AUTOSAR XML (schema 4-2-2)
standard types defined: sint16, float32, uint8, boolean, uint16
package /STCW_pkg/STCW_swc
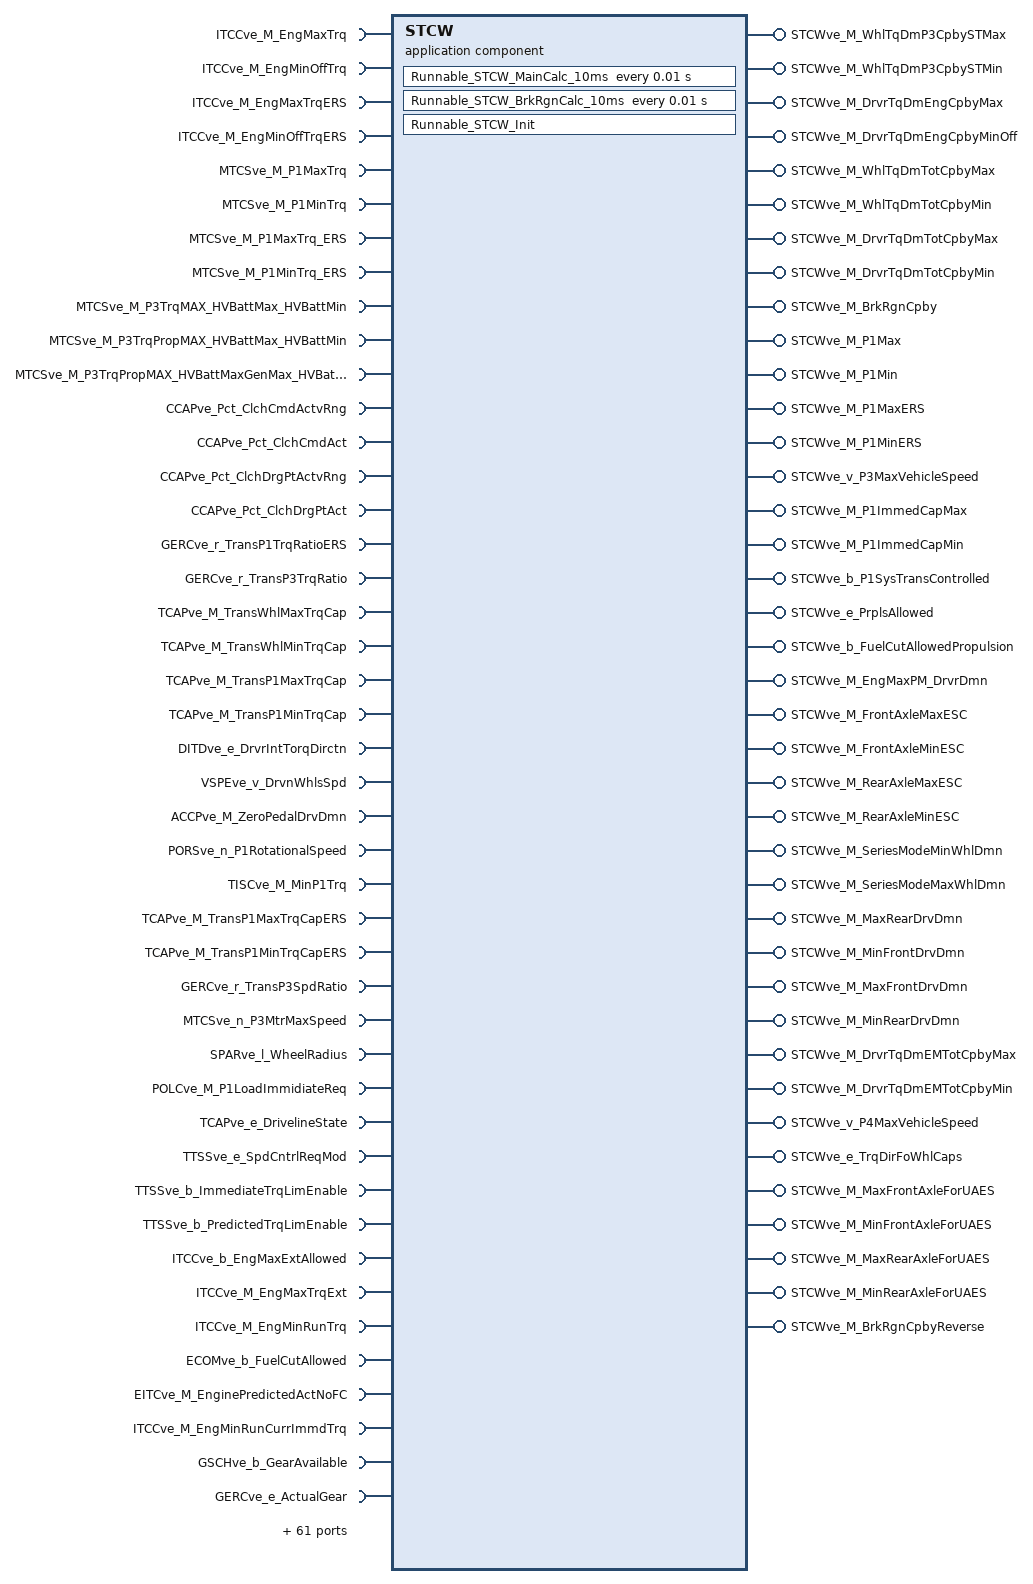
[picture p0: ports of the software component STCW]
  application sw component type STCW
    105 x require port:
      ITCCve_M_EngMaxTrq: nonqueued-receiver-com-spec{data-element=ITCCve_M_EngMaxTrq, init-value=0}, required-interface=ITCCve_M_EngMaxTrq
      ITCCve_M_EngMinOffTrq: nonqueued-receiver-com-spec{data-element=ITCCve_M_EngMinOffTrq, init-value=0}, required-interface=ITCCve_M_EngMinOffTrq
      ITCCve_M_EngMaxTrqERS: nonqueued-receiver-com-spec{data-element=ITCCve_M_EngMaxTrqERS, init-value=0}, required-interface=ITCCve_M_EngMaxTrqERS
      ITCCve_M_EngMinOffTrqERS: nonqueued-receiver-com-spec{data-element=ITCCve_M_EngMinOffTrqERS, init-value=0}, required-interface=ITCCve_M_EngMinOffTrqERS
      MTCSve_M_P1MaxTrq: nonqueued-receiver-com-spec{data-element=MTCSve_M_P1MaxTrq, init-value=0}, required-interface=MTCSve_M_P1MaxTrq
      MTCSve_M_P1MinTrq: nonqueued-receiver-com-spec{data-element=MTCSve_M_P1MinTrq, init-value=0}, required-interface=MTCSve_M_P1MinTrq
      MTCSve_M_P1MaxTrq_ERS: nonqueued-receiver-com-spec{data-element=MTCSve_M_P1MaxTrq_ERS, init-value=0}, required-interface=MTCSve_M_P1MaxTrq_ERS
      MTCSve_M_P1MinTrq_ERS: nonqueued-receiver-com-spec{data-element=MTCSve_M_P1MinTrq_ERS, init-value=0}, required-interface=MTCSve_M_P1MinTrq_ERS
      MTCSve_M_P3TrqMAX_HVBattMax_HVBattMin: nonqueued-receiver-com-spec{data-element=MTCSve_M_P3TrqMAX_HVBattMax_HVBattMin, init-value=0}, required-interface=MTCSve_M_P3TrqMAX_HVBattMax_HVBattMin
      MTCSve_M_P3TrqPropMAX_HVBattMax_HVBattMin: nonqueued-receiver-com-spec{data-element=MTCSve_M_P3TrqPropMAX_HVBattMax_HVBattMin, init-value=0}, required-interface=MTCSve_M_P3TrqPropMAX_HVBattMax_HVBattMin
      MTCSve_M_P3TrqPropMAX_HVBattMaxGenMax_HVBattMin: nonqueued-receiver-com-spec{data-element=MTCSve_M_P3TrqPropMAX_HVBattMaxGenMax_HVBattMin, init-value=0}, required-interface=MTCSve_M_P3TrqPropMAX_HVBattMaxGenMax_HVBattMin
      CCAPve_Pct_ClchCmdActvRng: nonqueued-receiver-com-spec{data-element=CCAPve_Pct_ClchCmdActvRng, init-value=0}, required-interface=CCAPve_Pct_ClchCmdActvRng
      CCAPve_Pct_ClchCmdAct: nonqueued-receiver-com-spec{data-element=CCAPve_Pct_ClchCmdAct, init-value=0}, required-interface=CCAPve_Pct_ClchCmdAct
      CCAPve_Pct_ClchDrgPtActvRng: nonqueued-receiver-com-spec{data-element=CCAPve_Pct_ClchDrgPtActvRng, init-value=0}, required-interface=CCAPve_Pct_ClchDrgPtActvRng
      CCAPve_Pct_ClchDrgPtAct: nonqueued-receiver-com-spec{data-element=CCAPve_Pct_ClchDrgPtAct, init-value=0}, required-interface=CCAPve_Pct_ClchDrgPtAct
      GERCve_r_TransP1TrqRatioERS: nonqueued-receiver-com-spec{data-element=GERCve_r_TransP1TrqRatioERS, init-value=0}, required-interface=GERCve_r_TransP1TrqRatioERS
      GERCve_r_TransP3TrqRatio: nonqueued-receiver-com-spec{data-element=GERCve_r_TransP3TrqRatio, init-value=0}, required-interface=GERCve_r_TransP3TrqRatio
      TCAPve_M_TransWhlMaxTrqCap: nonqueued-receiver-com-spec{data-element=TCAPve_M_TransWhlMaxTrqCap, init-value=0}, required-interface=TCAPve_M_TransWhlMaxTrqCap
      TCAPve_M_TransWhlMinTrqCap: nonqueued-receiver-com-spec{data-element=TCAPve_M_TransWhlMinTrqCap, init-value=0}, required-interface=TCAPve_M_TransWhlMinTrqCap
      TCAPve_M_TransP1MaxTrqCap: nonqueued-receiver-com-spec{data-element=TCAPve_M_TransP1MaxTrqCap, init-value=0}, required-interface=TCAPve_M_TransP1MaxTrqCap
      TCAPve_M_TransP1MinTrqCap: nonqueued-receiver-com-spec{data-element=TCAPve_M_TransP1MinTrqCap, init-value=0}, required-interface=TCAPve_M_TransP1MinTrqCap
      DITDve_e_DrvrIntTorqDirctn: nonqueued-receiver-com-spec{data-element=DITDve_e_DrvrIntTorqDirctn, init-value=DITDce_e_Undefined}, required-interface=DITDve_e_DrvrIntTorqDirctn
      VSPEve_v_DrvnWhlsSpd: nonqueued-receiver-com-spec{data-element=VSPEve_v_DrvnWhlsSpd, init-value=0}, required-interface=VSPEve_v_DrvnWhlsSpd
      ACCPve_M_ZeroPedalDrvDmn: nonqueued-receiver-com-spec{data-element=ACCPve_M_ZeroPedalDrvDmn, init-value=0}, required-interface=ACCPve_M_ZeroPedalDrvDmn
      PORSve_n_P1RotationalSpeed: nonqueued-receiver-com-spec{data-element=PORSve_n_P1RotationalSpeed, init-value=0}, required-interface=PORSve_n_P1RotationalSpeed
      TISCve_M_MinP1Trq: nonqueued-receiver-com-spec{data-element=TISCve_M_MinP1Trq, init-value=0}, required-interface=TISCve_M_MinP1Trq
      TCAPve_M_TransP1MaxTrqCapERS: nonqueued-receiver-com-spec{data-element=TCAPve_M_TransP1MaxTrqCapERS, init-value=0}, required-interface=TCAPve_M_TransP1MaxTrqCapERS
      TCAPve_M_TransP1MinTrqCapERS: nonqueued-receiver-com-spec{data-element=TCAPve_M_TransP1MinTrqCapERS, init-value=0}, required-interface=TCAPve_M_TransP1MinTrqCapERS
      GERCve_r_TransP3SpdRatio: nonqueued-receiver-com-spec{data-element=GERCve_r_TransP3SpdRatio, init-value=0}, required-interface=GERCve_r_TransP3SpdRatio
      MTCSve_n_P3MtrMaxSpeed: nonqueued-receiver-com-spec{data-element=MTCSve_n_P3MtrMaxSpeed, init-value=0}, required-interface=MTCSve_n_P3MtrMaxSpeed
      SPARve_l_WheelRadius: nonqueued-receiver-com-spec{data-element=SPARve_l_WheelRadius, init-value=0}, required-interface=SPARve_l_WheelRadius
      POLCve_M_P1LoadImmidiateReq: nonqueued-receiver-com-spec{data-element=POLCve_M_P1LoadImmidiateReq, init-value=0}, required-interface=POLCve_M_P1LoadImmidiateReq
      TCAPve_e_DrivelineState: nonqueued-receiver-com-spec{data-element=TCAPve_e_DrivelineState, init-value=TCAPce_e_Open}, required-interface=TCAPve_e_DrivelineState
      TTSSve_e_SpdCntrlReqMod: nonqueued-receiver-com-spec{data-element=TTSSve_e_SpdCntrlReqMod, init-value=TTSSce_e_SpdCntrlInactive}, required-interface=TTSSve_e_SpdCntrlReqMod
      TTSSve_b_ImmediateTrqLimEnable: nonqueued-receiver-com-spec{data-element=TTSSve_b_ImmediateTrqLimEnable, init-value=0}, required-interface=TTSSve_b_ImmediateTrqLimEnable
      TTSSve_b_PredictedTrqLimEnable: nonqueued-receiver-com-spec{data-element=TTSSve_b_PredictedTrqLimEnable, init-value=0}, required-interface=TTSSve_b_PredictedTrqLimEnable
      ITCCve_b_EngMaxExtAllowed: nonqueued-receiver-com-spec{data-element=ITCCve_b_EngMaxExtAllowed, init-value=0}, required-interface=ITCCve_b_EngMaxExtAllowed
      ITCCve_M_EngMaxTrqExt: nonqueued-receiver-com-spec{data-element=ITCCve_M_EngMaxTrqExt, init-value=0}, required-interface=ITCCve_M_EngMaxTrqExt
      ITCCve_M_EngMinRunTrq: nonqueued-receiver-com-spec{data-element=ITCCve_M_EngMinRunTrq, init-value=0}, required-interface=ITCCve_M_EngMinRunTrq
      ECOMve_b_FuelCutAllowed: nonqueued-receiver-com-spec{data-element=ECOMve_b_FuelCutAllowed, init-value=0}, required-interface=ECOMve_b_FuelCutAllowed
      EITCve_M_EnginePredictedActNoFC: nonqueued-receiver-com-spec{data-element=EITCve_M_EnginePredictedActNoFC, init-value=0}, required-interface=EITCve_M_EnginePredictedActNoFC
      ITCCve_M_EngMinRunCurrImmdTrq: nonqueued-receiver-com-spec{data-element=ITCCve_M_EngMinRunCurrImmdTrq, init-value=0}, required-interface=ITCCve_M_EngMinRunCurrImmdTrq
      GSCHve_b_GearAvailable: nonqueued-receiver-com-spec{data-element=GSCHve_b_GearAvailable, init-value=0}, required-interface=GSCHve_b_GearAvailable
      GERCve_e_ActualGear: nonqueued-receiver-com-spec{data-element=GERCve_e_ActualGear, init-value=DGPSce_e_UndefinedGear}, required-interface=GERCve_e_ActualGear
      ITCCve_M_EngMinRunTrq_LT: nonqueued-receiver-com-spec{data-element=ITCCve_M_EngMinRunTrq_LT, init-value=0}, required-interface=ITCCve_M_EngMinRunTrq_LT
      DTOSve_M_CmdPrplsFiltWhlDmnImmediate: nonqueued-receiver-com-spec{data-element=DTOSve_M_CmdPrplsFiltWhlDmnImmediate, init-value=0}, required-interface=DTOSve_M_CmdPrplsFiltWhlDmnImmediate
      DOSRve_M_ForceChargeTorque: nonqueued-receiver-com-spec{data-element=DOSRve_M_ForceChargeTorque, init-value=0}, required-interface=DOSRve_M_ForceChargeTorque
      FDMAve_b_ForceBrakeRegenerationTorqueOff: nonqueued-receiver-com-spec{data-element=FDMAve_b_ForceBrakeRegenerationTorqueOff, init-value=0}, required-interface=FDMAve_b_ForceBrakeRegenerationTorqueOff
      SWINve_b_GearShiftActive: nonqueued-receiver-com-spec{data-element=SWINve_b_GearShiftActive, init-value=0}, required-interface=SWINve_b_GearShiftActive
      DPSCve_e_VehicleReqState: nonqueued-receiver-com-spec{data-element=DPSCve_e_VehicleReqState, init-value=DPSCce_e_VehMd_Off}, required-interface=DPSCve_e_VehicleReqState
      PWRMve_e_SysPwrMd: nonqueued-receiver-com-spec{data-element=PWRMve_e_SysPwrMd, init-value=PWRMce_e_Lock}, required-interface=PWRMve_e_SysPwrMd
      PAFCve_e_ParkLockStatus: nonqueued-receiver-com-spec{data-element=PAFCve_e_ParkLockStatus, init-value=SWINce_e_ParkLockUndefined}, required-interface=PAFCve_e_ParkLockStatus
      FDMAve_b_ForcePropulsionAllowedToNotAllowed: nonqueued-receiver-com-spec{data-element=FDMAve_b_ForcePropulsionAllowedToNotAllowed, init-value=0}, required-interface=FDMAve_b_ForcePropulsionAllowedToNotAllowed
      DPSCve_e_VehicleActState: nonqueued-receiver-com-spec{data-element=DPSCve_e_VehicleActState, init-value=DPSCce_e_VehMd_Off}, required-interface=DPSCve_e_VehicleActState
      ECOMve_b_FuelCutGearShiftAllowed: nonqueued-receiver-com-spec{data-element=ECOMve_b_FuelCutGearShiftAllowed, init-value=0}, required-interface=ECOMve_b_FuelCutGearShiftAllowed
      DTOSve_b_FastResponseRequest: nonqueued-receiver-com-spec{data-element=DTOSve_b_FastResponseRequest, init-value=0}, required-interface=DTOSve_b_FastResponseRequest
      MTCSve_M_P3TrqPropMAX_GenMax_HVBattMin: nonqueued-receiver-com-spec{data-element=MTCSve_M_P3TrqPropMAX_GenMax_HVBattMin, init-value=0}, required-interface=MTCSve_M_P3TrqPropMAX_GenMax_HVBattMin
      MTCSve_M_P3TrqMAX_HVBattMaxGenMax_HVBattMin: nonqueued-receiver-com-spec{data-element=MTCSve_M_P3TrqMAX_HVBattMaxGenMax_HVBattMin, init-value=0}, required-interface=MTCSve_M_P3TrqMAX_HVBattMaxGenMax_HVBattMin
      MTCSve_M_P4TrqMAX_HVBattMaxGenMax_HVBattMin: nonqueued-receiver-com-spec{data-element=MTCSve_M_P4TrqMAX_HVBattMaxGenMax_HVBattMin, init-value=0}, required-interface=MTCSve_M_P4TrqMAX_HVBattMaxGenMax_HVBattMin
      BOREve_M_MaxBoostRequest: nonqueued-receiver-com-spec{data-element=BOREve_M_MaxBoostRequest, init-value=0}, required-interface=BOREve_M_MaxBoostRequest
      MTCSve_M_P4TrqPropMAX_GenMax_HVBattMin: nonqueued-receiver-com-spec{data-element=MTCSve_M_P4TrqPropMAX_GenMax_HVBattMin, init-value=0}, required-interface=MTCSve_M_P4TrqPropMAX_GenMax_HVBattMin
      MTCSve_M_P4TrqPropMAX_HVBattMax_HVBattMin: nonqueued-receiver-com-spec{data-element=MTCSve_M_P4TrqPropMAX_HVBattMax_HVBattMin, init-value=0}, required-interface=MTCSve_M_P4TrqPropMAX_HVBattMax_HVBattMin
      MTCSve_M_P4TrqPropMAX_HVBattMaxGenMax_HVBattMin: nonqueued-receiver-com-spec{data-element=MTCSve_M_P4TrqPropMAX_HVBattMaxGenMax_HVBattMin, init-value=0}, required-interface=MTCSve_M_P4TrqPropMAX_HVBattMaxGenMax_HVBattMin
      VSPEve_v_RearAxleWheelSpeed: nonqueued-receiver-com-spec{data-element=VSPEve_v_RearAxleWheelSpeed, init-value=0}, required-interface=VSPEve_v_RearAxleWheelSpeed
      GERCve_r_TransP4TrqRatio: nonqueued-receiver-com-spec{data-element=GERCve_r_TransP4TrqRatio, init-value=0}, required-interface=GERCve_r_TransP4TrqRatio
      MTCSve_M_P4TrqMAX_HVBattMax_HVBattMin: nonqueued-receiver-com-spec{data-element=MTCSve_M_P4TrqMAX_HVBattMax_HVBattMin, init-value=0}, required-interface=MTCSve_M_P4TrqMAX_HVBattMax_HVBattMin
      MTCSve_M_P3TrqMIN_HVBattMax_HVBattMin: nonqueued-receiver-com-spec{data-element=MTCSve_M_P3TrqMIN_HVBattMax_HVBattMin, init-value=0}, required-interface=MTCSve_M_P3TrqMIN_HVBattMax_HVBattMin
      MTCSve_M_P3TrqMIN_HVBattMaxGenMax_HVBattMin: nonqueued-receiver-com-spec{data-element=MTCSve_M_P3TrqMIN_HVBattMaxGenMax_HVBattMin, init-value=0}, required-interface=MTCSve_M_P3TrqMIN_HVBattMaxGenMax_HVBattMin
      MTCSve_M_P3TrqPropMIN_GenMax_HVBattMin: nonqueued-receiver-com-spec{data-element=MTCSve_M_P3TrqPropMIN_GenMax_HVBattMin, init-value=0}, required-interface=MTCSve_M_P3TrqPropMIN_GenMax_HVBattMin
      MTCSve_M_P3TrqPropMIN_HVBattMax_HVBattMin: nonqueued-receiver-com-spec{data-element=MTCSve_M_P3TrqPropMIN_HVBattMax_HVBattMin, init-value=0}, required-interface=MTCSve_M_P3TrqPropMIN_HVBattMax_HVBattMin
      MTCSve_M_P3TrqPropMIN_HVBattMaxGenMax_HVBattMin: nonqueued-receiver-com-spec{data-element=MTCSve_M_P3TrqPropMIN_HVBattMaxGenMax_HVBattMin, init-value=0}, required-interface=MTCSve_M_P3TrqPropMIN_HVBattMaxGenMax_HVBattMin
      MTCSve_M_P4TrqMIN_HVBattMax_HVBattMin: nonqueued-receiver-com-spec{data-element=MTCSve_M_P4TrqMIN_HVBattMax_HVBattMin, init-value=0}, required-interface=MTCSve_M_P4TrqMIN_HVBattMax_HVBattMin
      MTCSve_M_P4TrqMIN_HVBattMaxGenMax_HVBattMin: nonqueued-receiver-com-spec{data-element=MTCSve_M_P4TrqMIN_HVBattMaxGenMax_HVBattMin, init-value=0}, required-interface=MTCSve_M_P4TrqMIN_HVBattMaxGenMax_HVBattMin
      MTCSve_M_P4TrqPropMIN_GenMax_HVBattMin: nonqueued-receiver-com-spec{data-element=MTCSve_M_P4TrqPropMIN_GenMax_HVBattMin, init-value=0}, required-interface=MTCSve_M_P4TrqPropMIN_GenMax_HVBattMin
      MTCSve_M_P4TrqPropMIN_HVBattMax_HVBattMin: nonqueued-receiver-com-spec{data-element=MTCSve_M_P4TrqPropMIN_HVBattMax_HVBattMin, init-value=0}, required-interface=MTCSve_M_P4TrqPropMIN_HVBattMax_HVBattMin
      MTCSve_M_P4TrqPropMIN_HVBattMaxGenMax_HVBattMin: nonqueued-receiver-com-spec{data-element=MTCSve_M_P4TrqPropMIN_HVBattMaxGenMax_HVBattMin, init-value=0}, required-interface=MTCSve_M_P4TrqPropMIN_HVBattMaxGenMax_HVBattMin
      MTCSve_M_P3BrakeRegenMAXCap: nonqueued-receiver-com-spec{data-element=MTCSve_M_P3BrakeRegenMAXCap, init-value=0}, required-interface=MTCSve_M_P3BrakeRegenMAXCap
      MTCSve_M_P3BrakeRegenMINCap: nonqueued-receiver-com-spec{data-element=MTCSve_M_P3BrakeRegenMINCap, init-value=0}, required-interface=MTCSve_M_P3BrakeRegenMINCap
      MTCSve_M_P4BrakeRegenMAXCap: nonqueued-receiver-com-spec{data-element=MTCSve_M_P4BrakeRegenMAXCap, init-value=0}, required-interface=MTCSve_M_P4BrakeRegenMAXCap
      MTCSve_M_P4BrakeRegenMINCap: nonqueued-receiver-com-spec{data-element=MTCSve_M_P4BrakeRegenMINCap, init-value=0}, required-interface=MTCSve_M_P4BrakeRegenMINCap
      GERCve_r_TransP4SpdRatio: nonqueued-receiver-com-spec{data-element=GERCve_r_TransP4SpdRatio, init-value=0}, required-interface=GERCve_r_TransP4SpdRatio
      MTCSve_n_P4MtrMaxSpeed: nonqueued-receiver-com-spec{data-element=MTCSve_n_P4MtrMaxSpeed, init-value=0}, required-interface=MTCSve_n_P4MtrMaxSpeed
      MTCSve_M_P3LTrqPropMAX_HVBattMaxGenMax_HVBattMin: nonqueued-receiver-com-spec{data-element=MTCSve_M_P3LTrqPropMAX_HVBattMaxGenMax_HVBattMin, init-value=0}, required-interface=MTCSve_M_P3LTrqPropMAX_HVBattMaxGenMax_HVBattMin
      MTCSve_M_P3LTrqPropMIN_HVBattMaxGenMax_HVBattMin: nonqueued-receiver-com-spec{data-element=MTCSve_M_P3LTrqPropMIN_HVBattMaxGenMax_HVBattMin, init-value=0}, required-interface=MTCSve_M_P3LTrqPropMIN_HVBattMaxGenMax_HVBattMin
      MTCSve_M_P3RTrqPropMAX_HVBattMaxGenMax_HVBattMin: nonqueued-receiver-com-spec{data-element=MTCSve_M_P3RTrqPropMAX_HVBattMaxGenMax_HVBattMin, init-value=0}, required-interface=MTCSve_M_P3RTrqPropMAX_HVBattMaxGenMax_HVBattMin
      MTCSve_M_P3RTrqPropMIN_HVBattMaxGenMax_HVBattMin: nonqueued-receiver-com-spec{data-element=MTCSve_M_P3RTrqPropMIN_HVBattMaxGenMax_HVBattMin, init-value=0}, required-interface=MTCSve_M_P3RTrqPropMIN_HVBattMaxGenMax_HVBattMin
      MTCSve_M_P4LTrqPropMAX_HVBattMaxGenMax_HVBattMin: nonqueued-receiver-com-spec{data-element=MTCSve_M_P4LTrqPropMAX_HVBattMaxGenMax_HVBattMin, init-value=0}, required-interface=MTCSve_M_P4LTrqPropMAX_HVBattMaxGenMax_HVBattMin
      MTCSve_M_P4LTrqPropMIN_HVBattMaxGenMax_HVBattMin: nonqueued-receiver-com-spec{data-element=MTCSve_M_P4LTrqPropMIN_HVBattMaxGenMax_HVBattMin, init-value=0}, required-interface=MTCSve_M_P4LTrqPropMIN_HVBattMaxGenMax_HVBattMin
      MTCSve_M_P4RTrqPropMAX_HVBattMaxGenMax_HVBattMin: nonqueued-receiver-com-spec{data-element=MTCSve_M_P4RTrqPropMAX_HVBattMaxGenMax_HVBattMin, init-value=0}, required-interface=MTCSve_M_P4RTrqPropMAX_HVBattMaxGenMax_HVBattMin
      MTCSve_M_P4RTrqPropMIN_HVBattMaxGenMax_HVBattMin: nonqueued-receiver-com-spec{data-element=MTCSve_M_P4RTrqPropMIN_HVBattMaxGenMax_HVBattMin, init-value=0}, required-interface=MTCSve_M_P4RTrqPropMIN_HVBattMaxGenMax_HVBattMin
      TCAPve_M_TransP3MtrMaxTrqCap: nonqueued-receiver-com-spec{data-element=TCAPve_M_TransP3MtrMaxTrqCap, init-value=0}, required-interface=TCAPve_M_TransP3MtrMaxTrqCap
      TCAPve_M_TransP3MtrMinTrqCap: nonqueued-receiver-com-spec{data-element=TCAPve_M_TransP3MtrMinTrqCap, init-value=0}, required-interface=TCAPve_M_TransP3MtrMinTrqCap
      TCAPve_M_TransP4MtrMaxTrqCap: nonqueued-receiver-com-spec{data-element=TCAPve_M_TransP4MtrMaxTrqCap, init-value=0}, required-interface=TCAPve_M_TransP4MtrMaxTrqCap
      TCAPve_M_TransP4MtrMinTrqCap: nonqueued-receiver-com-spec{data-element=TCAPve_M_TransP4MtrMinTrqCap, init-value=0}, required-interface=TCAPve_M_TransP4MtrMinTrqCap
      SWINve_M_P3LMtrSTCpbyMax: nonqueued-receiver-com-spec{data-element=SWINve_M_P3LMtrSTCpbyMax, init-value=0}, required-interface=SWINve_M_P3LMtrSTCpbyMax
      SWINve_M_P3LMtrSTCpbyMin: nonqueued-receiver-com-spec{data-element=SWINve_M_P3LMtrSTCpbyMin, init-value=0}, required-interface=SWINve_M_P3LMtrSTCpbyMin
      SWINve_M_P3RMtrSTCpbyMax: nonqueued-receiver-com-spec{data-element=SWINve_M_P3RMtrSTCpbyMax, init-value=0}, required-interface=SWINve_M_P3RMtrSTCpbyMax
      SWINve_M_P3RMtrSTCpbyMin: nonqueued-receiver-com-spec{data-element=SWINve_M_P3RMtrSTCpbyMin, init-value=0}, required-interface=SWINve_M_P3RMtrSTCpbyMin
      SWINve_M_P4LMtrSTCpbyMax: nonqueued-receiver-com-spec{data-element=SWINve_M_P4LMtrSTCpbyMax, init-value=0}, required-interface=SWINve_M_P4LMtrSTCpbyMax
      SWINve_M_P4LMtrSTCpbyMin: nonqueued-receiver-com-spec{data-element=SWINve_M_P4LMtrSTCpbyMin, init-value=0}, required-interface=SWINve_M_P4LMtrSTCpbyMin
      SWINve_M_P4RMtrSTCpbyMax: nonqueued-receiver-com-spec{data-element=SWINve_M_P4RMtrSTCpbyMax, init-value=0}, required-interface=SWINve_M_P4RMtrSTCpbyMax
      SWINve_M_P4RMtrSTCpbyMin: nonqueued-receiver-com-spec{data-element=SWINve_M_P4RMtrSTCpbyMin, init-value=0}, required-interface=SWINve_M_P4RMtrSTCpbyMin
      TGSPve_b_GearShiftUpFlag: nonqueued-receiver-com-spec{data-element=TGSPve_b_GearShiftUpFlag, init-value=0}, required-interface=TGSPve_b_GearShiftUpFlag
      ADCIve_M_AdptvCruiseTorqueReq: nonqueued-receiver-com-spec{data-element=ADCIve_M_AdptvCruiseTorqueReq, init-value=0}, required-interface=ADCIve_M_AdptvCruiseTorqueReq
      WDMMve_b_RearMotorAvailable: nonqueued-receiver-com-spec{data-element=WDMMve_b_RearMotorAvailable, init-value=0}, required-interface=WDMMve_b_RearMotorAvailable
    39 x provide port:
      STCWve_M_WhlTqDmP3CpbySTMax: nonqueued-sender-com-spec{data-element=STCWve_M_WhlTqDmP3CpbySTMax, init-value=0}, provided-interface=STCWve_M_WhlTqDmP3CpbySTMax
      STCWve_M_WhlTqDmP3CpbySTMin: nonqueued-sender-com-spec{data-element=STCWve_M_WhlTqDmP3CpbySTMin, init-value=0}, provided-interface=STCWve_M_WhlTqDmP3CpbySTMin
      STCWve_M_DrvrTqDmEngCpbyMax: nonqueued-sender-com-spec{data-element=STCWve_M_DrvrTqDmEngCpbyMax, init-value=0}, provided-interface=STCWve_M_DrvrTqDmEngCpbyMax
      STCWve_M_DrvrTqDmEngCpbyMinOff: nonqueued-sender-com-spec{data-element=STCWve_M_DrvrTqDmEngCpbyMinOff, init-value=0}, provided-interface=STCWve_M_DrvrTqDmEngCpbyMinOff
      STCWve_M_WhlTqDmTotCpbyMax: nonqueued-sender-com-spec{data-element=STCWve_M_WhlTqDmTotCpbyMax, init-value=0}, provided-interface=STCWve_M_WhlTqDmTotCpbyMax
      STCWve_M_WhlTqDmTotCpbyMin: nonqueued-sender-com-spec{data-element=STCWve_M_WhlTqDmTotCpbyMin, init-value=0}, provided-interface=STCWve_M_WhlTqDmTotCpbyMin
      STCWve_M_DrvrTqDmTotCpbyMax: nonqueued-sender-com-spec{data-element=STCWve_M_DrvrTqDmTotCpbyMax, init-value=0}, provided-interface=STCWve_M_DrvrTqDmTotCpbyMax
      STCWve_M_DrvrTqDmTotCpbyMin: nonqueued-sender-com-spec{data-element=STCWve_M_DrvrTqDmTotCpbyMin, init-value=0}, provided-interface=STCWve_M_DrvrTqDmTotCpbyMin
      STCWve_M_BrkRgnCpby: nonqueued-sender-com-spec{data-element=STCWve_M_BrkRgnCpby, init-value=0}, provided-interface=STCWve_M_BrkRgnCpby
      STCWve_M_P1Max: nonqueued-sender-com-spec{data-element=STCWve_M_P1Max, init-value=0}, provided-interface=STCWve_M_P1Max
      STCWve_M_P1Min: nonqueued-sender-com-spec{data-element=STCWve_M_P1Min, init-value=0}, provided-interface=STCWve_M_P1Min
      STCWve_M_P1MaxERS: nonqueued-sender-com-spec{data-element=STCWve_M_P1MaxERS, init-value=0}, provided-interface=STCWve_M_P1MaxERS
      STCWve_M_P1MinERS: nonqueued-sender-com-spec{data-element=STCWve_M_P1MinERS, init-value=0}, provided-interface=STCWve_M_P1MinERS
      STCWve_v_P3MaxVehicleSpeed: nonqueued-sender-com-spec{data-element=STCWve_v_P3MaxVehicleSpeed, init-value=0}, provided-interface=STCWve_v_P3MaxVehicleSpeed
      STCWve_M_P1ImmedCapMax: nonqueued-sender-com-spec{data-element=STCWve_M_P1ImmedCapMax, init-value=0}, provided-interface=STCWve_M_P1ImmedCapMax
      STCWve_M_P1ImmedCapMin: nonqueued-sender-com-spec{data-element=STCWve_M_P1ImmedCapMin, init-value=0}, provided-interface=STCWve_M_P1ImmedCapMin
      STCWve_b_P1SysTransControlled: nonqueued-sender-com-spec{data-element=STCWve_b_P1SysTransControlled, init-value=0}, provided-interface=STCWve_b_P1SysTransControlled
      STCWve_e_PrplsAllowed: nonqueued-sender-com-spec{data-element=STCWve_e_PrplsAllowed, init-value=DPSCce_e_PrplsNotAllowed}, provided-interface=STCWve_e_PrplsAllowed
      STCWve_b_FuelCutAllowedPropulsion: nonqueued-sender-com-spec{data-element=STCWve_b_FuelCutAllowedPropulsion, init-value=0}, provided-interface=STCWve_b_FuelCutAllowedPropulsion
      STCWve_M_EngMaxPM_DrvrDmn: nonqueued-sender-com-spec{data-element=STCWve_M_EngMaxPM_DrvrDmn, init-value=0}, provided-interface=STCWve_M_EngMaxPM_DrvrDmn
      STCWve_M_FrontAxleMaxESC: nonqueued-sender-com-spec{data-element=STCWve_M_FrontAxleMaxESC, init-value=0}, provided-interface=STCWve_M_FrontAxleMaxESC
      STCWve_M_FrontAxleMinESC: nonqueued-sender-com-spec{data-element=STCWve_M_FrontAxleMinESC, init-value=0}, provided-interface=STCWve_M_FrontAxleMinESC
      STCWve_M_RearAxleMaxESC: nonqueued-sender-com-spec{data-element=STCWve_M_RearAxleMaxESC, init-value=0}, provided-interface=STCWve_M_RearAxleMaxESC
      STCWve_M_RearAxleMinESC: nonqueued-sender-com-spec{data-element=STCWve_M_RearAxleMinESC, init-value=0}, provided-interface=STCWve_M_RearAxleMinESC
      STCWve_M_SeriesModeMinWhlDmn: nonqueued-sender-com-spec{data-element=STCWve_M_SeriesModeMinWhlDmn, init-value=0}, provided-interface=STCWve_M_SeriesModeMinWhlDmn
      STCWve_M_SeriesModeMaxWhlDmn: nonqueued-sender-com-spec{data-element=STCWve_M_SeriesModeMaxWhlDmn, init-value=0}, provided-interface=STCWve_M_SeriesModeMaxWhlDmn
      STCWve_M_MaxRearDrvDmn: nonqueued-sender-com-spec{data-element=STCWve_M_MaxRearDrvDmn, init-value=0}, provided-interface=STCWve_M_MaxRearDrvDmn
      STCWve_M_MinFrontDrvDmn: nonqueued-sender-com-spec{data-element=STCWve_M_MinFrontDrvDmn, init-value=0}, provided-interface=STCWve_M_MinFrontDrvDmn
      STCWve_M_MaxFrontDrvDmn: nonqueued-sender-com-spec{data-element=STCWve_M_MaxFrontDrvDmn, init-value=0}, provided-interface=STCWve_M_MaxFrontDrvDmn
      STCWve_M_MinRearDrvDmn: nonqueued-sender-com-spec{data-element=STCWve_M_MinRearDrvDmn, init-value=0}, provided-interface=STCWve_M_MinRearDrvDmn
      STCWve_M_DrvrTqDmEMTotCpbyMax: nonqueued-sender-com-spec{data-element=STCWve_M_DrvrTqDmEMTotCpbyMax, init-value=0}, provided-interface=STCWve_M_DrvrTqDmEMTotCpbyMax
      STCWve_M_DrvrTqDmEMTotCpbyMin: nonqueued-sender-com-spec{data-element=STCWve_M_DrvrTqDmEMTotCpbyMin, init-value=0}, provided-interface=STCWve_M_DrvrTqDmEMTotCpbyMin
      STCWve_v_P4MaxVehicleSpeed: nonqueued-sender-com-spec{data-element=STCWve_v_P4MaxVehicleSpeed, init-value=0}, provided-interface=STCWve_v_P4MaxVehicleSpeed
      STCWve_e_TrqDirFoWhlCaps: nonqueued-sender-com-spec{data-element=STCWve_e_TrqDirFoWhlCaps, init-value=DITDce_e_Undefined}, provided-interface=STCWve_e_TrqDirFoWhlCaps
      STCWve_M_MaxFrontAxleForUAES: nonqueued-sender-com-spec{data-element=STCWve_M_MaxFrontAxleForUAES, init-value=0}, provided-interface=STCWve_M_MaxFrontAxleForUAES
      STCWve_M_MinFrontAxleForUAES: nonqueued-sender-com-spec{data-element=STCWve_M_MinFrontAxleForUAES, init-value=0}, provided-interface=STCWve_M_MinFrontAxleForUAES
      STCWve_M_MaxRearAxleForUAES: nonqueued-sender-com-spec{data-element=STCWve_M_MaxRearAxleForUAES, init-value=0}, provided-interface=STCWve_M_MaxRearAxleForUAES
      STCWve_M_MinRearAxleForUAES: nonqueued-sender-com-spec{data-element=STCWve_M_MinRearAxleForUAES, init-value=0}, provided-interface=STCWve_M_MinRearAxleForUAES
      STCWve_M_BrkRgnCpbyReverse: nonqueued-sender-com-spec{data-element=STCWve_M_BrkRgnCpbyReverse, init-value=0}, provided-interface=STCWve_M_BrkRgnCpbyReverse
    behavior STCW: data-type-mapping=STCWDataTypeMappingsSet, handle-termination-and-restart=NO-SUPPORT
      ar-typed-per-instance-memorys:
        47 x data, all with sw-calibration-access=READ-ONLY:
          STCWve_M_DrvrTqDmEngCpbyMaxRaw: category=VALUE, type=T_M_Nm_Float32
          STCWve_M_WhlTqDmTotCpbyMaxRaw: category=VALUE, type=T_M_Nm_Float32
          STCWve_M_DrvrTqDmTotCpbyMaxRaw: category=VALUE, type=T_M_Nm_Float32
          STCWve_M_FrontAxleMaxESCRaw: category=VALUE, type=T_M_Nm_Float32
          STCWve_M_SeriesModeMinWhlDmnRaw: category=VALUE, type=T_M_Nm_Float32
          STCWve_M_MaxRearDrvDmnRaw: category=VALUE, type=T_M_Nm_Float32
          STCWve_M_DrvrTqDmEMTotCpbyMaxRaw: category=VALUE, type=T_M_Nm_Float32
          STCWve_M_DrvrTqDmEngCpbyMinOffRaw: category=VALUE, type=T_M_Nm_Float32
          STCWve_M_MinRearDrvDmnRaw: category=VALUE, type=T_M_Nm_Float32
          STCWve_M_MaxFrontDrvDmnRaw: category=VALUE, type=T_M_Nm_Float32
          STCWve_M_MinFrontDrvDmnRaw: category=VALUE, type=T_M_Nm_Float32
          STCWve_M_SeriesModeMaxWhlDmnRaw: category=VALUE, type=T_M_Nm_Float32
          STCWve_M_DrvrTqDmEMTotCpbyMinRaw: category=VALUE, type=T_M_Nm_Float32
          STCWve_M_WhlTqDmTotCpbyMinRaw: category=VALUE, type=T_M_Nm_Float32
          STCWve_M_DrvrTqDmTotCpbyMinRaw: category=VALUE, type=T_M_Nm_Float32
          STCWve_M_FrontAxleMinESCRaw: category=VALUE, type=T_M_Nm_Float32
          STCWve_M_EngMaxPM_DrvrDmnRaw: category=VALUE, type=T_M_Nm_Float32
          STCWve_M_RearAxleMaxESCRaw: category=VALUE, type=T_M_Nm_Float32
          STCWve_M_RearAxleMinESCRaw: category=VALUE, type=T_M_Nm_Float32
          STCWve_M_EngMin_ERS_PM: category=VALUE, type=T_M_Nm_Float32_n8000to8000  # Miniumum engine torque on wheels in driver torque domain
          STCWve_M_EngMax_ERS_PM: category=VALUE, type=T_M_Nm_Float32_n8000to8000  # Maximum Engine Torque on Wheels in driver torque domain
          STCWve_M_FilteredMaxCap: category=VALUE, type=T_M_Nm_Float32
          STCWve_M_FilteredMinCap: category=VALUE, type=T_M_Nm_Float32
          STCWva_M_WhlDmTiERSCaps: category=ARRAY, type=rt_Array_T_M_Nm_Float32_6
          STCWva_M_TiDrvrDmCaps: category=ARRAY, type=rt_Array_T_M_Nm_Float32_6
          STCWva_M_EngDrvDmnCaps: category=ARRAY, type=rt_Array_T_M_Nm_Float32_7
          STCWva_M_P4ElMtrCpbysLimd: category=ARRAY, type=rt_Array_T_M_Nm_Float32_32  # **
          STCWve_M_BrkRgnRaw: category=VALUE, type=T_M_Nm_Float32
          STCWve_Pct_ClchCmd: category=VALUE, type=T_Pct_pct_10_1_s16
          STCWve_M_MinP1TrqAtWheel: category=VALUE, type=T_M_Nm_32_1_s16
          STCWve_M_P1MaxERSRaw: category=VALUE, type=T_M_Nm_32_1_s16
          STCWve_M_P1MaxRaw: category=VALUE, type=T_M_Nm_32_1_s16
          STCWve_M_P1MinERSRaw: category=VALUE, type=T_M_Nm_32_1_s16
          STCWve_M_P1MinRaw: category=VALUE, type=T_M_Nm_32_1_s16
          STCWve_M_P1Min_noTISC: category=VALUE, type=T_M_Nm_32_1_s16
          STCWve_M_P1MinERS_NoTISC: category=VALUE, type=T_M_Nm_32_1_s16
          STCWve_M_P1Max_NoTISC: category=VALUE, type=T_M_Nm_32_1_s16
          STCWve_M_P1MaxERS_NoTISC: category=VALUE, type=T_M_Nm_32_1_s16
          STCWve_r_PMAvailable: category=VALUE, type=T_r_NA_16384_1_s16
          STCWve_f_CluScalingFactor: category=VALUE, type=T_r_NA_16384_1_s16_0to1  # Raw value of actual clutch scaling factor
          STCWve_f_CluRelCDPDist: category=VALUE, type=T_r_NA_16384_1_s16_n1to1  # Relative clutch command distance from drag point in active range
          STCWve_b_EnableFuelCut: category=BOOLEAN, type=T_BOOLEAN  # Fuelcut Enabled by Gear and Engine speed dependent functionaluty in STCW
          STCWve_b_PrplsAllowedPowerModeOk: category=BOOLEAN, type=T_BOOLEAN  # Description: True if the Power mode is ok to set propulsion allowed. (Allways true if STCWke_b_PrplsAllowedDisablePowerModeDep is true.)
          STCWve_b_PrplsAllowedDirectionOk: category=BOOLEAN, type=T_BOOLEAN  # Description: True if the driver indended direction is ok to set propulsion allowed. (Allways true if STCWke_b_PrplsAllowedDisableDirectionDep is true.)
          STCWve_b_PrplsAllowedParkLockStsOk: category=BOOLEAN, type=T_BOOLEAN  # Is true when requirements for park lock is fulfilled to allow propulsion.
          STCWve_b_PrplsAllowedFunctionAction: category=BOOLEAN, type=T_BOOLEAN  # Description: True if no function action (degrading) is active (Allways true if STCWke_b_PrplsAllowedDisableFuncActDep is true.)
          STCWve_b_WheelCapsAllowed: category=BOOLEAN, type=T_BOOLEAN
      timing event Event_Runnable_STCW_MainCalc_10ms: start-on-event=Runnable_STCW_MainCalc_10ms, period=0.01
      timing event Event_Runnable_STCW_BrkRgnCalc_10ms: start-on-event=Runnable_STCW_BrkRgnCalc_10ms, period=0.01
      init event Init_Event: start-on-event=Runnable_STCW_Init
      explicit-inter-runnable-variables:
        data STCWve_M_BrkRgnBaseCpbyIRV: category=VALUE, sw-calibration-access=READ-ONLY, type=T_M_Nm_Float32, init-value=0
        data STCWve_b_VehDirOppositeDrvrReq: category=BOOLEAN, sw-calibration-access=READ-ONLY, type=T_BOOLEAN, init-value=0
      runnable Runnable_STCW_MainCalc_10ms
        data-receive-point-by-arguments:
          101 x access:
            IN_BOREve_M_MaxBoostRequest_BOREve_M_MaxBoostRequest: accessed-variable=BOREve_M_MaxBoostRequest.BOREve_M_MaxBoostRequest
            IN_CCAPve_Pct_ClchCmdAct_CCAPve_Pct_ClchCmdAct: accessed-variable=CCAPve_Pct_ClchCmdAct.CCAPve_Pct_ClchCmdAct
            IN_CCAPve_Pct_ClchCmdActvRng_CCAPve_Pct_ClchCmdActvRng: accessed-variable=CCAPve_Pct_ClchCmdActvRng.CCAPve_Pct_ClchCmdActvRng
            IN_CCAPve_Pct_ClchDrgPtAct_CCAPve_Pct_ClchDrgPtAct: accessed-variable=CCAPve_Pct_ClchDrgPtAct.CCAPve_Pct_ClchDrgPtAct
            IN_CCAPve_Pct_ClchDrgPtActvRng_CCAPve_Pct_ClchDrgPtActvRng: accessed-variable=CCAPve_Pct_ClchDrgPtActvRng.CCAPve_Pct_ClchDrgPtActvRng
            IN_DITDve_e_DrvrIntTorqDirctn_DITDve_e_DrvrIntTorqDirctn: accessed-variable=DITDve_e_DrvrIntTorqDirctn.DITDve_e_DrvrIntTorqDirctn
            IN_DOSRve_M_ForceChargeTorque_DOSRve_M_ForceChargeTorque: accessed-variable=DOSRve_M_ForceChargeTorque.DOSRve_M_ForceChargeTorque
            IN_DPSCve_e_VehicleActState_DPSCve_e_VehicleActState: accessed-variable=DPSCve_e_VehicleActState.DPSCve_e_VehicleActState
            IN_DPSCve_e_VehicleReqState_DPSCve_e_VehicleReqState: accessed-variable=DPSCve_e_VehicleReqState.DPSCve_e_VehicleReqState
            IN_DTOSve_M_CmdPrplsFiltWhlDmnImmediate_DTOSve_aea4d2e9ff300e98: accessed-variable=DTOSve_M_CmdPrplsFiltWhlDmnImmediate.DTOSve_M_CmdPrplsFiltWhlDmnImmediate
            IN_DTOSve_b_FastResponseRequest_DTOSve_b_FastResponseRequest: accessed-variable=DTOSve_b_FastResponseRequest.DTOSve_b_FastResponseRequest
            IN_ECOMve_b_FuelCutAllowed_ECOMve_b_FuelCutAllowed: accessed-variable=ECOMve_b_FuelCutAllowed.ECOMve_b_FuelCutAllowed
            IN_ECOMve_b_FuelCutGearShiftAllowed_ECOMve_b_F_034ff328fd17b210: accessed-variable=ECOMve_b_FuelCutGearShiftAllowed.ECOMve_b_FuelCutGearShiftAllowed
            IN_EITCve_M_EnginePredictedActNoFC_EITCve_M_En_38b9027d03a611aa: accessed-variable=EITCve_M_EnginePredictedActNoFC.EITCve_M_EnginePredictedActNoFC
            IN_FDMAve_b_ForcePropulsionAllowedToNotAllowed_4229e83c533d5ef2: accessed-variable=FDMAve_b_ForcePropulsionAllowedToNotAllowed.FDMAve_b_ForcePropulsionAllowedToNotAllowed
            IN_GERCve_e_ActualGear_GERCve_e_ActualGear: accessed-variable=GERCve_e_ActualGear.GERCve_e_ActualGear
            IN_GERCve_r_TransP1TrqRatioERS_GERCve_r_TransP1TrqRatioERS: accessed-variable=GERCve_r_TransP1TrqRatioERS.GERCve_r_TransP1TrqRatioERS
            IN_GERCve_r_TransP3SpdRatio_GERCve_r_TransP3SpdRatio: accessed-variable=GERCve_r_TransP3SpdRatio.GERCve_r_TransP3SpdRatio
            IN_GERCve_r_TransP3TrqRatio_GERCve_r_TransP3TrqRatio: accessed-variable=GERCve_r_TransP3TrqRatio.GERCve_r_TransP3TrqRatio
            IN_GERCve_r_TransP4SpdRatio_GERCve_r_TransP4SpdRatio: accessed-variable=GERCve_r_TransP4SpdRatio.GERCve_r_TransP4SpdRatio
            IN_GERCve_r_TransP4TrqRatio_GERCve_r_TransP4TrqRatio: accessed-variable=GERCve_r_TransP4TrqRatio.GERCve_r_TransP4TrqRatio
            IN_GSCHve_b_GearAvailable_GSCHve_b_GearAvailable: accessed-variable=GSCHve_b_GearAvailable.GSCHve_b_GearAvailable
            IN_ITCCve_M_EngMaxTrq_ITCCve_M_EngMaxTrq: accessed-variable=ITCCve_M_EngMaxTrq.ITCCve_M_EngMaxTrq
            IN_ITCCve_M_EngMaxTrqERS_ITCCve_M_EngMaxTrqERS: accessed-variable=ITCCve_M_EngMaxTrqERS.ITCCve_M_EngMaxTrqERS
            IN_ITCCve_M_EngMaxTrqExt_ITCCve_M_EngMaxTrqExt: accessed-variable=ITCCve_M_EngMaxTrqExt.ITCCve_M_EngMaxTrqExt
            IN_ITCCve_M_EngMinOffTrq_ITCCve_M_EngMinOffTrq: accessed-variable=ITCCve_M_EngMinOffTrq.ITCCve_M_EngMinOffTrq
            IN_ITCCve_M_EngMinOffTrqERS_ITCCve_M_EngMinOffTrqERS: accessed-variable=ITCCve_M_EngMinOffTrqERS.ITCCve_M_EngMinOffTrqERS
            IN_ITCCve_M_EngMinRunCurrImmdTrq_ITCCve_M_EngMinRunCurrImmdTrq: accessed-variable=ITCCve_M_EngMinRunCurrImmdTrq.ITCCve_M_EngMinRunCurrImmdTrq
            IN_ITCCve_M_EngMinRunTrq_ITCCve_M_EngMinRunTrq: accessed-variable=ITCCve_M_EngMinRunTrq.ITCCve_M_EngMinRunTrq
            IN_ITCCve_M_EngMinRunTrq_LT_ITCCve_M_EngMinRunTrq_LT: accessed-variable=ITCCve_M_EngMinRunTrq_LT.ITCCve_M_EngMinRunTrq_LT
            IN_ITCCve_b_EngMaxExtAllowed_ITCCve_b_EngMaxExtAllowed: accessed-variable=ITCCve_b_EngMaxExtAllowed.ITCCve_b_EngMaxExtAllowed
            IN_MTCSve_M_P1MaxTrq_MTCSve_M_P1MaxTrq: accessed-variable=MTCSve_M_P1MaxTrq.MTCSve_M_P1MaxTrq
            IN_MTCSve_M_P1MaxTrq_ERS_MTCSve_M_P1MaxTrq_ERS: accessed-variable=MTCSve_M_P1MaxTrq_ERS.MTCSve_M_P1MaxTrq_ERS
            IN_MTCSve_M_P1MinTrq_MTCSve_M_P1MinTrq: accessed-variable=MTCSve_M_P1MinTrq.MTCSve_M_P1MinTrq
            IN_MTCSve_M_P1MinTrq_ERS_MTCSve_M_P1MinTrq_ERS: accessed-variable=MTCSve_M_P1MinTrq_ERS.MTCSve_M_P1MinTrq_ERS
            IN_MTCSve_M_P3BrakeRegenMAXCap_MTCSve_M_P3BrakeRegenMAXCap: accessed-variable=MTCSve_M_P3BrakeRegenMAXCap.MTCSve_M_P3BrakeRegenMAXCap
            IN_MTCSve_M_P3BrakeRegenMINCap_MTCSve_M_P3BrakeRegenMINCap: accessed-variable=MTCSve_M_P3BrakeRegenMINCap.MTCSve_M_P3BrakeRegenMINCap
            IN_MTCSve_M_P3LTrqPropMAX_HVBattMaxGenMax_HVBa_5bfeeee9d5b1b485: accessed-variable=MTCSve_M_P3LTrqPropMAX_HVBattMaxGenMax_HVBattMin.MTCSve_M_P3LTrqPropMAX_HVBattMaxGenMax_HVBattMin
            IN_MTCSve_M_P3LTrqPropMIN_HVBattMaxGenMax_HVBa_18be3ecf443499bd: accessed-variable=MTCSve_M_P3LTrqPropMIN_HVBattMaxGenMax_HVBattMin.MTCSve_M_P3LTrqPropMIN_HVBattMaxGenMax_HVBattMin
            IN_MTCSve_M_P3RTrqPropMAX_HVBattMaxGenMax_HVBa_3d337635a952d36d: accessed-variable=MTCSve_M_P3RTrqPropMAX_HVBattMaxGenMax_HVBattMin.MTCSve_M_P3RTrqPropMAX_HVBattMaxGenMax_HVBattMin
            IN_MTCSve_M_P3RTrqPropMIN_HVBattMaxGenMax_HVBa_1f226608df3cc14c: accessed-variable=MTCSve_M_P3RTrqPropMIN_HVBattMaxGenMax_HVBattMin.MTCSve_M_P3RTrqPropMIN_HVBattMaxGenMax_HVBattMin
            IN_MTCSve_M_P3TrqMAX_HVBattMaxGenMax_HVBattMin_fb74f11e3e8142a9: accessed-variable=MTCSve_M_P3TrqMAX_HVBattMaxGenMax_HVBattMin.MTCSve_M_P3TrqMAX_HVBattMaxGenMax_HVBattMin
            IN_MTCSve_M_P3TrqMAX_HVBattMax_HVBattMin_MTCSv_3efda1285bcd6db6: accessed-variable=MTCSve_M_P3TrqMAX_HVBattMax_HVBattMin.MTCSve_M_P3TrqMAX_HVBattMax_HVBattMin
            IN_MTCSve_M_P3TrqMIN_HVBattMaxGenMax_HVBattMin_78bca856bc62e7b7: accessed-variable=MTCSve_M_P3TrqMIN_HVBattMaxGenMax_HVBattMin.MTCSve_M_P3TrqMIN_HVBattMaxGenMax_HVBattMin
            IN_MTCSve_M_P3TrqMIN_HVBattMax_HVBattMin_MTCSv_fdcb68e6f1097c6f: accessed-variable=MTCSve_M_P3TrqMIN_HVBattMax_HVBattMin.MTCSve_M_P3TrqMIN_HVBattMax_HVBattMin
            IN_MTCSve_M_P3TrqPropMAX_GenMax_HVBattMin_MTCS_584095f9a3085b28: accessed-variable=MTCSve_M_P3TrqPropMAX_GenMax_HVBattMin.MTCSve_M_P3TrqPropMAX_GenMax_HVBattMin
            IN_MTCSve_M_P3TrqPropMAX_HVBattMaxGenMax_HVBat_b48fe5309d351b4c: accessed-variable=MTCSve_M_P3TrqPropMAX_HVBattMaxGenMax_HVBattMin.MTCSve_M_P3TrqPropMAX_HVBattMaxGenMax_HVBattMin
            IN_MTCSve_M_P3TrqPropMAX_HVBattMax_HVBattMin_M_96baffff9bbc98a4: accessed-variable=MTCSve_M_P3TrqPropMAX_HVBattMax_HVBattMin.MTCSve_M_P3TrqPropMAX_HVBattMax_HVBattMin
            IN_MTCSve_M_P3TrqPropMIN_GenMax_HVBattMin_MTCS_94ee76f5014137fa: accessed-variable=MTCSve_M_P3TrqPropMIN_GenMax_HVBattMin.MTCSve_M_P3TrqPropMIN_GenMax_HVBattMin
            IN_MTCSve_M_P3TrqPropMIN_HVBattMaxGenMax_HVBat_045f534ba1ff622e: accessed-variable=MTCSve_M_P3TrqPropMIN_HVBattMaxGenMax_HVBattMin.MTCSve_M_P3TrqPropMIN_HVBattMaxGenMax_HVBattMin
            IN_MTCSve_M_P3TrqPropMIN_HVBattMax_HVBattMin_M_f23620ba436569b5: accessed-variable=MTCSve_M_P3TrqPropMIN_HVBattMax_HVBattMin.MTCSve_M_P3TrqPropMIN_HVBattMax_HVBattMin
            IN_MTCSve_M_P4BrakeRegenMAXCap_MTCSve_M_P4BrakeRegenMAXCap: accessed-variable=MTCSve_M_P4BrakeRegenMAXCap.MTCSve_M_P4BrakeRegenMAXCap
            IN_MTCSve_M_P4BrakeRegenMINCap_MTCSve_M_P4BrakeRegenMINCap: accessed-variable=MTCSve_M_P4BrakeRegenMINCap.MTCSve_M_P4BrakeRegenMINCap
            IN_MTCSve_M_P4LTrqPropMAX_HVBattMaxGenMax_HVBa_8ae8afe1e1ee5cf3: accessed-variable=MTCSve_M_P4LTrqPropMAX_HVBattMaxGenMax_HVBattMin.MTCSve_M_P4LTrqPropMAX_HVBattMaxGenMax_HVBattMin
            IN_MTCSve_M_P4LTrqPropMIN_HVBattMaxGenMax_HVBa_dc0bd8b4e5af27ad: accessed-variable=MTCSve_M_P4LTrqPropMIN_HVBattMaxGenMax_HVBattMin.MTCSve_M_P4LTrqPropMIN_HVBattMaxGenMax_HVBattMin
            IN_MTCSve_M_P4RTrqPropMAX_HVBattMaxGenMax_HVBa_b486083f02de5ed3: accessed-variable=MTCSve_M_P4RTrqPropMAX_HVBattMaxGenMax_HVBattMin.MTCSve_M_P4RTrqPropMAX_HVBattMaxGenMax_HVBattMin
            IN_MTCSve_M_P4RTrqPropMIN_HVBattMaxGenMax_HVBa_71c9101ac7aaf22f: accessed-variable=MTCSve_M_P4RTrqPropMIN_HVBattMaxGenMax_HVBattMin.MTCSve_M_P4RTrqPropMIN_HVBattMaxGenMax_HVBattMin
            IN_MTCSve_M_P4TrqMAX_HVBattMaxGenMax_HVBattMin_341ed25cf680dbff: accessed-variable=MTCSve_M_P4TrqMAX_HVBattMaxGenMax_HVBattMin.MTCSve_M_P4TrqMAX_HVBattMaxGenMax_HVBattMin
            IN_MTCSve_M_P4TrqMAX_HVBattMax_HVBattMin_MTCSv_f528a08eaa824c18: accessed-variable=MTCSve_M_P4TrqMAX_HVBattMax_HVBattMin.MTCSve_M_P4TrqMAX_HVBattMax_HVBattMin
            IN_MTCSve_M_P4TrqMIN_HVBattMaxGenMax_HVBattMin_d7e66492dcda490a: accessed-variable=MTCSve_M_P4TrqMIN_HVBattMaxGenMax_HVBattMin.MTCSve_M_P4TrqMIN_HVBattMaxGenMax_HVBattMin
            IN_MTCSve_M_P4TrqMIN_HVBattMax_HVBattMin_MTCSv_a56aee79acddd206: accessed-variable=MTCSve_M_P4TrqMIN_HVBattMax_HVBattMin.MTCSve_M_P4TrqMIN_HVBattMax_HVBattMin
            IN_MTCSve_M_P4TrqPropMAX_GenMax_HVBattMin_MTCS_ea4ab2e94fd3f592: accessed-variable=MTCSve_M_P4TrqPropMAX_GenMax_HVBattMin.MTCSve_M_P4TrqPropMAX_GenMax_HVBattMin
            IN_MTCSve_M_P4TrqPropMAX_HVBattMaxGenMax_HVBat_4fd7356678a87170: accessed-variable=MTCSve_M_P4TrqPropMAX_HVBattMaxGenMax_HVBattMin.MTCSve_M_P4TrqPropMAX_HVBattMaxGenMax_HVBattMin
            IN_MTCSve_M_P4TrqPropMAX_HVBattMax_HVBattMin_M_71d34e4212c36e8d: accessed-variable=MTCSve_M_P4TrqPropMAX_HVBattMax_HVBattMin.MTCSve_M_P4TrqPropMAX_HVBattMax_HVBattMin
            IN_MTCSve_M_P4TrqPropMIN_GenMax_HVBattMin_MTCS_06ddc7a1c8b3e11b: accessed-variable=MTCSve_M_P4TrqPropMIN_GenMax_HVBattMin.MTCSve_M_P4TrqPropMIN_GenMax_HVBattMin
            IN_MTCSve_M_P4TrqPropMIN_HVBattMaxGenMax_HVBat_63b285ff89392b96: accessed-variable=MTCSve_M_P4TrqPropMIN_HVBattMaxGenMax_HVBattMin.MTCSve_M_P4TrqPropMIN_HVBattMaxGenMax_HVBattMin
            IN_MTCSve_M_P4TrqPropMIN_HVBattMax_HVBattMin_M_5f6ccb5ff6a50490: accessed-variable=MTCSve_M_P4TrqPropMIN_HVBattMax_HVBattMin.MTCSve_M_P4TrqPropMIN_HVBattMax_HVBattMin
            IN_MTCSve_n_P3MtrMaxSpeed_MTCSve_n_P3MtrMaxSpeed: accessed-variable=MTCSve_n_P3MtrMaxSpeed.MTCSve_n_P3MtrMaxSpeed
            IN_MTCSve_n_P4MtrMaxSpeed_MTCSve_n_P4MtrMaxSpeed: accessed-variable=MTCSve_n_P4MtrMaxSpeed.MTCSve_n_P4MtrMaxSpeed
            IN_PAFCve_e_ParkLockStatus_PAFCve_e_ParkLockStatus: accessed-variable=PAFCve_e_ParkLockStatus.PAFCve_e_ParkLockStatus
            IN_POLCve_M_P1LoadImmidiateReq_POLCve_M_P1LoadImmidiateReq: accessed-variable=POLCve_M_P1LoadImmidiateReq.POLCve_M_P1LoadImmidiateReq
            IN_PORSve_n_P1RotationalSpeed_PORSve_n_P1RotationalSpeed: accessed-variable=PORSve_n_P1RotationalSpeed.PORSve_n_P1RotationalSpeed
            IN_PWRMve_e_SysPwrMd_PWRMve_e_SysPwrMd: accessed-variable=PWRMve_e_SysPwrMd.PWRMve_e_SysPwrMd
            IN_SPARve_l_WheelRadius_SPARve_l_WheelRadius: accessed-variable=SPARve_l_WheelRadius.SPARve_l_WheelRadius
            IN_SWINve_M_P3LMtrSTCpbyMax_SWINve_M_P3LMtrSTCpbyMax: accessed-variable=SWINve_M_P3LMtrSTCpbyMax.SWINve_M_P3LMtrSTCpbyMax
            IN_SWINve_M_P3LMtrSTCpbyMin_SWINve_M_P3LMtrSTCpbyMin: accessed-variable=SWINve_M_P3LMtrSTCpbyMin.SWINve_M_P3LMtrSTCpbyMin
            IN_SWINve_M_P3RMtrSTCpbyMax_SWINve_M_P3RMtrSTCpbyMax: accessed-variable=SWINve_M_P3RMtrSTCpbyMax.SWINve_M_P3RMtrSTCpbyMax
            IN_SWINve_M_P3RMtrSTCpbyMin_SWINve_M_P3RMtrSTCpbyMin: accessed-variable=SWINve_M_P3RMtrSTCpbyMin.SWINve_M_P3RMtrSTCpbyMin
            IN_SWINve_M_P4LMtrSTCpbyMax_SWINve_M_P4LMtrSTCpbyMax: accessed-variable=SWINve_M_P4LMtrSTCpbyMax.SWINve_M_P4LMtrSTCpbyMax
            IN_SWINve_M_P4LMtrSTCpbyMin_SWINve_M_P4LMtrSTCpbyMin: accessed-variable=SWINve_M_P4LMtrSTCpbyMin.SWINve_M_P4LMtrSTCpbyMin
            IN_SWINve_M_P4RMtrSTCpbyMax_SWINve_M_P4RMtrSTCpbyMax: accessed-variable=SWINve_M_P4RMtrSTCpbyMax.SWINve_M_P4RMtrSTCpbyMax
            IN_SWINve_M_P4RMtrSTCpbyMin_SWINve_M_P4RMtrSTCpbyMin: accessed-variable=SWINve_M_P4RMtrSTCpbyMin.SWINve_M_P4RMtrSTCpbyMin
            IN_SWINve_b_GearShiftActive_SWINve_b_GearShiftActive: accessed-variable=SWINve_b_GearShiftActive.SWINve_b_GearShiftActive
            IN_TCAPve_M_TransP1MaxTrqCap_TCAPve_M_TransP1MaxTrqCap: accessed-variable=TCAPve_M_TransP1MaxTrqCap.TCAPve_M_TransP1MaxTrqCap
            IN_TCAPve_M_TransP1MaxTrqCapERS_TCAPve_M_TransP1MaxTrqCapERS: accessed-variable=TCAPve_M_TransP1MaxTrqCapERS.TCAPve_M_TransP1MaxTrqCapERS
            IN_TCAPve_M_TransP1MinTrqCap_TCAPve_M_TransP1MinTrqCap: accessed-variable=TCAPve_M_TransP1MinTrqCap.TCAPve_M_TransP1MinTrqCap
            IN_TCAPve_M_TransP1MinTrqCapERS_TCAPve_M_TransP1MinTrqCapERS: accessed-variable=TCAPve_M_TransP1MinTrqCapERS.TCAPve_M_TransP1MinTrqCapERS
            IN_TCAPve_M_TransP3MtrMaxTrqCap_TCAPve_M_TransP3MtrMaxTrqCap: accessed-variable=TCAPve_M_TransP3MtrMaxTrqCap.TCAPve_M_TransP3MtrMaxTrqCap
            IN_TCAPve_M_TransP3MtrMinTrqCap_TCAPve_M_TransP3MtrMinTrqCap: accessed-variable=TCAPve_M_TransP3MtrMinTrqCap.TCAPve_M_TransP3MtrMinTrqCap
            IN_TCAPve_M_TransP4MtrMaxTrqCap_TCAPve_M_TransP4MtrMaxTrqCap: accessed-variable=TCAPve_M_TransP4MtrMaxTrqCap.TCAPve_M_TransP4MtrMaxTrqCap
            IN_TCAPve_M_TransP4MtrMinTrqCap_TCAPve_M_TransP4MtrMinTrqCap: accessed-variable=TCAPve_M_TransP4MtrMinTrqCap.TCAPve_M_TransP4MtrMinTrqCap
            IN_TCAPve_M_TransWhlMaxTrqCap_TCAPve_M_TransWhlMaxTrqCap: accessed-variable=TCAPve_M_TransWhlMaxTrqCap.TCAPve_M_TransWhlMaxTrqCap
            IN_TCAPve_M_TransWhlMinTrqCap_TCAPve_M_TransWhlMinTrqCap: accessed-variable=TCAPve_M_TransWhlMinTrqCap.TCAPve_M_TransWhlMinTrqCap
            IN_TCAPve_e_DrivelineState_TCAPve_e_DrivelineState: accessed-variable=TCAPve_e_DrivelineState.TCAPve_e_DrivelineState
            IN_TISCve_M_MinP1Trq_TISCve_M_MinP1Trq: accessed-variable=TISCve_M_MinP1Trq.TISCve_M_MinP1Trq
            IN_TTSSve_b_ImmediateTrqLimEnable_TTSSve_b_Imm_4b59aa12003a631c: accessed-variable=TTSSve_b_ImmediateTrqLimEnable.TTSSve_b_ImmediateTrqLimEnable
            IN_TTSSve_b_PredictedTrqLimEnable_TTSSve_b_Pre_62fe66925d7428f7: accessed-variable=TTSSve_b_PredictedTrqLimEnable.TTSSve_b_PredictedTrqLimEnable
            IN_TTSSve_e_SpdCntrlReqMod_TTSSve_e_SpdCntrlReqMod: accessed-variable=TTSSve_e_SpdCntrlReqMod.TTSSve_e_SpdCntrlReqMod
            IN_VSPEve_v_DrvnWhlsSpd_VSPEve_v_DrvnWhlsSpd: accessed-variable=VSPEve_v_DrvnWhlsSpd.VSPEve_v_DrvnWhlsSpd
            IN_VSPEve_v_RearAxleWheelSpeed_VSPEve_v_RearAxleWheelSpeed: accessed-variable=VSPEve_v_RearAxleWheelSpeed.VSPEve_v_RearAxleWheelSpeed
            IN_WDMMve_b_RearMotorAvailable_WDMMve_b_RearMotorAvailable: accessed-variable=WDMMve_b_RearMotorAvailable.WDMMve_b_RearMotorAvailable
        data-send-points:
          37 x access:
            OUT_STCWve_M_WhlTqDmP3CpbySTMax_STCWve_M_WhlTqDmP3CpbySTMax: accessed-variable=STCWve_M_WhlTqDmP3CpbySTMax.STCWve_M_WhlTqDmP3CpbySTMax
            OUT_STCWve_M_WhlTqDmP3CpbySTMin_STCWve_M_WhlTqDmP3CpbySTMin: accessed-variable=STCWve_M_WhlTqDmP3CpbySTMin.STCWve_M_WhlTqDmP3CpbySTMin
            OUT_STCWve_M_DrvrTqDmEngCpbyMax_STCWve_M_DrvrTqDmEngCpbyMax: accessed-variable=STCWve_M_DrvrTqDmEngCpbyMax.STCWve_M_DrvrTqDmEngCpbyMax
            OUT_STCWve_M_DrvrTqDmEngCpbyMinOff_STCWve_M_Dr_56a1bd35efca119f: accessed-variable=STCWve_M_DrvrTqDmEngCpbyMinOff.STCWve_M_DrvrTqDmEngCpbyMinOff
            OUT_STCWve_M_WhlTqDmTotCpbyMax_STCWve_M_WhlTqDmTotCpbyMax: accessed-variable=STCWve_M_WhlTqDmTotCpbyMax.STCWve_M_WhlTqDmTotCpbyMax
            OUT_STCWve_M_WhlTqDmTotCpbyMin_STCWve_M_WhlTqDmTotCpbyMin: accessed-variable=STCWve_M_WhlTqDmTotCpbyMin.STCWve_M_WhlTqDmTotCpbyMin
            OUT_STCWve_M_DrvrTqDmTotCpbyMax_STCWve_M_DrvrTqDmTotCpbyMax: accessed-variable=STCWve_M_DrvrTqDmTotCpbyMax.STCWve_M_DrvrTqDmTotCpbyMax
            OUT_STCWve_M_DrvrTqDmTotCpbyMin_STCWve_M_DrvrTqDmTotCpbyMin: accessed-variable=STCWve_M_DrvrTqDmTotCpbyMin.STCWve_M_DrvrTqDmTotCpbyMin
            OUT_STCWve_M_P1Max_STCWve_M_P1Max: accessed-variable=STCWve_M_P1Max.STCWve_M_P1Max
            OUT_STCWve_M_P1Min_STCWve_M_P1Min: accessed-variable=STCWve_M_P1Min.STCWve_M_P1Min
            OUT_STCWve_M_P1MaxERS_STCWve_M_P1MaxERS: accessed-variable=STCWve_M_P1MaxERS.STCWve_M_P1MaxERS
            OUT_STCWve_M_P1MinERS_STCWve_M_P1MinERS: accessed-variable=STCWve_M_P1MinERS.STCWve_M_P1MinERS
            OUT_STCWve_v_P3MaxVehicleSpeed_STCWve_v_P3MaxVehicleSpeed: accessed-variable=STCWve_v_P3MaxVehicleSpeed.STCWve_v_P3MaxVehicleSpeed
            OUT_STCWve_M_P1ImmedCapMax_STCWve_M_P1ImmedCapMax: accessed-variable=STCWve_M_P1ImmedCapMax.STCWve_M_P1ImmedCapMax
            OUT_STCWve_M_P1ImmedCapMin_STCWve_M_P1ImmedCapMin: accessed-variable=STCWve_M_P1ImmedCapMin.STCWve_M_P1ImmedCapMin
            OUT_STCWve_b_P1SysTransControlled_STCWve_b_P1SysTransControlled: accessed-variable=STCWve_b_P1SysTransControlled.STCWve_b_P1SysTransControlled
            OUT_STCWve_e_PrplsAllowed_STCWve_e_PrplsAllowed: accessed-variable=STCWve_e_PrplsAllowed.STCWve_e_PrplsAllowed
            OUT_STCWve_b_FuelCutAllowedPropulsion_STCWve_b_15af9595b1cfc823: accessed-variable=STCWve_b_FuelCutAllowedPropulsion.STCWve_b_FuelCutAllowedPropulsion
            OUT_STCWve_M_EngMaxPM_DrvrDmn_STCWve_M_EngMaxPM_DrvrDmn: accessed-variable=STCWve_M_EngMaxPM_DrvrDmn.STCWve_M_EngMaxPM_DrvrDmn
            OUT_STCWve_M_FrontAxleMaxESC_STCWve_M_FrontAxleMaxESC: accessed-variable=STCWve_M_FrontAxleMaxESC.STCWve_M_FrontAxleMaxESC
            OUT_STCWve_M_FrontAxleMinESC_STCWve_M_FrontAxleMinESC: accessed-variable=STCWve_M_FrontAxleMinESC.STCWve_M_FrontAxleMinESC
            OUT_STCWve_M_RearAxleMaxESC_STCWve_M_RearAxleMaxESC: accessed-variable=STCWve_M_RearAxleMaxESC.STCWve_M_RearAxleMaxESC
            OUT_STCWve_M_RearAxleMinESC_STCWve_M_RearAxleMinESC: accessed-variable=STCWve_M_RearAxleMinESC.STCWve_M_RearAxleMinESC
            OUT_STCWve_M_SeriesModeMinWhlDmn_STCWve_M_SeriesModeMinWhlDmn: accessed-variable=STCWve_M_SeriesModeMinWhlDmn.STCWve_M_SeriesModeMinWhlDmn
            OUT_STCWve_M_SeriesModeMaxWhlDmn_STCWve_M_SeriesModeMaxWhlDmn: accessed-variable=STCWve_M_SeriesModeMaxWhlDmn.STCWve_M_SeriesModeMaxWhlDmn
            OUT_STCWve_M_MaxRearDrvDmn_STCWve_M_MaxRearDrvDmn: accessed-variable=STCWve_M_MaxRearDrvDmn.STCWve_M_MaxRearDrvDmn
            OUT_STCWve_M_MinFrontDrvDmn_STCWve_M_MinFrontDrvDmn: accessed-variable=STCWve_M_MinFrontDrvDmn.STCWve_M_MinFrontDrvDmn
            OUT_STCWve_M_MaxFrontDrvDmn_STCWve_M_MaxFrontDrvDmn: accessed-variable=STCWve_M_MaxFrontDrvDmn.STCWve_M_MaxFrontDrvDmn
            OUT_STCWve_M_MinRearDrvDmn_STCWve_M_MinRearDrvDmn: accessed-variable=STCWve_M_MinRearDrvDmn.STCWve_M_MinRearDrvDmn
            OUT_STCWve_M_DrvrTqDmEMTotCpbyMax_STCWve_M_DrvrTqDmEMTotCpbyMax: accessed-variable=STCWve_M_DrvrTqDmEMTotCpbyMax.STCWve_M_DrvrTqDmEMTotCpbyMax
            OUT_STCWve_M_DrvrTqDmEMTotCpbyMin_STCWve_M_DrvrTqDmEMTotCpbyMin: accessed-variable=STCWve_M_DrvrTqDmEMTotCpbyMin.STCWve_M_DrvrTqDmEMTotCpbyMin
            OUT_STCWve_v_P4MaxVehicleSpeed_STCWve_v_P4MaxVehicleSpeed: accessed-variable=STCWve_v_P4MaxVehicleSpeed.STCWve_v_P4MaxVehicleSpeed
            OUT_STCWve_e_TrqDirFoWhlCaps_STCWve_e_TrqDirFoWhlCaps: accessed-variable=STCWve_e_TrqDirFoWhlCaps.STCWve_e_TrqDirFoWhlCaps
            OUT_STCWve_M_MaxFrontAxleForUAES_STCWve_M_MaxFrontAxleForUAES: accessed-variable=STCWve_M_MaxFrontAxleForUAES.STCWve_M_MaxFrontAxleForUAES
            OUT_STCWve_M_MinFrontAxleForUAES_STCWve_M_MinFrontAxleForUAES: accessed-variable=STCWve_M_MinFrontAxleForUAES.STCWve_M_MinFrontAxleForUAES
            OUT_STCWve_M_MaxRearAxleForUAES_STCWve_M_MaxRearAxleForUAES: accessed-variable=STCWve_M_MaxRearAxleForUAES.STCWve_M_MaxRearAxleForUAES
            OUT_STCWve_M_MinRearAxleForUAES_STCWve_M_MinRearAxleForUAES: accessed-variable=STCWve_M_MinRearAxleForUAES.STCWve_M_MinRearAxleForUAES
        173 x parameter access:
          SCALPRM_STCWie_M_DrvrTqDmEMTotCpbyMax_OV: accessed-parameter=STCWie_M_DrvrTqDmEMTotCpbyMax_OV
          SCALPRM_STCWie_M_DrvrTqDmEMTotCpbyMin_OV: accessed-parameter=STCWie_M_DrvrTqDmEMTotCpbyMin_OV
          SCALPRM_STCWie_M_EngMaxPM_DrvrDmn_OV: accessed-parameter=STCWie_M_EngMaxPM_DrvrDmn_OV
          SCALPRM_STCWie_M_MaxFrontTorqueWithoutBattLIimit_OV: accessed-parameter=STCWie_M_MaxFrontTorqueWithoutBattLIimit_OV
          SCALPRM_STCWie_M_MaxRearDrvDmn_OV: accessed-parameter=STCWie_M_MaxRearDrvDmn_OV
          SCALPRM_STCWie_M_MaxRearTorqueWithoutBattLIimit_OV: accessed-parameter=STCWie_M_MaxRearTorqueWithoutBattLIimit_OV
          SCALPRM_STCWie_M_MinFrontTorqueWithoutBattLIimit_OV: accessed-parameter=STCWie_M_MinFrontTorqueWithoutBattLIimit_OV
          SCALPRM_STCWie_M_MinRearDrvDmn_OV: accessed-parameter=STCWie_M_MinRearDrvDmn_OV
          SCALPRM_STCWie_M_MinRearTorqueWithoutBattLIimit_OV: accessed-parameter=STCWie_M_MinRearTorqueWithoutBattLIimit_OV
          SCALPRM_STCWie_M_SeriesModeMinWhlDmn_OV: accessed-parameter=STCWie_M_SeriesModeMinWhlDmn_OV
          SCALPRM_STCWie_b_DisableExtTrqAndFCAbritation: accessed-parameter=STCWie_b_DisableExtTrqAndFCAbritation
          SCALPRM_STCWie_b_DisableP1ImmedCaps: accessed-parameter=STCWie_b_DisableP1ImmedCaps
          SCALPRM_STCWie_b_DrvrTqDmEMTotCpbyMax_OB: accessed-parameter=STCWie_b_DrvrTqDmEMTotCpbyMax_OB
          SCALPRM_STCWie_b_DrvrTqDmEMTotCpbyMin_OB: accessed-parameter=STCWie_b_DrvrTqDmEMTotCpbyMin_OB
          SCALPRM_STCWie_b_EngMaxPM_DrvrDmn_OB: accessed-parameter=STCWie_b_EngMaxPM_DrvrDmn_OB
          SCALPRM_STCWie_b_FuelCutAllowedPropulsion_OB: accessed-parameter=STCWie_b_FuelCutAllowedPropulsion_OB
          SCALPRM_STCWie_b_FuelCutAllowedPropulsion_OV: accessed-parameter=STCWie_b_FuelCutAllowedPropulsion_OV
          SCALPRM_STCWie_b_MaxFrontTorqueWithoutBattLIimit_OB: accessed-parameter=STCWie_b_MaxFrontTorqueWithoutBattLIimit_OB
          SCALPRM_STCWie_b_MaxRearDrvDmn_OB: accessed-parameter=STCWie_b_MaxRearDrvDmn_OB
          SCALPRM_STCWie_b_MaxRearTorqueWithoutBattLIimit_OB: accessed-parameter=STCWie_b_MaxRearTorqueWithoutBattLIimit_OB
          SCALPRM_STCWie_b_MinFrontTorqueWithoutBattLIimit_OB: accessed-parameter=STCWie_b_MinFrontTorqueWithoutBattLIimit_OB
          SCALPRM_STCWie_b_MinRearDrvDmn_OB: accessed-parameter=STCWie_b_MinRearDrvDmn_OB
          SCALPRM_STCWie_b_MinRearTorqueWithoutBattLIimit_OB: accessed-parameter=STCWie_b_MinRearTorqueWithoutBattLIimit_OB
          SCALPRM_STCWie_b_P1SysTransControlled_OB: accessed-parameter=STCWie_b_P1SysTransControlled_OB
          SCALPRM_STCWie_b_P1SysTransControlled_OV: accessed-parameter=STCWie_b_P1SysTransControlled_OV
          SCALPRM_STCWie_b_PrplsAllowed_OB: accessed-parameter=STCWie_b_PrplsAllowed_OB
          SCALPRM_STCWie_b_ReplaceEngERSCapsWthCurrSpd: accessed-parameter=STCWie_b_ReplaceEngERSCapsWthCurrSpd
          SCALPRM_STCWie_b_SeriesModeMinWhlDmn_OB: accessed-parameter=STCWie_b_SeriesModeMinWhlDmn_OB
          SCALPRM_STCWie_e_PrplsAllowed_OV: accessed-parameter=STCWie_e_PrplsAllowed_OV
          SCALPRM_STCWke_Cnt_HoldWheelCapsAllowed: accessed-parameter=STCWke_Cnt_HoldWheelCapsAllowed
          SCALPRM_STCWke_Cnt_HoldWheelCapsHighDrive: accessed-parameter=STCWke_Cnt_HoldWheelCapsHighDrive
          SCALPRM_STCWke_Cnt_HoldWheelCapsHighDriveP4: accessed-parameter=STCWke_Cnt_HoldWheelCapsHighDriveP4
          SCALPRM_STCWke_Cnt_HoldWheelCapsHighReverse: accessed-parameter=STCWke_Cnt_HoldWheelCapsHighReverse
          SCALPRM_STCWke_Cnt_HoldWheelCapsHighReverseP4: accessed-parameter=STCWke_Cnt_HoldWheelCapsHighReverseP4
          SCALPRM_STCWke_M_CpbyGradientLimit: accessed-parameter=STCWke_M_CpbyGradientLimit
          SCALPRM_STCWke_M_DrvrTqDmEngCpbyMaxOvr: accessed-parameter=STCWke_M_DrvrTqDmEngCpbyMaxOvr
          SCALPRM_STCWke_M_DrvrTqDmEngCpbyMinOffOv: accessed-parameter=STCWke_M_DrvrTqDmEngCpbyMinOffOv
          SCALPRM_STCWke_M_DrvrTqDmTotCpbyMax: accessed-parameter=STCWke_M_DrvrTqDmTotCpbyMax
          SCALPRM_STCWke_M_DrvrTqDmTotCpbyMinOvr: accessed-parameter=STCWke_M_DrvrTqDmTotCpbyMinOvr
          SCALPRM_STCWke_M_FrontAxleMaxOvr: accessed-parameter=STCWke_M_FrontAxleMaxOvr
          SCALPRM_STCWke_M_FrontAxleMinOvr: accessed-parameter=STCWke_M_FrontAxleMinOvr
          SCALPRM_STCWke_M_ImmedMinOffSwitchFrom: accessed-parameter=STCWke_M_ImmedMinOffSwitchFrom
          SCALPRM_STCWke_M_ImmedMinOffSwitchTo: accessed-parameter=STCWke_M_ImmedMinOffSwitchTo
          SCALPRM_STCWke_M_MaxFrontDrvDmnOvr: accessed-parameter=STCWke_M_MaxFrontDrvDmnOvr
          SCALPRM_STCWke_M_MaxLimitFilterCloseToZeroLimit: accessed-parameter=STCWke_M_MaxLimitFilterCloseToZeroLimit
          SCALPRM_STCWke_M_MinFrontDrvDmnOvr: accessed-parameter=STCWke_M_MinFrontDrvDmnOvr
          SCALPRM_STCWke_M_MinLimitFilterCloseToZeroLimit: accessed-parameter=STCWke_M_MinLimitFilterCloseToZeroLimit
          SCALPRM_STCWke_M_P1ImmedCapMin_OV: accessed-parameter=STCWke_M_P1ImmedCapMin_OV
          SCALPRM_STCWke_M_P1ImmedMax_OV: accessed-parameter=STCWke_M_P1ImmedMax_OV
          SCALPRM_STCWke_M_P1MaxERSOvr: accessed-parameter=STCWke_M_P1MaxERSOvr
          SCALPRM_STCWke_M_P1MaxOvr: accessed-parameter=STCWke_M_P1MaxOvr
          SCALPRM_STCWke_M_P1MinERSOvr: accessed-parameter=STCWke_M_P1MinERSOvr
          SCALPRM_STCWke_M_P1MinOvr: accessed-parameter=STCWke_M_P1MinOvr
          SCALPRM_STCWke_M_P1MtrToWheelMax: accessed-parameter=STCWke_M_P1MtrToWheelMax
          SCALPRM_STCWke_M_P1MtrToWheelMin: accessed-parameter=STCWke_M_P1MtrToWheelMin
          SCALPRM_STCWke_M_RearAxleMaxESCOvr: accessed-parameter=STCWke_M_RearAxleMaxESCOvr
          SCALPRM_STCWke_M_RearAxleMinESCOvr: accessed-parameter=STCWke_M_RearAxleMinESCOvr
          SCALPRM_STCWke_M_SeriesModeMaxWhlDmnOvr: accessed-parameter=STCWke_M_SeriesModeMaxWhlDmnOvr
          SCALPRM_STCWke_M_WhlTqDmP3CpbySTMaxOvr: accessed-parameter=STCWke_M_WhlTqDmP3CpbySTMaxOvr
          SCALPRM_STCWke_M_WhlTqDmP3CpbySTMinOvr: accessed-parameter=STCWke_M_WhlTqDmP3CpbySTMinOvr
          SCALPRM_STCWke_M_WhlTqDmTotCpbyMaxOvr: accessed-parameter=STCWke_M_WhlTqDmTotCpbyMaxOvr
          SCALPRM_STCWke_M_WhlTqDmTotCpbyMinOvr: accessed-parameter=STCWke_M_WhlTqDmTotCpbyMinOvr
          SCALPRM_STCWke_b_AlwaysEnableFuelcut: accessed-parameter=STCWke_b_AlwaysEnableFuelcut
          SCALPRM_STCWke_b_CluScaleActive: accessed-parameter=STCWke_b_CluScaleActive
          SCALPRM_STCWke_b_CluScaleUseCmd: accessed-parameter=STCWke_b_CluScaleUseCmd
          SCALPRM_STCWke_b_DisableP1ToWheelNoGear: accessed-parameter=STCWke_b_DisableP1ToWheelNoGear
          SCALPRM_STCWke_b_DrvrTqDmEngCpbyMaxOvr: accessed-parameter=STCWke_b_DrvrTqDmEngCpbyMaxOvr
          SCALPRM_STCWke_b_DrvrTqDmEngCpbyMinOffOv: accessed-parameter=STCWke_b_DrvrTqDmEngCpbyMinOffOv
          SCALPRM_STCWke_b_DrvrTqDmTotCpbyMax: accessed-parameter=STCWke_b_DrvrTqDmTotCpbyMax
          SCALPRM_STCWke_b_DrvrTqDmTotCpbyMinOvr: accessed-parameter=STCWke_b_DrvrTqDmTotCpbyMinOvr
          SCALPRM_STCWke_b_EnableFilterCloseToZero: accessed-parameter=STCWke_b_EnableFilterCloseToZero
          SCALPRM_STCWke_b_EnableSmoothCapabilityReduction: accessed-parameter=STCWke_b_EnableSmoothCapabilityReduction
          SCALPRM_STCWke_b_EnableSmoothCapabilityReducti_41fba93e440e96f0: accessed-parameter=STCWke_b_EnableSmoothCapabilityReductionForDirectionChange
          SCALPRM_STCWke_b_EnblP1NegTrqAtWheelSwitchOff: accessed-parameter=STCWke_b_EnblP1NegTrqAtWheelSwitchOff
          SCALPRM_STCWke_b_EnblTransLossComp: accessed-parameter=STCWke_b_EnblTransLossComp
          SCALPRM_STCWke_b_FC_Gear{1..6}Enable: accessed-parameter=STCWke_b_FC_Gear{1..6}Enable
          SCALPRM_STCWke_b_FC_GearRvrsEnable: accessed-parameter=STCWke_b_FC_GearRvrsEnable
          SCALPRM_STCWke_b_FC_GearUndefinedEnable: accessed-parameter=STCWke_b_FC_GearUndefinedEnable
          SCALPRM_STCWke_b_FrontAxleMaxOvr: accessed-parameter=STCWke_b_FrontAxleMaxOvr
          SCALPRM_STCWke_b_FrontAxleMinOvr: accessed-parameter=STCWke_b_FrontAxleMinOvr
          SCALPRM_STCWke_b_FuelCutUseGSF_ForDrvbltRsp: accessed-parameter=STCWke_b_FuelCutUseGSF_ForDrvbltRsp
          SCALPRM_STCWke_b_HoldTrqDirectioEnable: accessed-parameter=STCWke_b_HoldTrqDirectioEnable
          SCALPRM_STCWke_b_IdleLimOnlyOnIsg: accessed-parameter=STCWke_b_IdleLimOnlyOnIsg
          SCALPRM_STCWke_b_IncludeEMMtrImmedCap: accessed-parameter=STCWke_b_IncludeEMMtrImmedCap
          SCALPRM_STCWke_b_LimitBoostInTotCapability: accessed-parameter=STCWke_b_LimitBoostInTotCapability
          SCALPRM_STCWke_b_LimitP1CapWithP1Cap: accessed-parameter=STCWke_b_LimitP1CapWithP1Cap
          SCALPRM_STCWke_b_LimitP1CapabilityWithIdleLimit: accessed-parameter=STCWke_b_LimitP1CapabilityWithIdleLimit
          SCALPRM_STCWke_b_LimitWheelCapabilityWithIdleLim: accessed-parameter=STCWke_b_LimitWheelCapabilityWithIdleLim
          SCALPRM_STCWke_b_M18Project: accessed-parameter=STCWke_b_M18Project
          SCALPRM_STCWke_b_MaxFrontDrvDmnOvr: accessed-parameter=STCWke_b_MaxFrontDrvDmnOvr
          SCALPRM_STCWke_b_MinFrontDrvDmnOvr: accessed-parameter=STCWke_b_MinFrontDrvDmnOvr
          SCALPRM_STCWke_b_NoP1ToWhlTrqInRvrsEnbl: accessed-parameter=STCWke_b_NoP1ToWhlTrqInRvrsEnbl
          SCALPRM_STCWke_b_NotLimitDrvrTqDmTotMinToEngMin: accessed-parameter=STCWke_b_NotLimitDrvrTqDmTotMinToEngMin
          SCALPRM_STCWke_b_P1ImmedCapMin_OB: accessed-parameter=STCWke_b_P1ImmedCapMin_OB
          SCALPRM_STCWke_b_P1ImmedMax_OB: accessed-parameter=STCWke_b_P1ImmedMax_OB
          SCALPRM_STCWke_b_P1MaxERSOvr: accessed-parameter=STCWke_b_P1MaxERSOvr
          SCALPRM_STCWke_b_P1MaxOvr: accessed-parameter=STCWke_b_P1MaxOvr
          SCALPRM_STCWke_b_P1MinERSOvr: accessed-parameter=STCWke_b_P1MinERSOvr
          SCALPRM_STCWke_b_P1MinOvr: accessed-parameter=STCWke_b_P1MinOvr
          SCALPRM_STCWke_b_ParkLockInhibitTimeEnable: accessed-parameter=STCWke_b_ParkLockInhibitTimeEnable
          SCALPRM_STCWke_b_PrplsAllowedDisableDirectionDep: accessed-parameter=STCWke_b_PrplsAllowedDisableDirectionDep
          SCALPRM_STCWke_b_PrplsAllowedDisableFuncActDep: accessed-parameter=STCWke_b_PrplsAllowedDisableFuncActDep
          SCALPRM_STCWke_b_PrplsAllowedDisableParkLockInhibit: accessed-parameter=STCWke_b_PrplsAllowedDisableParkLockInhibit
          SCALPRM_STCWke_b_PrplsAllowedDisablePowerModeDep: accessed-parameter=STCWke_b_PrplsAllowedDisablePowerModeDep
          SCALPRM_STCWke_b_RearAxleMaxESCOvr: accessed-parameter=STCWke_b_RearAxleMaxESCOvr
          SCALPRM_STCWke_b_RearAxleMinESCOvr: accessed-parameter=STCWke_b_RearAxleMinESCOvr
          SCALPRM_STCWke_b_SeriesModeMaxWhlDmnOvr: accessed-parameter=STCWke_b_SeriesModeMaxWhlDmnOvr
          SCALPRM_STCWke_b_SignChgLockOnP1Min: accessed-parameter=STCWke_b_SignChgLockOnP1Min
          SCALPRM_STCWke_b_UseDITDForTransWHLCaps: accessed-parameter=STCWke_b_UseDITDForTransWHLCaps
          SCALPRM_STCWke_b_UseEMTotCapForBrkRegenCapCalc: accessed-parameter=STCWke_b_UseEMTotCapForBrkRegenCapCalc
          SCALPRM_STCWke_b_UseMinRunLTForWhl: accessed-parameter=STCWke_b_UseMinRunLTForWhl
          SCALPRM_STCWke_b_UseP1MotorERSCaps: accessed-parameter=STCWke_b_UseP1MotorERSCaps
          SCALPRM_STCWke_b_UseP3MotorForBrakeRegenCap: accessed-parameter=STCWke_b_UseP3MotorForBrakeRegenCap
          SCALPRM_STCWke_b_UseP4MotorForBrakeRegenCap: accessed-parameter=STCWke_b_UseP4MotorForBrakeRegenCap
          SCALPRM_STCWke_b_UsePredictedToDetectTransCntrl: accessed-parameter=STCWke_b_UsePredictedToDetectTransCntrl
          SCALPRM_STCWke_b_UsePrplsAllwd: accessed-parameter=STCWke_b_UsePrplsAllwd
          SCALPRM_STCWke_b_UseTotCapForBrkRegenCapCalc: accessed-parameter=STCWke_b_UseTotCapForBrkRegenCapCalc
          SCALPRM_STCWke_b_WhlTqDmP3CpbySTMaxOvr: accessed-parameter=STCWke_b_WhlTqDmP3CpbySTMaxOvr
          SCALPRM_STCWke_b_WhlTqDmP3CpbySTMinOvr: accessed-parameter=STCWke_b_WhlTqDmP3CpbySTMinOvr
          SCALPRM_STCWke_b_WhlTqDmTotCpbyMaxOvr: accessed-parameter=STCWke_b_WhlTqDmTotCpbyMaxOvr
          SCALPRM_STCWke_b_WhlTqDmTotCpbyMinOvr: accessed-parameter=STCWke_b_WhlTqDmTotCpbyMinOvr
          SCALPRM_STCWke_cnt_DelayBitFlipNonCloseDrvLn: accessed-parameter=STCWke_cnt_DelayBitFlipNonCloseDrvLn
          SCALPRM_STCWke_cnt_DelayNonCloseDriveline: accessed-parameter=STCWke_cnt_DelayNonCloseDriveline
          SCALPRM_STCWke_dM_P1NegTrqOnRate: accessed-parameter=STCWke_dM_P1NegTrqOnRate
          SCALPRM_STCWke_dM_P1NegTrqShutOffRate: accessed-parameter=STCWke_dM_P1NegTrqShutOffRate
          SCALPRM_STCWke_dr_GearAvailDsblRate: accessed-parameter=STCWke_dr_GearAvailDsblRate
          SCALPRM_STCWke_dr_GearAvailEnbleRate: accessed-parameter=STCWke_dr_GearAvailEnbleRate
          SCALPRM_STCWke_dr_SwitchRateDisableExtended: accessed-parameter=STCWke_dr_SwitchRateDisableExtended
          SCALPRM_STCWke_dr_SwitchRateDisableFC: accessed-parameter=STCWke_dr_SwitchRateDisableFC
          SCALPRM_STCWke_dr_SwitchRateEnableExtended: accessed-parameter=STCWke_dr_SwitchRateEnableExtended
          SCALPRM_STCWke_dr_SwitchRateEnableFC: accessed-parameter=STCWke_dr_SwitchRateEnableFC
          SCALPRM_STCWke_e_CluToEmFactMethod: accessed-parameter=STCWke_e_CluToEmFactMethod
          SCALPRM_STCWke_n_FC_Gear1Disable: accessed-parameter=STCWke_n_FC_Gear1Disable
          SCALPRM_STCWke_n_FC_Gear1Enable: accessed-parameter=STCWke_n_FC_Gear1Enable
          SCALPRM_STCWke_n_FC_Gear2Disable: accessed-parameter=STCWke_n_FC_Gear2Disable
          SCALPRM_STCWke_n_FC_Gear2Enable: accessed-parameter=STCWke_n_FC_Gear2Enable
          SCALPRM_STCWke_n_FC_Gear3Disable: accessed-parameter=STCWke_n_FC_Gear3Disable
          SCALPRM_STCWke_n_FC_Gear3Enable: accessed-parameter=STCWke_n_FC_Gear3Enable
          SCALPRM_STCWke_n_FC_Gear4Disable: accessed-parameter=STCWke_n_FC_Gear4Disable
          SCALPRM_STCWke_n_FC_Gear4Enable: accessed-parameter=STCWke_n_FC_Gear4Enable
          SCALPRM_STCWke_n_FC_Gear5Disable: accessed-parameter=STCWke_n_FC_Gear5Disable
          SCALPRM_STCWke_n_FC_Gear5Enable: accessed-parameter=STCWke_n_FC_Gear5Enable
          SCALPRM_STCWke_n_FC_Gear6Disable: accessed-parameter=STCWke_n_FC_Gear6Disable
          SCALPRM_STCWke_n_FC_Gear6Enable: accessed-parameter=STCWke_n_FC_Gear6Enable
          SCALPRM_STCWke_n_FC_GearRvrsDisable: accessed-parameter=STCWke_n_FC_GearRvrsDisable
          SCALPRM_STCWke_n_FC_GearRvrsEnable: accessed-parameter=STCWke_n_FC_GearRvrsEnable
          SCALPRM_STCWke_r_MarginForFilteringCloseToZero: accessed-parameter=STCWke_r_MarginForFilteringCloseToZero
          SCALPRM_STCWke_scl_CluToEMfactor: accessed-parameter=STCWke_scl_CluToEMfactor
          SCALPRM_STCWke_t_ParkLockInhibitDuration: accessed-parameter=STCWke_t_ParkLockInhibitDuration
          SCALPRM_STCWke_t_SampleTime: accessed-parameter=STCWke_t_SampleTime
          SCALPRM_STCWke_v_VehicleSpeedLimitForMaxCapabilityReduction: accessed-parameter=STCWke_v_VehicleSpeedLimitForMaxCapabilityReduction
          SCALPRM_STCWke_v_VehicleSpeedLimitForMinCapabilityReduction: accessed-parameter=STCWke_v_VehicleSpeedLimitForMinCapabilityReduction
          SCALPRM_STCWkn_M_MaxLimitFilterTorqueCloseToZero: accessed-parameter=STCWkn_M_MaxLimitFilterTorqueCloseToZero
          SCALPRM_STCWkn_M_MinLimitFilterTorqueCloseToZero: accessed-parameter=STCWkn_M_MinLimitFilterTorqueCloseToZero
          SCALPRM_STCWkn_Pct_ClchCmdCapFactorAx: accessed-parameter=STCWkn_Pct_ClchCmdCapFactorAx, sw-calprm-axis-set=sw-axis-individual=sw-variable=STCWve_Pct_ClchCmd
          SCALPRM_STCWkn_f_CapFactAtCluPedAxis: accessed-parameter=STCWkn_f_CapFactAtCluPedAxis, sw-calprm-axis-set=sw-axis-individual=sw-variable=STCWve_f_CluRelCDPDist
          SCALPRM_STCWkn_n_MtrAMinLimSclAxis: accessed-parameter=STCWkn_n_MtrAMinLimSclAxis
          SCALPRM_STCWkn_v_RearVehSpdX: accessed-parameter=STCWkn_v_RearVehSpdX
          SCALPRM_STCWkn_v_VehSpdX: accessed-parameter=STCWkn_v_VehSpdX
          SCALPRM_STCWkt_M_MaxLimitFilterTorqueCloseToZero: accessed-parameter=STCWkt_M_MaxLimitFilterTorqueCloseToZero, sw-calprm-axis-set={sw-axis-index=1, sw-axis-grouped=ar-parameter=STCWkn_M_MaxLimitFilterTorqueCloseToZero}
          SCALPRM_STCWkt_M_MinLimitFilterTorqueCloseToZero: accessed-parameter=STCWkt_M_MinLimitFilterTorqueCloseToZero, sw-calprm-axis-set={sw-axis-index=1, sw-axis-grouped=ar-parameter=STCWkn_M_MinLimitFilterTorqueCloseToZero}
          SCALPRM_STCWkt_f_CapFactAtCluPed: accessed-parameter=STCWkt_f_CapFactAtCluPed, sw-calprm-axis-set={sw-axis-index=1, sw-axis-grouped=ar-parameter=STCWkn_f_CapFactAtCluPedAxis}
          SCALPRM_STCWkt_f_ClchCmdCapFactor: accessed-parameter=STCWkt_f_ClchCmdCapFactor, sw-calprm-axis-set={sw-axis-index=1, sw-axis-grouped=ar-parameter=STCWkn_Pct_ClchCmdCapFactorAx}
          SCALPRM_STCWkt_r_MtrAMinLimScl: accessed-parameter=STCWkt_r_MtrAMinLimScl, sw-calprm-axis-set={sw-axis-index=1, sw-axis-grouped=ar-parameter=STCWkn_n_MtrAMinLimSclAxis}
          SCALPRM_STCWkt_r_PartOfTotalCpbyD: accessed-parameter=STCWkt_r_PartOfTotalCpbyD, sw-calprm-axis-set={sw-axis-index=1, sw-axis-grouped=ar-parameter=STCWkn_v_VehSpdX}
          SCALPRM_STCWkt_r_PartOfTotalCpbyR: accessed-parameter=STCWkt_r_PartOfTotalCpbyR, sw-calprm-axis-set={sw-axis-index=1, sw-axis-grouped=ar-parameter=STCWkn_v_VehSpdX}
          SCALPRM_STCWkt_r_RearPartOfTotalCpbyD: accessed-parameter=STCWkt_r_RearPartOfTotalCpbyD, sw-calprm-axis-set={sw-axis-index=1, sw-axis-grouped=ar-parameter=STCWkn_v_RearVehSpdX}
          SCALPRM_STCWkt_r_RearPartOfTotalCpbyR: accessed-parameter=STCWkt_r_RearPartOfTotalCpbyR, sw-calprm-axis-set={sw-axis-index=1, sw-axis-grouped=ar-parameter=STCWkn_v_RearVehSpdX}
        written-local-variables:
          access WV_STCWve_b_VehDirOppositeDrvrReq: accessed-variable=STCWve_b_VehDirOppositeDrvrReq
          access WV_STCWve_M_BrkRgnBaseCpbyIRV: accessed-variable=STCWve_M_BrkRgnBaseCpbyIRV
      runnable Runnable_STCW_BrkRgnCalc_10ms
        data-receive-point-by-arguments:
          7 x access:
            IN_ACCPve_M_ZeroPedalDrvDmn_ACCPve_M_ZeroPedalDrvDmn: accessed-variable=ACCPve_M_ZeroPedalDrvDmn.ACCPve_M_ZeroPedalDrvDmn
            IN_ADCIve_M_AdptvCruiseTorqueReq_ADCIve_M_AdptvCruiseTorqueReq: accessed-variable=ADCIve_M_AdptvCruiseTorqueReq.ADCIve_M_AdptvCruiseTorqueReq
            IN_DITDve_e_DrvrIntTorqDirctn_DITDve_e_DrvrIntTorqDirctn: accessed-variable=DITDve_e_DrvrIntTorqDirctn.DITDve_e_DrvrIntTorqDirctn
            IN_DTOSve_M_CmdPrplsFiltWhlDmnImmediate_DTOSve_aea4d2e9ff300e98: accessed-variable=DTOSve_M_CmdPrplsFiltWhlDmnImmediate.DTOSve_M_CmdPrplsFiltWhlDmnImmediate
            IN_FDMAve_b_ForceBrakeRegenerationTorqueOff_FD_fe59027de899cc5e: accessed-variable=FDMAve_b_ForceBrakeRegenerationTorqueOff.FDMAve_b_ForceBrakeRegenerationTorqueOff
            IN_TGSPve_b_GearShiftUpFlag_TGSPve_b_GearShiftUpFlag: accessed-variable=TGSPve_b_GearShiftUpFlag.TGSPve_b_GearShiftUpFlag
            IN_VSPEve_v_DrvnWhlsSpd_VSPEve_v_DrvnWhlsSpd: accessed-variable=VSPEve_v_DrvnWhlsSpd.VSPEve_v_DrvnWhlsSpd
        data-send-points:
          access OUT_STCWve_M_BrkRgnCpby_STCWve_M_BrkRgnCpby: accessed-variable=STCWve_M_BrkRgnCpby.STCWve_M_BrkRgnCpby
          access OUT_STCWve_M_BrkRgnCpbyReverse_STCWve_M_BrkRgnCpbyReverse: accessed-variable=STCWve_M_BrkRgnCpbyReverse.STCWve_M_BrkRgnCpbyReverse
        18 x parameter access:
          SCALPRM_STCWke_M_BrakeRegenLowPedalDsbl: accessed-parameter=STCWke_M_BrakeRegenLowPedalDsbl
          SCALPRM_STCWke_M_BrakeRegenLowPedalEnbl: accessed-parameter=STCWke_M_BrakeRegenLowPedalEnbl
          SCALPRM_STCWke_M_BrakeRegenTrqThreshold: accessed-parameter=STCWke_M_BrakeRegenTrqThreshold
          SCALPRM_STCWke_M_BrkRgnCpbyOvr: accessed-parameter=STCWke_M_BrkRgnCpbyOvr
          SCALPRM_STCWke_M_CpbyGradientLimit: accessed-parameter=STCWke_M_CpbyGradientLimit
          SCALPRM_STCWke_b_BrakeRegenLowPedalEnable: accessed-parameter=STCWke_b_BrakeRegenLowPedalEnable
          SCALPRM_STCWke_b_BrakeRegenUseZeroPedal: accessed-parameter=STCWke_b_BrakeRegenUseZeroPedal
          SCALPRM_STCWke_b_BrkRgnCpbyOvr: accessed-parameter=STCWke_b_BrkRgnCpbyOvr
          SCALPRM_STCWke_b_InhibitBRWhenUpshift: accessed-parameter=STCWke_b_InhibitBRWhenUpshift
          SCALPRM_STCWke_b_OnlyAllowBrakeRegenInForward: accessed-parameter=STCWke_b_OnlyAllowBrakeRegenInForward
          SCALPRM_STCWke_b_RdcBrkRgnWithActCstTq: accessed-parameter=STCWke_b_RdcBrkRgnWithActCstTq
          SCALPRM_STCWke_b_SubADSNegTrqInBrkRgn: accessed-parameter=STCWke_b_SubADSNegTrqInBrkRgn
          SCALPRM_STCWke_dM_BrakeRegenLowPedalDsbl: accessed-parameter=STCWke_dM_BrakeRegenLowPedalDsbl
          SCALPRM_STCWke_dM_BrakeRegenLowPedalEnbl: accessed-parameter=STCWke_dM_BrakeRegenLowPedalEnbl
          SCALPRM_STCWke_t_SafetyTorqueRampTimeDown: accessed-parameter=STCWke_t_SafetyTorqueRampTimeDown
          SCALPRM_STCWke_t_SampleTime: accessed-parameter=STCWke_t_SampleTime
          SCALPRM_STCWkn_v_BrkRgnSpeedAxis: accessed-parameter=STCWkn_v_BrkRgnSpeedAxis
          SCALPRM_STCWkt_K_BrkRgnRampOut: accessed-parameter=STCWkt_K_BrkRgnRampOut, sw-calprm-axis-set={sw-axis-index=1, sw-axis-grouped=ar-parameter=STCWkn_v_BrkRgnSpeedAxis}
        read-local-variables:
          access RV_STCWve_M_BrkRgnBaseCpbyIRV: accessed-variable=STCWve_M_BrkRgnBaseCpbyIRV
          access RV_STCWve_b_VehDirOppositeDrvrReq: accessed-variable=STCWve_b_VehDirOppositeDrvrReq
      runnable Runnable_STCW_Init
        data-send-points:
          27 x access:
            OUT_STCWve_e_TrqDirFoWhlCaps_STCWve_e_TrqDirFoWhlCaps: accessed-variable=STCWve_e_TrqDirFoWhlCaps.STCWve_e_TrqDirFoWhlCaps
            OUT_STCWve_M_WhlTqDmP3CpbySTMax_STCWve_M_WhlTqDmP3CpbySTMax: accessed-variable=STCWve_M_WhlTqDmP3CpbySTMax.STCWve_M_WhlTqDmP3CpbySTMax
            OUT_STCWve_M_WhlTqDmP3CpbySTMin_STCWve_M_WhlTqDmP3CpbySTMin: accessed-variable=STCWve_M_WhlTqDmP3CpbySTMin.STCWve_M_WhlTqDmP3CpbySTMin
            OUT_STCWve_M_DrvrTqDmEngCpbyMax_STCWve_M_DrvrTqDmEngCpbyMax: accessed-variable=STCWve_M_DrvrTqDmEngCpbyMax.STCWve_M_DrvrTqDmEngCpbyMax
            OUT_STCWve_M_DrvrTqDmEngCpbyMinOff_STCWve_M_Dr_56a1bd35efca119f: accessed-variable=STCWve_M_DrvrTqDmEngCpbyMinOff.STCWve_M_DrvrTqDmEngCpbyMinOff
            OUT_STCWve_M_WhlTqDmTotCpbyMax_STCWve_M_WhlTqDmTotCpbyMax: accessed-variable=STCWve_M_WhlTqDmTotCpbyMax.STCWve_M_WhlTqDmTotCpbyMax
            OUT_STCWve_M_WhlTqDmTotCpbyMin_STCWve_M_WhlTqDmTotCpbyMin: accessed-variable=STCWve_M_WhlTqDmTotCpbyMin.STCWve_M_WhlTqDmTotCpbyMin
            OUT_STCWve_M_DrvrTqDmTotCpbyMax_STCWve_M_DrvrTqDmTotCpbyMax: accessed-variable=STCWve_M_DrvrTqDmTotCpbyMax.STCWve_M_DrvrTqDmTotCpbyMax
            OUT_STCWve_M_DrvrTqDmTotCpbyMin_STCWve_M_DrvrTqDmTotCpbyMin: accessed-variable=STCWve_M_DrvrTqDmTotCpbyMin.STCWve_M_DrvrTqDmTotCpbyMin
            OUT_STCWve_e_PrplsAllowed_STCWve_e_PrplsAllowed: accessed-variable=STCWve_e_PrplsAllowed.STCWve_e_PrplsAllowed
            OUT_STCWve_M_EngMaxPM_DrvrDmn_STCWve_M_EngMaxPM_DrvrDmn: accessed-variable=STCWve_M_EngMaxPM_DrvrDmn.STCWve_M_EngMaxPM_DrvrDmn
            OUT_STCWve_M_FrontAxleMaxESC_STCWve_M_FrontAxleMaxESC: accessed-variable=STCWve_M_FrontAxleMaxESC.STCWve_M_FrontAxleMaxESC
            OUT_STCWve_M_FrontAxleMinESC_STCWve_M_FrontAxleMinESC: accessed-variable=STCWve_M_FrontAxleMinESC.STCWve_M_FrontAxleMinESC
            OUT_STCWve_M_RearAxleMaxESC_STCWve_M_RearAxleMaxESC: accessed-variable=STCWve_M_RearAxleMaxESC.STCWve_M_RearAxleMaxESC
            OUT_STCWve_M_RearAxleMinESC_STCWve_M_RearAxleMinESC: accessed-variable=STCWve_M_RearAxleMinESC.STCWve_M_RearAxleMinESC
            OUT_STCWve_M_SeriesModeMinWhlDmn_STCWve_M_SeriesModeMinWhlDmn: accessed-variable=STCWve_M_SeriesModeMinWhlDmn.STCWve_M_SeriesModeMinWhlDmn
            OUT_STCWve_M_SeriesModeMaxWhlDmn_STCWve_M_SeriesModeMaxWhlDmn: accessed-variable=STCWve_M_SeriesModeMaxWhlDmn.STCWve_M_SeriesModeMaxWhlDmn
            OUT_STCWve_M_MaxRearDrvDmn_STCWve_M_MaxRearDrvDmn: accessed-variable=STCWve_M_MaxRearDrvDmn.STCWve_M_MaxRearDrvDmn
            OUT_STCWve_M_MinFrontDrvDmn_STCWve_M_MinFrontDrvDmn: accessed-variable=STCWve_M_MinFrontDrvDmn.STCWve_M_MinFrontDrvDmn
            OUT_STCWve_M_MaxFrontDrvDmn_STCWve_M_MaxFrontDrvDmn: accessed-variable=STCWve_M_MaxFrontDrvDmn.STCWve_M_MaxFrontDrvDmn
            OUT_STCWve_M_MinRearDrvDmn_STCWve_M_MinRearDrvDmn: accessed-variable=STCWve_M_MinRearDrvDmn.STCWve_M_MinRearDrvDmn
            OUT_STCWve_M_DrvrTqDmEMTotCpbyMax_STCWve_M_DrvrTqDmEMTotCpbyMax: accessed-variable=STCWve_M_DrvrTqDmEMTotCpbyMax.STCWve_M_DrvrTqDmEMTotCpbyMax
            OUT_STCWve_M_DrvrTqDmEMTotCpbyMin_STCWve_M_DrvrTqDmEMTotCpbyMin: accessed-variable=STCWve_M_DrvrTqDmEMTotCpbyMin.STCWve_M_DrvrTqDmEMTotCpbyMin
            OUT_STCWve_M_MaxFrontAxleForUAES_STCWve_M_MaxFrontAxleForUAES: accessed-variable=STCWve_M_MaxFrontAxleForUAES.STCWve_M_MaxFrontAxleForUAES
            OUT_STCWve_M_MinFrontAxleForUAES_STCWve_M_MinFrontAxleForUAES: accessed-variable=STCWve_M_MinFrontAxleForUAES.STCWve_M_MinFrontAxleForUAES
            OUT_STCWve_M_MaxRearAxleForUAES_STCWve_M_MaxRearAxleForUAES: accessed-variable=STCWve_M_MaxRearAxleForUAES.STCWve_M_MaxRearAxleForUAES
            OUT_STCWve_M_MinRearAxleForUAES_STCWve_M_MinRearAxleForUAES: accessed-variable=STCWve_M_MinRearAxleForUAES.STCWve_M_MinRearAxleForUAES
        parameter access SCALPRM_STCWke_Cnt_HoldWheelCapsAllowed: accessed-parameter=STCWke_Cnt_HoldWheelCapsAllowed
        written-local-variables:
          access WV_STCWve_b_VehDirOppositeDrvrReq: accessed-variable=STCWve_b_VehDirOppositeDrvrReq
          access WV_STCWve_M_BrkRgnBaseCpbyIRV: accessed-variable=STCWve_M_BrkRgnBaseCpbyIRV
      shared-parameters:
        189 x parameter data prototype, all with sw-calibration-access=READ-WRITE:
          STCWie_M_DrvrTqDmEMTotCpbyMax_OV: category=VALUE, type=T_M_Nm_Float32_n10000to10000, init-value=constant-reference={short-label=STCWie_M_DrvrTqDmEMTotCpbyMax_OV, constant=STCWie_M_DrvrTqDmEMTotCpbyMax_OV}  # Override Value
          STCWie_M_DrvrTqDmEMTotCpbyMin_OV: category=VALUE, type=T_M_Nm_Float32_n10000to10000, init-value=constant-reference={short-label=STCWie_M_DrvrTqDmEMTotCpbyMin_OV, constant=STCWie_M_DrvrTqDmEMTotCpbyMin_OV}  # Override value
          STCWie_M_EngMaxPM_DrvrDmn_OV: category=VALUE, type=T_M_Nm_Float32_n10000to10000, init-value=constant-reference={short-label=STCWie_M_EngMaxPM_DrvrDmn_OV, constant=STCWie_M_EngMaxPM_DrvrDmn_OV}  # Override value
          STCWie_M_MaxFrontTorqueWithoutBattLIimit_OV: category=VALUE, type=T_M_Nm_Float32, init-value=constant-reference={short-label=STCWie_M_MaxFrontTorqueWithoutBattLIimit_OV, constant=STCWie_M_MaxFrontTorqueWithoutBattLIimit_OV}  # Override Value
          STCWie_M_MaxRearDrvDmn_OV: category=VALUE, type=T_M_Nm_Float32, init-value=constant-reference={short-label=STCWie_M_MaxRearDrvDmn_OV, constant=STCWie_M_MaxRearDrvDmn_OV}
          STCWie_M_MaxRearTorqueWithoutBattLIimit_OV: category=VALUE, type=T_M_Nm_Float32, init-value=constant-reference={short-label=STCWie_M_MaxRearTorqueWithoutBattLIimit_OV, constant=STCWie_M_MaxRearTorqueWithoutBattLIimit_OV}
          STCWie_M_MinFrontTorqueWithoutBattLIimit_OV: category=VALUE, type=T_M_Nm_Float32, init-value=constant-reference={short-label=STCWie_M_MinFrontTorqueWithoutBattLIimit_OV, constant=STCWie_M_MinFrontTorqueWithoutBattLIimit_OV}
          STCWie_M_MinRearDrvDmn_OV: category=VALUE, type=T_M_Nm_Float32, init-value=constant-reference={short-label=STCWie_M_MinRearDrvDmn_OV, constant=STCWie_M_MinRearDrvDmn_OV}
          STCWie_M_MinRearTorqueWithoutBattLIimit_OV: category=VALUE, type=T_M_Nm_Float32, init-value=constant-reference={short-label=STCWie_M_MinRearTorqueWithoutBattLIimit_OV, constant=STCWie_M_MinRearTorqueWithoutBattLIimit_OV}
          STCWie_M_SeriesModeMinWhlDmn_OV: category=VALUE, type=T_M_Nm_Float32_n10000to10000, init-value=constant-reference={short-label=STCWie_M_SeriesModeMinWhlDmn_OV, constant=STCWie_M_SeriesModeMinWhlDmn_OV}  # Override Value
          STCWke_M_BrakeRegenLowPedalDsbl: category=VALUE, type=T_M_Nm_Float32_0to6, init-value=constant-reference={short-label=STCWke_M_BrakeRegenLowPedalDsbl, constant=STCWke_M_BrakeRegenLowPedalDsbl}  # This calibration defines difference between Filtered driver request and zero pedal at which brake regen is Disabled if BrakeRegenLowPedal functionality is enabled
          STCWke_M_BrakeRegenLowPedalEnbl: category=VALUE, type=T_M_Nm_Float32_0to6, init-value=constant-reference={short-label=STCWke_M_BrakeRegenLowPedalEnbl, constant=STCWke_M_BrakeRegenLowPedalEnbl}  # This calibration defines difference between Filtered driver request and zero pedal at which brake regen is enabled if BrakeRegenLowPedal functionality is enabled
          STCWke_M_BrakeRegenTrqThreshold: category=VALUE, type=T_M_Nm_Float32_n4000to0, init-value=constant-reference={short-label=STCWke_M_BrakeRegenTrqThreshold, constant=STCWke_M_BrakeRegenTrqThreshold}  # Torque threshold filtered driver request is below this value brake regen will be enabled if Brake regen Low pedal func is enabled
          STCWke_M_BrkRgnCpbyOvr: category=VALUE, type=T_M_Nm_Float32_n5000to5000, init-value=constant-reference={short-label=STCWke_M_BrkRgnCpbyOvr, constant=STCWke_M_BrkRgnCpbyOvr}  # Brake Regen override value
          STCWke_M_CpbyGradientLimit: category=VALUE, type=T_M_Nm_Float32_0to8000, init-value=constant-reference={short-label=STCWke_M_CpbyGradientLimit, constant=STCWke_M_CpbyGradientLimit}  # ###Description Decides how fast capabilities are allowed to increase (Nm/sample). ###usage Used to avoid that capabilities suddenly become large and non-zero when previously reset by propulsion allowed or DITD etc. ### Used to prevent oscilations in the system shall not be used to calibrate drivability
          STCWke_M_DrvrTqDmEngCpbyMaxOvr: category=VALUE, type=T_M_Nm_Float32_n5000to5000, init-value=constant-reference={short-label=STCWke_M_DrvrTqDmEngCpbyMaxOvr, constant=STCWke_M_DrvrTqDmEngCpbyMaxOvr}  # Override value for Maximum available engine torque in the driver domain.
          STCWke_M_DrvrTqDmEngCpbyMinOffOv: category=VALUE, type=T_M_Nm_Float32_n5000to5000, init-value=constant-reference={short-label=STCWke_M_DrvrTqDmEngCpbyMinOffOv, constant=STCWke_M_DrvrTqDmEngCpbyMinOffOv}  # Override value for Minimum available engine torque in the driver domain.
          STCWke_M_DrvrTqDmTotCpbyMax: category=VALUE, type=T_M_Nm_Float32, init-value=constant-reference={short-label=STCWke_M_DrvrTqDmTotCpbyMax, constant=STCWke_M_DrvrTqDmTotCpbyMax}
          STCWke_M_DrvrTqDmTotCpbyMinOvr: category=VALUE, type=T_M_Nm_Float32, init-value=constant-reference={short-label=STCWke_M_DrvrTqDmTotCpbyMinOvr, constant=STCWke_M_DrvrTqDmTotCpbyMinOvr}
          STCWke_M_FrontAxleMaxOvr: category=VALUE, type=T_M_Nm_Float32_n5000to5000, init-value=constant-reference={short-label=STCWke_M_FrontAxleMaxOvr, constant=STCWke_M_FrontAxleMaxOvr}  # Override value
          STCWke_M_FrontAxleMinOvr: category=VALUE, type=T_M_Nm_Float32_n10000to10000, init-value=constant-reference={short-label=STCWke_M_FrontAxleMinOvr, constant=STCWke_M_FrontAxleMinOvr}  # Override value
          STCWke_M_MaxFrontDrvDmnOvr: category=VALUE, type=T_M_Nm_Float32_n10000to10000, init-value=constant-reference={short-label=STCWke_M_MaxFrontDrvDmnOvr, constant=STCWke_M_MaxFrontDrvDmnOvr}  # **
          STCWke_M_MaxLimitFilterCloseToZeroLimit: category=VALUE, type=T_M_Nm_Float32_0to3000, init-value=constant-reference={short-label=STCWke_M_MaxLimitFilterCloseToZeroLimit, constant=STCWke_M_MaxLimitFilterCloseToZeroLimit}  # Limit for having more filter of the max limit when torque is close to zero
          STCWke_M_MinFrontDrvDmnOvr: category=VALUE, type=T_M_Nm_Float32_n10000to10000, init-value=constant-reference={short-label=STCWke_M_MinFrontDrvDmnOvr, constant=STCWke_M_MinFrontDrvDmnOvr}  # Override value for Minimum available total torque in the driver domain.
          STCWke_M_MinLimitFilterCloseToZeroLimit: category=VALUE, type=T_M_Nm_Float32_n3000to0, init-value=constant-reference={short-label=STCWke_M_MinLimitFilterCloseToZeroLimit, constant=STCWke_M_MinLimitFilterCloseToZeroLimit}  # Limit for having more filter of the min limit when torque is close to zero
          STCWke_M_RearAxleMaxESCOvr: category=VALUE, type=T_M_Nm_Float32_n10000to10000, init-value=constant-reference={short-label=STCWke_M_RearAxleMaxESCOvr, constant=STCWke_M_RearAxleMaxESCOvr}  # Override value
          STCWke_M_RearAxleMinESCOvr: category=VALUE, type=T_M_Nm_Float32, init-value=constant-reference={short-label=STCWke_M_RearAxleMinESCOvr, constant=STCWke_M_RearAxleMinESCOvr}
          STCWke_M_SeriesModeMaxWhlDmnOvr: category=VALUE, type=T_M_Nm_Float32_n10000to10000, init-value=constant-reference={short-label=STCWke_M_SeriesModeMaxWhlDmnOvr, constant=STCWke_M_SeriesModeMaxWhlDmnOvr}  # Override value for Minimum available total torque in the driver domain.
          STCWke_M_WhlTqDmP3CpbySTMaxOvr: category=VALUE, type=T_M_Nm_Float32, init-value=constant-reference={short-label=STCWke_M_WhlTqDmP3CpbySTMaxOvr, constant=STCWke_M_WhlTqDmP3CpbySTMaxOvr}
          STCWke_M_WhlTqDmP3CpbySTMinOvr: category=VALUE, type=T_M_Nm_Float32, init-value=constant-reference={short-label=STCWke_M_WhlTqDmP3CpbySTMinOvr, constant=STCWke_M_WhlTqDmP3CpbySTMinOvr}
          STCWke_M_WhlTqDmTotCpbyMaxOvr: category=VALUE, type=T_M_Nm_Float32, init-value=constant-reference={short-label=STCWke_M_WhlTqDmTotCpbyMaxOvr, constant=STCWke_M_WhlTqDmTotCpbyMaxOvr}
          STCWke_M_WhlTqDmTotCpbyMinOvr: category=VALUE, type=T_M_Nm_Float32, init-value=constant-reference={short-label=STCWke_M_WhlTqDmTotCpbyMinOvr, constant=STCWke_M_WhlTqDmTotCpbyMinOvr}
          STCWke_dM_BrakeRegenLowPedalDsbl: category=VALUE, type=T_M_Nm_Float32_n2000to0, init-value=constant-reference={short-label=STCWke_dM_BrakeRegenLowPedalDsbl, constant=STCWke_dM_BrakeRegenLowPedalDsbl}  # Defines how fast brake regen torque capability is allowed to decrease when Low Pedal Disabled is set to True NOTE this calibration also rate limiting the brake regen capability at all times not only when brake regen is enabled
          STCWke_dM_BrakeRegenLowPedalEnbl: category=VALUE, type=T_M_Nm_Float32_0to1000, init-value=constant-reference={short-label=STCWke_dM_BrakeRegenLowPedalEnbl, constant=STCWke_dM_BrakeRegenLowPedalEnbl}  # Defines how fast brake regen torque capability is allowed to increase when Low Pedal Disabled is set to zero. NOTE this calibration also rate limiting the brake regen capability at all times not only when brake regen is enabled
          STCWke_Cnt_HoldWheelCapsAllowed: category=VALUE, type=T_Cnt_Num_1_1_u16_0to20, init-value=constant-reference={short-label=STCWke_Cnt_HoldWheelCapsAllowed, constant=STCWke_Cnt_HoldWheelCapsAllowed}  # Samples of delay until wheel torque capabilities is shutdown after the \real\ propulsion allowed is shutdown. It also defines the time of how long a previous torque direction is hold after direction goes to undefined
          STCWke_Cnt_HoldWheelCapsHighDrive: category=VALUE, type=T_Cnt_Num_1_1_u16_0to10000, init-value=constant-reference={short-label=STCWke_Cnt_HoldWheelCapsHighDrive, constant=STCWke_Cnt_HoldWheelCapsHighDrive}  # Time delay for keeping the capabiliies high just after a change to drive.
          STCWke_Cnt_HoldWheelCapsHighDriveP4: category=VALUE, type=T_Cnt_Num_1_1_u16_0to10000, init-value=constant-reference={short-label=STCWke_Cnt_HoldWheelCapsHighDriveP4, constant=STCWke_Cnt_HoldWheelCapsHighDriveP4}  # Time delay for keeping the capabiliies high just after a change to drive.
          STCWke_Cnt_HoldWheelCapsHighReverse: category=VALUE, type=T_Cnt_Num_1_1_u16_0to10000, init-value=constant-reference={short-label=STCWke_Cnt_HoldWheelCapsHighReverse, constant=STCWke_Cnt_HoldWheelCapsHighReverse}  # Time delay for keeping the capabiliies high just after a change to reverse.
          STCWke_Cnt_HoldWheelCapsHighReverseP4: category=VALUE, type=T_Cnt_Num_1_1_u16_0to10000, init-value=constant-reference={short-label=STCWke_Cnt_HoldWheelCapsHighReverseP4, constant=STCWke_Cnt_HoldWheelCapsHighReverseP4}  # Time delay for keeping the capabiliies high just after a change to reverse.
          STCWke_cnt_DelayBitFlipNonCloseDrvLn: category=VALUE, type=T_Cnt_Num_1_1_u16_0to10000, init-value=constant-reference={short-label=STCWke_cnt_DelayBitFlipNonCloseDrvLn, constant=STCWke_cnt_DelayBitFlipNonCloseDrvLn}  # Used inte the functionality to remove the Allowed minimum P1 torque to put on wheels when the drivline is open. This calibrations delays the of when driveline is open and is mainly used to secure for bitflips between e.g. shift active and driveline open
          STCWke_cnt_DelayNonCloseDriveline: category=VALUE, type=T_Cnt_Num_1_1_u16_0to10000, init-value=constant-reference={short-label=STCWke_cnt_DelayNonCloseDriveline, constant=STCWke_cnt_DelayNonCloseDriveline}  # Used inte the functionality to remove the Allowed minimum P1 torque to put on wheels when the drivline is open. This calibrations delays the detection of when the driveline has been opened and therby also delays the time where the allowed negative P1 torque on wheels i removed
          STCWkt_K_BrkRgnRampOut: category=CURVE, type=Appl_STCWkt_K_BrkRgnRampOut, init-value=constant-reference={short-label=STCWkt_K_BrkRgnRampOut, constant=STCWkt_K_BrkRgnRampOut}  # ###Description Table with factor for ramping out brake regen capability in low speed. ###Usage Use to define how the available brake regen torque capability shall be ramped out when approching standstill ###Calibration Note Don't make to steep and/or to ramp out to close to zero, this will easily introduce oscillations in the driveline
          STCWke_M_ImmedMinOffSwitchFrom: category=VALUE, type=T_M_Nm_32_1_s16_n50to50, init-value=constant-reference={short-label=STCWke_M_ImmedMinOffSwitchFrom, constant=STCWke_M_ImmedMinOffSwitchFrom}  # Switch point where MinImmed is MinRunCurr and not MinOff
          STCWke_M_ImmedMinOffSwitchTo: category=VALUE, type=T_M_Nm_32_1_s16_n50to50, init-value=constant-reference={short-label=STCWke_M_ImmedMinOffSwitchTo, constant=STCWke_M_ImmedMinOffSwitchTo}  # Swith point where Min immediated i switch from MinRunCurr to Min Off
          STCWke_M_P1ImmedCapMin_OV: category=VALUE, type=T_M_Nm_32_1_s16_n500to500, init-value=constant-reference={short-label=STCWke_M_P1ImmedCapMin_OV, constant=STCWke_M_P1ImmedCapMin_OV}  # P1 Min override value
          STCWke_M_P1ImmedMax_OV: category=VALUE, type=T_M_Nm_32_1_s16_n500to500, init-value=constant-reference={short-label=STCWke_M_P1ImmedMax_OV, constant=STCWke_M_P1ImmedMax_OV}  # P1 Min override value
          STCWke_M_P1MaxERSOvr: category=VALUE, type=T_M_Nm_32_1_s16_n1000to1000, init-value=constant-reference={short-label=STCWke_M_P1MaxERSOvr, constant=STCWke_M_P1MaxERSOvr}  # P1 Max ERS override value
          STCWke_M_P1MaxOvr: category=VALUE, type=T_M_Nm_32_1_s16_n1000to1000, init-value=constant-reference={short-label=STCWke_M_P1MaxOvr, constant=STCWke_M_P1MaxOvr}  # P1 Max override value
          STCWke_M_P1MinERSOvr: category=VALUE, type=T_M_Nm_32_1_s16_n1000to1000, init-value=constant-reference={short-label=STCWke_M_P1MinERSOvr, constant=STCWke_M_P1MinERSOvr}  # P1 Min ERS override value
          STCWke_M_P1MinOvr: category=VALUE, type=T_M_Nm_32_1_s16_n1000to1000, init-value=constant-reference={short-label=STCWke_M_P1MinOvr, constant=STCWke_M_P1MinOvr}  # P1 Min override value
          STCWke_M_P1MtrToWheelMax: category=VALUE, type=T_M_Nm_32_1_s16, init-value=constant-reference={short-label=STCWke_M_P1MtrToWheelMax, constant=STCWke_M_P1MtrToWheelMax}  # Possibilty to limit P1 motor torque contribution to Wheel torque
          STCWke_M_P1MtrToWheelMin: category=VALUE, type=T_M_Nm_32_1_s16, init-value=constant-reference={short-label=STCWke_M_P1MtrToWheelMin, constant=STCWke_M_P1MtrToWheelMin}  # Possibility to limit P1 motor min contribution to Wheel torque
          STCWke_dM_P1NegTrqOnRate: category=VALUE, type=T_M_Nm_32_1_s16_n500to0, init-value=constant-reference={short-label=STCWke_dM_P1NegTrqOnRate, constant=STCWke_dM_P1NegTrqOnRate}  # ###Description Defines how fast the allowed negative P1 torque shall be allowed on wheels when stated the transmssions has control of the P1 speed and torque, i.e. STCWve_b_P1NegativeTrgAlloedAtWheel == True
          STCWke_dM_P1NegTrqShutOffRate: category=VALUE, type=T_M_Nm_32_1_s16_0to500, init-value=constant-reference={short-label=STCWke_dM_P1NegTrqShutOffRate, constant=STCWke_dM_P1NegTrqShutOffRate}  # Defines how fast the allowed torque negative P1 torque on wheel shall be shut off when driveline is open and transmission does not have control of the speed and torque on P1
          STCWkn_M_MaxLimitFilterTorqueCloseToZero: category=COM_AXIS, type=Appl_STCWkn_M_MaxLimitFilterTorqueCloseToZero, init-value=constant-reference={short-label=STCWkn_M_MaxLimitFilterTorqueCloseToZero, constant=STCWkn_M_MaxLimitFilterTorqueCloseToZero}
          STCWkn_M_MinLimitFilterTorqueCloseToZero: category=COM_AXIS, type=Appl_STCWkn_M_MinLimitFilterTorqueCloseToZero, init-value=constant-reference={short-label=STCWkn_M_MinLimitFilterTorqueCloseToZero, constant=STCWkn_M_MinLimitFilterTorqueCloseToZero}
          STCWkt_M_MaxLimitFilterTorqueCloseToZero: category=CURVE, type=Appl_STCWkt_M_MaxLimitFilterTorqueCloseToZero, init-value=constant-reference={short-label=STCWkt_M_MaxLimitFilterTorqueCloseToZero, constant=STCWkt_M_MaxLimitFilterTorqueCloseToZero}  # Rate limit for max limit when the torque is close to zero
          STCWkt_M_MinLimitFilterTorqueCloseToZero: category=CURVE, type=Appl_STCWkt_M_MinLimitFilterTorqueCloseToZero, init-value=constant-reference={short-label=STCWkt_M_MinLimitFilterTorqueCloseToZero, constant=STCWkt_M_MinLimitFilterTorqueCloseToZero}
          STCWkn_Pct_ClchCmdCapFactorAx: category=COM_AXIS, type=Appl_STCWkn_Pct_ClchCmdCapFactorAx, init-value=constant-reference={short-label=STCWkn_Pct_ClchCmdCapFactorAx, constant=STCWkn_Pct_ClchCmdCapFactorAx}  # Axis to STCWkt_f_ClchCmdCapFactor
          STCWke_n_FC_Gear1Disable: category=VALUE, type=T_n_rpm_1_1_s16_0to8000, init-value=constant-reference={short-label=STCWke_n_FC_Gear1Disable, constant=STCWke_n_FC_Gear1Disable}  # Engine speed at which fuelcut is disabled in gear 1
          STCWke_n_FC_Gear1Enable: category=VALUE, type=T_n_rpm_1_1_s16_0to8000, init-value=constant-reference={short-label=STCWke_n_FC_Gear1Enable, constant=STCWke_n_FC_Gear1Enable}  # Engine speed at which fuelcut is enabled in gear 1
          STCWke_n_FC_Gear2Disable: category=VALUE, type=T_n_rpm_1_1_s16_0to8000, init-value=constant-reference={short-label=STCWke_n_FC_Gear2Disable, constant=STCWke_n_FC_Gear2Disable}  # Engine speed at which fuelcut is disabled in gear 2
          STCWke_n_FC_Gear2Enable: category=VALUE, type=T_n_rpm_1_1_s16_0to8000, init-value=constant-reference={short-label=STCWke_n_FC_Gear2Enable, constant=STCWke_n_FC_Gear2Enable}  # Engine speed at which fuelcut is enabled in gear 2
          STCWke_n_FC_Gear3Disable: category=VALUE, type=T_n_rpm_1_1_s16_0to8000, init-value=constant-reference={short-label=STCWke_n_FC_Gear3Disable, constant=STCWke_n_FC_Gear3Disable}  # Engine speed at which fuelcut is disabled in gear 3
          STCWke_n_FC_Gear3Enable: category=VALUE, type=T_n_rpm_1_1_s16_0to8000, init-value=constant-reference={short-label=STCWke_n_FC_Gear3Enable, constant=STCWke_n_FC_Gear3Enable}  # Engine speed at which fuelcut is enabled in gear 3
          STCWke_n_FC_Gear4Disable: category=VALUE, type=T_n_rpm_1_1_s16_0to8000, init-value=constant-reference={short-label=STCWke_n_FC_Gear4Disable, constant=STCWke_n_FC_Gear4Disable}  # Engine speed at which fuelcut is disabled in gear 4
          STCWke_n_FC_Gear4Enable: category=VALUE, type=T_n_rpm_1_1_s16_0to8000, init-value=constant-reference={short-label=STCWke_n_FC_Gear4Enable, constant=STCWke_n_FC_Gear4Enable}  # Engine speed at which fuelcut is enabled in gear 4
          STCWke_n_FC_Gear5Disable: category=VALUE, type=T_n_rpm_1_1_s16_0to8000, init-value=constant-reference={short-label=STCWke_n_FC_Gear5Disable, constant=STCWke_n_FC_Gear5Disable}  # Engine speed at which fuelcut is disabled in gear 5
          STCWke_n_FC_Gear5Enable: category=VALUE, type=T_n_rpm_1_1_s16_0to8000, init-value=constant-reference={short-label=STCWke_n_FC_Gear5Enable, constant=STCWke_n_FC_Gear5Enable}  # Engine speed at which fuelcut is enabled in gear 5
          STCWke_n_FC_Gear6Disable: category=VALUE, type=T_n_rpm_1_1_s16_0to8000, init-value=constant-reference={short-label=STCWke_n_FC_Gear6Disable, constant=STCWke_n_FC_Gear6Disable}  # Engine speed at which fuelcut is disabled in gear 6
          STCWke_n_FC_Gear6Enable: category=VALUE, type=T_n_rpm_1_1_s16_0to8000, init-value=constant-reference={short-label=STCWke_n_FC_Gear6Enable, constant=STCWke_n_FC_Gear6Enable}  # Engine speed at which fuelcut is enabled in gear 6
          STCWke_n_FC_GearRvrsDisable: category=VALUE, type=T_n_rpm_1_1_s16_0to8000, init-value=constant-reference={short-label=STCWke_n_FC_GearRvrsDisable, constant=STCWke_n_FC_GearRvrsDisable}  # Engine speed at which fuelcut is disabled in gear Rvrs
          STCWke_n_FC_GearRvrsEnable: category=VALUE, type=T_n_rpm_1_1_s16_0to8000, init-value=constant-reference={short-label=STCWke_n_FC_GearRvrsEnable, constant=STCWke_n_FC_GearRvrsEnable}  # Engine speed at which fuelcut is enabled in gear Rvrs
          STCWkn_n_MtrAMinLimSclAxis: category=COM_AXIS, type=Appl_STCWkn_n_MtrAMinLimSclAxis, init-value=constant-reference={short-label=STCWkn_n_MtrAMinLimSclAxis, constant=STCWkn_n_MtrAMinLimSclAxis}  # Axis to STCWkt_r_MtrAMinLimScl
          STCWke_r_MarginForFilteringCloseToZero: category=VALUE, type=T_r_NA_1024_1_u16, init-value=constant-reference={short-label=STCWke_r_MarginForFilteringCloseToZero, constant=STCWke_r_MarginForFilteringCloseToZero}  # Margin for putting some time for having more filtering when the torque is close to zero.
          STCWke_scl_CluToEMfactor: category=VALUE, type=T_r_NA_1024_1_u16_1to3, init-value=constant-reference={short-label=STCWke_scl_CluToEMfactor, constant=STCWke_scl_CluToEMfactor}  # ###Description Scaling-factor >=1, to make EM cap react faster. ###Usage Use this to make EM cap react fast on clucth pedal movement ###Calibration Note Used for manual transmission
          STCWke_dr_GearAvailDsblRate: category=VALUE, type=T_r_NA_16384_1_s16_n1to0, init-value=constant-reference={short-label=STCWke_dr_GearAvailDsblRate, constant=STCWke_dr_GearAvailDsblRate}  # Defines how fast P1 to wheel capabilities shall be disabled when gear is available. I.e. when GSCHve_b_GearAvailable = False
          STCWke_dr_GearAvailEnbleRate: category=VALUE, type=T_r_NA_16384_1_s16_0to1, init-value=constant-reference={short-label=STCWke_dr_GearAvailEnbleRate, constant=STCWke_dr_GearAvailEnbleRate}  # Defines how fast P1 to wheel capabilities shall be enabled when gear is available. I.e. when GSCHve_b_GearAvailable = True
          STCWke_dr_SwitchRateDisableExtended: category=VALUE, type=T_r_NA_16384_1_s16_0to1, init-value=constant-reference={short-label=STCWke_dr_SwitchRateDisableExtended, constant=STCWke_dr_SwitchRateDisableExtended}  # Defines at which rate the capability shall be ramped when extended torque range i disabled
          STCWke_dr_SwitchRateDisableFC: category=VALUE, type=T_r_NA_16384_1_s16_0to1, init-value=constant-reference={short-label=STCWke_dr_SwitchRateDisableFC, constant=STCWke_dr_SwitchRateDisableFC}  # Switch rate when disabling fuelcut torque range. Swithcing from minoff to MinRun
          STCWke_dr_SwitchRateEnableExtended: category=VALUE, type=T_r_NA_16384_1_s16_0to1, init-value=constant-reference={short-label=STCWke_dr_SwitchRateEnableExtended, constant=STCWke_dr_SwitchRateEnableExtended}  # Switch Rate between Max and Max Ext when enabling Extended torque range
          STCWke_dr_SwitchRateEnableFC: category=VALUE, type=T_r_NA_16384_1_s16_0to1, init-value=constant-reference={short-label=STCWke_dr_SwitchRateEnableFC, constant=STCWke_dr_SwitchRateEnableFC}  # Switch rate when enabling FuelCut, ramping between MinRun to MinOff
          STCWkn_f_CapFactAtCluPedAxis: category=COM_AXIS, type=Appl_STCWkn_f_CapFactAtCluPedAxis, init-value=constant-reference={short-label=STCWkn_f_CapFactAtCluPedAxis, constant=STCWkn_f_CapFactAtCluPedAxis}  # Axis for scaling capabilities with relative distance from clutch drag point. [-1, 1]
          STCWkt_f_CapFactAtCluPed: category=CURVE, type=Appl_STCWkt_f_CapFactAtCluPed, init-value=constant-reference={short-label=STCWkt_f_CapFactAtCluPed, constant=STCWkt_f_CapFactAtCluPed}  # ###Description Output table for scaling capabilities depending on distance from clutch grippoint ###Usage Use this table to calibrate how the P3/P4 motor capabilities shall be scaled as function of clutch pedal posistion ###Calibration Note This is to be used for manual transmission and is only used depending on the calibration STCWke_e_CluToEmFactMethod
          STCWkt_f_ClchCmdCapFactor: category=CURVE, type=Appl_STCWkt_f_ClchCmdCapFactor, init-value=constant-reference={short-label=STCWkt_f_ClchCmdCapFactor, constant=STCWkt_f_ClchCmdCapFactor}  # ###Description Output table for scaling capabilities with clutch command in active range ###Usage Use this table to calibrate how the P3/P4 motor capabilities shall be scaled as function of clutch pedal posistion ###Calibration Note This is to be used for manual transmission and is only used depending on the calibration STCWke_e_CluToEmFactMethod
          STCWkt_r_MtrAMinLimScl: category=CURVE, type=Appl_STCWkt_r_MtrAMinLimScl, init-value=constant-reference={short-label=STCWkt_r_MtrAMinLimScl, constant=STCWkt_r_MtrAMinLimScl}  # ###Description This table scales tha available Min torque from the P1 motor ###Usage Use this table to prevent the P1motor to start rotating backwards. ###Calibration Note This is intended to be used if having a P1 motor
          STCWkt_r_PartOfTotalCpbyD: category=CURVE, type=Appl_STCWkt_r_PartOfTotalCpbyD, init-value=constant-reference={short-label=STCWkt_r_PartOfTotalCpbyD, constant=STCWkt_r_PartOfTotalCpbyD}  # ###Description Part of total torque, Drive-Rampout. Scales the torque capbility that can accelerate the vehicle in the opposite direction to the driver intended direction. ###Usage Use this table to define how the torque capabilities shall be scaled when the speed is close to zero, i.e. approaching an unwanted direction. ###Calibration Note
          STCWkt_r_PartOfTotalCpbyR: category=CURVE, type=Appl_STCWkt_r_PartOfTotalCpbyR, init-value=constant-reference={short-label=STCWkt_r_PartOfTotalCpbyR, constant=STCWkt_r_PartOfTotalCpbyR}  # ###Description Part of total torque, Reverse-rampout. Scales the torque capbility that can accelerate the vehicle in the opposite direction to the driver intended direction. ###Usage Use this table to define how the torque capabilities shall be scaled when the speed is close to zero, i.e. approaching an unwanted direction. ###Calibration Note
          STCWkt_r_RearPartOfTotalCpbyD: category=CURVE, type=Appl_STCWkt_r_RearPartOfTotalCpbyD, init-value=constant-reference={short-label=STCWkt_r_RearPartOfTotalCpbyD, constant=STCWkt_r_RearPartOfTotalCpbyD}  # ###Description Part of total torque, Drive-Rampout. Scales the torque capbility that can accelerate the vehicle in the opposite direction to the driver intended direction. ###Usage Use this table to define how the torque capabilities shall be scaled when the speed is close to zero, i.e. approaching an unwanted direction. ###Calibration Note
          STCWkt_r_RearPartOfTotalCpbyR: category=CURVE, type=Appl_STCWkt_r_RearPartOfTotalCpbyR, init-value=constant-reference={short-label=STCWkt_r_RearPartOfTotalCpbyR, constant=STCWkt_r_RearPartOfTotalCpbyR}  # ###Description Part of total torque, Reverse-rampout. Scales the torque capbility that can accelerate the vehicle in the opposite direction to the driver intended direction. ###Usage Use this table to define how the torque capabilities shall be scaled when the speed is close to zero, i.e. approaching an unwanted direction. ###Calibration Note
          STCWke_t_ParkLockInhibitDuration: category=VALUE, type=T_t_s_100_1_s16_0to327, init-value=constant-reference={short-label=STCWke_t_ParkLockInhibitDuration, constant=STCWke_t_ParkLockInhibitDuration}  # The time to allow propulsion when ParkLock is not released.
          STCWke_t_SafetyTorqueRampTimeDown: category=VALUE, type=T_t_s_100_1_s16_0to1, init-value=constant-reference={short-label=STCWke_t_SafetyTorqueRampTimeDown, constant=STCWke_t_SafetyTorqueRampTimeDown}  # Defines in how long time the capability shall be ramped towards zero when brake regen is shutoff
          STCWke_t_SampleTime: category=VALUE, type=T_t_s_100_1_s16_0to2, init-value=constant-reference={short-label=STCWke_t_SampleTime, constant=STCWke_t_SampleTime}  # Sample time of STCW
          STCWke_v_VehicleSpeedLimitForMaxCapabilityReduction: category=VALUE, type=T_v_kph_64_1_s16, init-value=constant-reference={short-label=STCWke_v_VehicleSpeedLimitForMaxCapabilityReduction, constant=STCWke_v_VehicleSpeedLimitForMaxCapabilityReduction}  # Vehicle speed limit for the max capability reduction, above this value and when the gear is reverse, the max capability shall be ramped down to 0.
          STCWke_v_VehicleSpeedLimitForMinCapabilityReduction: category=VALUE, type=T_v_kph_64_1_s16, init-value=constant-reference={short-label=STCWke_v_VehicleSpeedLimitForMinCapabilityReduction, constant=STCWke_v_VehicleSpeedLimitForMinCapabilityReduction}  # Vehicle speed limit for the min capability reduction, below this value and when the direction is forward, the min capability shall be ramped to 0.
          STCWkn_v_BrkRgnSpeedAxis: category=COM_AXIS, type=Appl_STCWkn_v_BrkRgnSpeedAxis, init-value=constant-reference={short-label=STCWkn_v_BrkRgnSpeedAxis, constant=STCWkn_v_BrkRgnSpeedAxis}  # Axis of absolute vehicle speed for ramping out brake regen capability in low speed. Axis to STCWkt_K_BrkRgnRampOut.
          STCWkn_v_RearVehSpdX: category=COM_AXIS, type=Appl_STCWkn_v_RearVehSpdX, init-value=constant-reference={short-label=STCWkn_v_RearVehSpdX, constant=STCWkn_v_RearVehSpdX}  # Axis to STCWkt_r_PartOfTotalCpbyR and STCWkt_r_PartOfTotalCpbyD.
          STCWkn_v_VehSpdX: category=COM_AXIS, type=Appl_STCWkn_v_VehSpdX, init-value=constant-reference={short-label=STCWkn_v_VehSpdX, constant=STCWkn_v_VehSpdX}  # Axis to STCWkt_r_PartOfTotalCpbyR and STCWkt_r_PartOfTotalCpbyD.
          STCWie_e_PrplsAllowed_OV: category=VALUE, type=DPSCte_e_PrplsAllowed, init-value=constant-reference={short-label=STCWie_e_PrplsAllowed_OV, constant=STCWie_e_PrplsAllowed_OV}  # Override value
          STCWke_e_CluToEmFactMethod: category=VALUE, type=STCWte_e_CluToEmType, init-value=constant-reference={short-label=STCWke_e_CluToEmFactMethod, constant=STCWke_e_CluToEmFactMethod}  # ###Description Selection of method for scaling capabilities with clutch pedal position. ###Usage Simple scaling: independant of drag point CluCmdMap: Map with scale factor depending on clutch command. DragPointDistance: Map with scale factor depending on relative distance (pos/neg) from drag point. Clu pedal at drag point means relative distance = zero! ###Calibration Only for manual transmissions
          STCWie_b_DisableExtTrqAndFCAbritation: category=BOOLEAN, type=T_BOOLEAN, init-value=constant-reference={short-label=STCWie_b_DisableExtTrqAndFCAbritation, constant=STCWie_b_DisableExtTrqAndFCAbritation}  # Temp switch to disable the use off Fuel Cut allowed and extended torque range arbitration functionality
          STCWie_b_DisableP1ImmedCaps: category=BOOLEAN, type=T_BOOLEAN, init-value=constant-reference={short-label=STCWie_b_DisableP1ImmedCaps, constant=STCWie_b_DisableP1ImmedCaps}  # If True the Immed Caps the P1 Caps is set to -+500Nm
          STCWie_b_DrvrTqDmEMTotCpbyMax_OB: category=BOOLEAN, type=T_BOOLEAN, init-value=constant-reference={short-label=STCWie_b_DrvrTqDmEMTotCpbyMax_OB, constant=STCWie_b_DrvrTqDmEMTotCpbyMax_OB}  # Override Enable
          STCWie_b_DrvrTqDmEMTotCpbyMin_OB: category=BOOLEAN, type=T_BOOLEAN, init-value=constant-reference={short-label=STCWie_b_DrvrTqDmEMTotCpbyMin_OB, constant=STCWie_b_DrvrTqDmEMTotCpbyMin_OB}  # Override enable
          STCWie_b_EngMaxPM_DrvrDmn_OB: category=BOOLEAN, type=T_BOOLEAN, init-value=constant-reference={short-label=STCWie_b_EngMaxPM_DrvrDmn_OB, constant=STCWie_b_EngMaxPM_DrvrDmn_OB}  # Override enable
          STCWie_b_FuelCutAllowedPropulsion_OB: category=BOOLEAN, type=T_BOOLEAN, init-value=constant-reference={short-label=STCWie_b_FuelCutAllowedPropulsion_OB, constant=STCWie_b_FuelCutAllowedPropulsion_OB}  # Overide enable
          STCWie_b_FuelCutAllowedPropulsion_OV: category=BOOLEAN, type=T_BOOLEAN, init-value=constant-reference={short-label=STCWie_b_FuelCutAllowedPropulsion_OV, constant=STCWie_b_FuelCutAllowedPropulsion_OV}  # override value
          STCWie_b_MaxFrontTorqueWithoutBattLIimit_OB: category=BOOLEAN, type=T_BOOLEAN, init-value=constant-reference={short-label=STCWie_b_MaxFrontTorqueWithoutBattLIimit_OB, constant=STCWie_b_MaxFrontTorqueWithoutBattLIimit_OB}  # Override Enable
          STCWie_b_MaxRearDrvDmn_OB: category=BOOLEAN, type=T_BOOLEAN, init-value=constant-reference={short-label=STCWie_b_MaxRearDrvDmn_OB, constant=STCWie_b_MaxRearDrvDmn_OB}
          STCWie_b_MaxRearTorqueWithoutBattLIimit_OB: category=BOOLEAN, type=T_BOOLEAN, init-value=constant-reference={short-label=STCWie_b_MaxRearTorqueWithoutBattLIimit_OB, constant=STCWie_b_MaxRearTorqueWithoutBattLIimit_OB}
          STCWie_b_MinFrontTorqueWithoutBattLIimit_OB: category=BOOLEAN, type=T_BOOLEAN, init-value=constant-reference={short-label=STCWie_b_MinFrontTorqueWithoutBattLIimit_OB, constant=STCWie_b_MinFrontTorqueWithoutBattLIimit_OB}
          STCWie_b_MinRearDrvDmn_OB: category=BOOLEAN, type=T_BOOLEAN, init-value=constant-reference={short-label=STCWie_b_MinRearDrvDmn_OB, constant=STCWie_b_MinRearDrvDmn_OB}
          STCWie_b_MinRearTorqueWithoutBattLIimit_OB: category=BOOLEAN, type=T_BOOLEAN, init-value=constant-reference={short-label=STCWie_b_MinRearTorqueWithoutBattLIimit_OB, constant=STCWie_b_MinRearTorqueWithoutBattLIimit_OB}
          STCWie_b_P1SysTransControlled_OB: category=BOOLEAN, type=T_BOOLEAN, init-value=constant-reference={short-label=STCWie_b_P1SysTransControlled_OB, constant=STCWie_b_P1SysTransControlled_OB}  # Override enable
          STCWie_b_P1SysTransControlled_OV: category=BOOLEAN, type=T_BOOLEAN, init-value=constant-reference={short-label=STCWie_b_P1SysTransControlled_OV, constant=STCWie_b_P1SysTransControlled_OV}  # Override value
          STCWie_b_PrplsAllowed_OB: category=BOOLEAN, type=T_BOOLEAN, init-value=constant-reference={short-label=STCWie_b_PrplsAllowed_OB, constant=STCWie_b_PrplsAllowed_OB}  # Override enable
          STCWie_b_ReplaceEngERSCapsWthCurrSpd: category=BOOLEAN, type=T_BOOLEAN, init-value=constant-reference={short-label=STCWie_b_ReplaceEngERSCapsWthCurrSpd, constant=STCWie_b_ReplaceEngERSCapsWthCurrSpd}  # Temp switch to replace engine ERS caps with torque caps at current speed
          STCWie_b_SeriesModeMinWhlDmn_OB: category=BOOLEAN, type=T_BOOLEAN, init-value=constant-reference={short-label=STCWie_b_SeriesModeMinWhlDmn_OB, constant=STCWie_b_SeriesModeMinWhlDmn_OB}  # Override Enable
          STCWke_b_AlwaysEnableFuelcut: category=BOOLEAN, type=T_BOOLEAN, init-value=constant-reference={short-label=STCWke_b_AlwaysEnableFuelcut, constant=STCWke_b_AlwaysEnableFuelcut}  # FuelCut always enabled, i.e. STCW that disables fuelcut certain gear as function of engine speed is disabled
          STCWke_b_BrakeRegenLowPedalEnable: category=BOOLEAN, type=T_BOOLEAN, init-value=constant-reference={short-label=STCWke_b_BrakeRegenLowPedalEnable, constant=STCWke_b_BrakeRegenLowPedalEnable}  # Set to to true to enabled Brake regen shut off when driver request not is close to zero pedal
          STCWke_b_BrakeRegenUseZeroPedal: category=BOOLEAN, type=T_BOOLEAN, init-value=constant-reference={short-label=STCWke_b_BrakeRegenUseZeroPedal, constant=STCWke_b_BrakeRegenUseZeroPedal}  # This calibration defines if Zero pedal or a torque threshold defined by cal shall be used to enabled brake regen capability
          STCWke_b_BrkRgnCpbyOvr: category=BOOLEAN, type=T_BOOLEAN, init-value=constant-reference={short-label=STCWke_b_BrkRgnCpbyOvr, constant=STCWke_b_BrkRgnCpbyOvr}  # Override Enable
          STCWke_b_CluScaleActive: category=BOOLEAN, type=T_BOOLEAN, init-value=constant-reference={short-label=STCWke_b_CluScaleActive, constant=STCWke_b_CluScaleActive}  # ###Description Decides if scaling of capabilities with clutch pedal position is active. ###Usage Set to true to activate clutch scaling. ###Calibration Note Set to false if transmission is automatic - this functionality is for manual transmissions.
          STCWke_b_CluScaleUseCmd: category=BOOLEAN, type=T_BOOLEAN, init-value=constant-reference={short-label=STCWke_b_CluScaleUseCmd, constant=STCWke_b_CluScaleUseCmd}  # ###Description Used to slect which signal from clucth capbilities to use for scaling P3/P4 motor capabilitiies ###Usage If true, clutch command signal is used, instead of raw clutch position value, for scaling EM capabilities. ###Calibration Note This functionality is for manual transmissions
          STCWke_b_DisableP1ToWheelNoGear: category=BOOLEAN, type=T_BOOLEAN, init-value=constant-reference={short-label=STCWke_b_DisableP1ToWheelNoGear, constant=STCWke_b_DisableP1ToWheelNoGear}  # ###Description Enables the if nor gear is reported to be avaiable it will also disable the P1 capabilites possibility to transfer torque to the wheels ###Usage Set to to true to enable that Gearavailable disables that P1 capability is added to wheel caps
          STCWke_b_DrvrTqDmEngCpbyMaxOvr: category=BOOLEAN, type=T_BOOLEAN, init-value=constant-reference={short-label=STCWke_b_DrvrTqDmEngCpbyMaxOvr, constant=STCWke_b_DrvrTqDmEngCpbyMaxOvr}  # Override flag for max. engine torque in the driver domain.
          STCWke_b_DrvrTqDmEngCpbyMinOffOv: category=BOOLEAN, type=T_BOOLEAN, init-value=constant-reference={short-label=STCWke_b_DrvrTqDmEngCpbyMinOffOv, constant=STCWke_b_DrvrTqDmEngCpbyMinOffOv}  # Override flag for min. engine torque in the driver domain.
          STCWke_b_DrvrTqDmTotCpbyMax: category=BOOLEAN, type=T_BOOLEAN, init-value=constant-reference={short-label=STCWke_b_DrvrTqDmTotCpbyMax, constant=STCWke_b_DrvrTqDmTotCpbyMax}
          STCWke_b_DrvrTqDmTotCpbyMinOvr: category=BOOLEAN, type=T_BOOLEAN, init-value=constant-reference={short-label=STCWke_b_DrvrTqDmTotCpbyMinOvr, constant=STCWke_b_DrvrTqDmTotCpbyMinOvr}
          STCWke_b_EnableFilterCloseToZero: category=BOOLEAN, type=T_BOOLEAN, init-value=constant-reference={short-label=STCWke_b_EnableFilterCloseToZero, constant=STCWke_b_EnableFilterCloseToZero}
          STCWke_b_EnableSmoothCapabilityReduction: category=BOOLEAN, type=T_BOOLEAN, init-value=constant-reference={short-label=STCWke_b_EnableSmoothCapabilityReduction, constant=STCWke_b_EnableSmoothCapabilityReduction}
          STCWke_b_EnableSmoothCapabilityReductionForDirectionChange: category=BOOLEAN, type=T_BOOLEAN, init-value=constant-reference={short-label=STCWke_b_EnableSmoothCapabilityReductionForDirectionChange, constant=STCWke_b_EnableSmoothCapabilityReductionForDirectionChange}
          STCWke_b_EnblP1NegTrqAtWheelSwitchOff: category=BOOLEAN, type=T_BOOLEAN, init-value=constant-reference={short-label=STCWke_b_EnblP1NegTrqAtWheelSwitchOff, constant=STCWke_b_EnblP1NegTrqAtWheelSwitchOff}  # ###Description This calibration enables functionality to disable that P1 system can be used to put negative torque on wheel when transmisson not have control of the P1 speed and torque.
          STCWke_b_EnblTransLossComp: category=BOOLEAN, type=T_BOOLEAN, init-value=constant-reference={short-label=STCWke_b_EnblTransLossComp, constant=STCWke_b_EnblTransLossComp}  # ###Description This calibration enables compensation with transmission loss when calculating the P1 capabilities
          STCWke_b_FC_Gear{1..6}Enable: category=BOOLEAN, type=T_BOOLEAN, init-value=constant-reference={short-label=STCWke_b_FC_Gear{1..6}Enable, constant=STCWke_b_FC_Gear{1..6}Enable}  # Enable fuel cut in Gear {1..6}
          STCWke_b_FC_GearRvrsEnable: category=BOOLEAN, type=T_BOOLEAN, init-value=constant-reference={short-label=STCWke_b_FC_GearRvrsEnable, constant=STCWke_b_FC_GearRvrsEnable}  # Enable fuel cut in Gear Rvrs
          STCWke_b_FC_GearUndefinedEnable: category=BOOLEAN, type=T_BOOLEAN, init-value=constant-reference={short-label=STCWke_b_FC_GearUndefinedEnable, constant=STCWke_b_FC_GearUndefinedEnable}  # Enable fuel cut when gear is undefined
          STCWke_b_FrontAxleMaxOvr: category=BOOLEAN, type=T_BOOLEAN, init-value=constant-reference={short-label=STCWke_b_FrontAxleMaxOvr, constant=STCWke_b_FrontAxleMaxOvr}  # Override Enable
          STCWke_b_FrontAxleMinOvr: category=BOOLEAN, type=T_BOOLEAN, init-value=constant-reference={short-label=STCWke_b_FrontAxleMinOvr, constant=STCWke_b_FrontAxleMinOvr}  # Override value
          STCWke_b_FuelCutUseGSF_ForDrvbltRsp: category=BOOLEAN, type=T_BOOLEAN, init-value=constant-reference={short-label=STCWke_b_FuelCutUseGSF_ForDrvbltRsp, constant=STCWke_b_FuelCutUseGSF_ForDrvbltRsp}  # Enables to request look at Gear shift fuel cut allowed from ECOM when drivability filter requests fast response
          STCWke_b_HoldTrqDirectioEnable: category=BOOLEAN, type=T_BOOLEAN, init-value=constant-reference={short-label=STCWke_b_HoldTrqDirectioEnable, constant=STCWke_b_HoldTrqDirectioEnable}  # Enables to use a torque direction that holds the forward or reverse for a short period of time after it transistions to undefined
          STCWke_b_IdleLimOnlyOnIsg: category=BOOLEAN, type=T_BOOLEAN, init-value=constant-reference={short-label=STCWke_b_IdleLimOnlyOnIsg, constant=STCWke_b_IdleLimOnlyOnIsg}  # ###Description Decides if minimum allowed P1 torque from the idle controller is applied only on ISG (i.e. engine capability part is unlimited), or on P1 (i.e. engine + ISG is limited). ###Usage Set to TRUE to apply limit only on ISG capabilities. ###Calibration Note This calibration has no function: on wheel capabilities, if STCWke_b_LimitWheelCapabilityWithIdleLim is FALSE. on P1 capabilities, if STCWke_b_LimitWheelCapabilityWithIdleLim and STCWke_b_LimitP1CapabilityWithIdleLimit both are FALSE.
          STCWke_b_IncludeEMMtrImmedCap: category=BOOLEAN, type=T_BOOLEAN, init-value=constant-reference={short-label=STCWke_b_IncludeEMMtrImmedCap, constant=STCWke_b_IncludeEMMtrImmedCap}  # If true electric motors is included in the Immediate capabilities
          STCWke_b_InhibitBRWhenUpshift: category=BOOLEAN, type=T_BOOLEAN, init-value=constant-reference={short-label=STCWke_b_InhibitBRWhenUpshift, constant=STCWke_b_InhibitBRWhenUpshift}
          STCWke_b_LimitBoostInTotCapability: category=BOOLEAN, type=T_BOOLEAN, init-value=constant-reference={short-label=STCWke_b_LimitBoostInTotCapability, constant=STCWke_b_LimitBoostInTotCapability}  # Limits the total capability with the boost torque limitation from BORE
          STCWke_b_LimitP1CapWithP1Cap: category=BOOLEAN, type=T_BOOLEAN, init-value=constant-reference={short-label=STCWke_b_LimitP1CapWithP1Cap, constant=STCWke_b_LimitP1CapWithP1Cap}  # ###Description This enables the functionality to limit the minimum allowed P1 torque with the minimum limit from the idle controller with the same limit that is used for limiting P1 to wheel ###Usage Set to TRUE to enable correction of P1 min torque with idlecontroller min torque. If FALSE no correction is made
          STCWke_b_LimitP1CapabilityWithIdleLimit: category=BOOLEAN, type=T_BOOLEAN, init-value=constant-reference={short-label=STCWke_b_LimitP1CapabilityWithIdleLimit, constant=STCWke_b_LimitP1CapabilityWithIdleLimit}  # ###Description This enables the functionality to limit the minimum allowed P1 torque with the minimum limit from the idle controller ###Usage Set to TRUE to enable correction of P1 min torque with idlecontroller min torque. If FALSE no correction is made ###Calibration Note This calibration has no function if STCWke_b_LimitWheelCapabilityWithIdleLim is TRUE. If limiting of wheel torque is enables this will also enable the P1 torque capability
          STCWke_b_LimitWheelCapabilityWithIdleLim: category=BOOLEAN, type=T_BOOLEAN, init-value=constant-reference={short-label=STCWke_b_LimitWheelCapabilityWithIdleLim, constant=STCWke_b_LimitWheelCapabilityWithIdleLim}  # ###Description This enables the functionality to limit the minimum allowed P1 torque with the minimum limit from the idle controller ###Usage Set to TRUE to enable correction of P1 min torque with idlecontroller min torque. If FALSE no correction is made ###Calibration Note This calibration has no function if STCWke_b_LimitWheelCapabilityWithIdleLim is TRUE. If limiting of wheel torque is enables this will also enable the P1 torque capability
          STCWke_b_M18Project: category=BOOLEAN, type=T_BOOLEAN, init-value=constant-reference={short-label=STCWke_b_M18Project, constant=STCWke_b_M18Project}
          STCWke_b_MaxFrontDrvDmnOvr: category=BOOLEAN, type=T_BOOLEAN, init-value=constant-reference={short-label=STCWke_b_MaxFrontDrvDmnOvr, constant=STCWke_b_MaxFrontDrvDmnOvr}  # **
          STCWke_b_MinFrontDrvDmnOvr: category=BOOLEAN, type=T_BOOLEAN, init-value=constant-reference={short-label=STCWke_b_MinFrontDrvDmnOvr, constant=STCWke_b_MinFrontDrvDmnOvr}  # **
          STCWke_b_NoP1ToWhlTrqInRvrsEnbl: category=BOOLEAN, type=T_BOOLEAN, init-value=constant-reference={short-label=STCWke_b_NoP1ToWhlTrqInRvrsEnbl, constant=STCWke_b_NoP1ToWhlTrqInRvrsEnbl}  # ###Description Used to set the wheel torque capability from the P1 system when the driver intended torque direction is reverse. ###Usage If true STCW sets the wheel torque capability from the P1 actuators to zero in reverse ###Calibration Note Intended use is setting this to TRUE if the gearbox transferring torque from the P1 system to the wheels does not support reverse gear
          STCWke_b_NotLimitDrvrTqDmTotMinToEngMin: category=BOOLEAN, type=T_BOOLEAN, init-value=constant-reference={short-label=STCWke_b_NotLimitDrvrTqDmTotMinToEngMin, constant=STCWke_b_NotLimitDrvrTqDmTotMinToEngMin}  # If false the driver requested torque can only be down to EngMin + P3 Min This to avoid to not promize to a capabilty that we can not promize
          STCWke_b_OnlyAllowBrakeRegenInForward: category=BOOLEAN, type=T_BOOLEAN, init-value=constant-reference={short-label=STCWke_b_OnlyAllowBrakeRegenInForward, constant=STCWke_b_OnlyAllowBrakeRegenInForward}  # If true brake regen will only be allowed when driver intenededn torque direction is forward. If this calibration is false. Brake regen will be allowed when torque is allowed to be put on wheels by the driver. (Forward and Reverse)
          STCWke_b_P1ImmedCapMin_OB: category=BOOLEAN, type=T_BOOLEAN, init-value=constant-reference={short-label=STCWke_b_P1ImmedCapMin_OB, constant=STCWke_b_P1ImmedCapMin_OB}  # Override enable
          STCWke_b_P1ImmedMax_OB: category=BOOLEAN, type=T_BOOLEAN, init-value=constant-reference={short-label=STCWke_b_P1ImmedMax_OB, constant=STCWke_b_P1ImmedMax_OB}  # Override enable
          STCWke_b_P1MaxERSOvr: category=BOOLEAN, type=T_BOOLEAN, init-value=constant-reference={short-label=STCWke_b_P1MaxERSOvr, constant=STCWke_b_P1MaxERSOvr}  # Override enable
          STCWke_b_P1MaxOvr: category=BOOLEAN, type=T_BOOLEAN, init-value=constant-reference={short-label=STCWke_b_P1MaxOvr, constant=STCWke_b_P1MaxOvr}  # Override enable
          STCWke_b_P1MinERSOvr: category=BOOLEAN, type=T_BOOLEAN, init-value=constant-reference={short-label=STCWke_b_P1MinERSOvr, constant=STCWke_b_P1MinERSOvr}  # Override enable
          STCWke_b_P1MinOvr: category=BOOLEAN, type=T_BOOLEAN, init-value=constant-reference={short-label=STCWke_b_P1MinOvr, constant=STCWke_b_P1MinOvr}  # Override enable
          STCWke_b_ParkLockInhibitTimeEnable: category=BOOLEAN, type=T_BOOLEAN, init-value=constant-reference={short-label=STCWke_b_ParkLockInhibitTimeEnable, constant=STCWke_b_ParkLockInhibitTimeEnable}  # Enable use of maximum time for ParkLock to inhibit propulsion. If true, ParkLock can not inhibit Propulsion Allowed for more than STCWke_t_ParkLockInhibitDuration seconds. If false, ParkLock will always inhibit Propulsion Allowed if it is not \Open\.
          STCWke_b_PrplsAllowedDisableDirectionDep: category=BOOLEAN, type=T_BOOLEAN, init-value=constant-reference={short-label=STCWke_b_PrplsAllowedDisableDirectionDep, constant=STCWke_b_PrplsAllowedDisableDirectionDep}  # Description: Set to true if Propulsion allowed shall be independent of Driver intended direction.
          STCWke_b_PrplsAllowedDisableFuncActDep: category=BOOLEAN, type=T_BOOLEAN, init-value=constant-reference={short-label=STCWke_b_PrplsAllowedDisableFuncActDep, constant=STCWke_b_PrplsAllowedDisableFuncActDep}  # Description: Set to true if Propulsion allowed shall be independent of Function Action
          STCWke_b_PrplsAllowedDisableParkLockInhibit: category=BOOLEAN, type=T_BOOLEAN, init-value=constant-reference={short-label=STCWke_b_PrplsAllowedDisableParkLockInhibit, constant=STCWke_b_PrplsAllowedDisableParkLockInhibit}  # If true park lock inhibit propulsion is disabled.
          STCWke_b_PrplsAllowedDisablePowerModeDep: category=BOOLEAN, type=T_BOOLEAN, init-value=constant-reference={short-label=STCWke_b_PrplsAllowedDisablePowerModeDep, constant=STCWke_b_PrplsAllowedDisablePowerModeDep}  # Description: Set to true if Propulsion allowed shall be independent of PowerMode
          STCWke_b_RdcBrkRgnWithActCstTq: category=BOOLEAN, type=T_BOOLEAN, init-value=constant-reference={short-label=STCWke_b_RdcBrkRgnWithActCstTq, constant=STCWke_b_RdcBrkRgnWithActCstTq}  # ###Description Enables/disables it actual coast regen demand is subtracted from Brake Regen Capability ###Usage If false, Actual Coast Regen has no effect on Brake Regen Capability If true, the Brake Regen Capability is reduced with how much torque is actually demanded by Coast Regen. ###Calibration Note
          STCWke_b_RearAxleMaxESCOvr: category=BOOLEAN, type=T_BOOLEAN, init-value=constant-reference={short-label=STCWke_b_RearAxleMaxESCOvr, constant=STCWke_b_RearAxleMaxESCOvr}  # Override value
          STCWke_b_RearAxleMinESCOvr: category=BOOLEAN, type=T_BOOLEAN, init-value=constant-reference={short-label=STCWke_b_RearAxleMinESCOvr, constant=STCWke_b_RearAxleMinESCOvr}
          STCWke_b_SeriesModeMaxWhlDmnOvr: category=BOOLEAN, type=T_BOOLEAN, init-value=constant-reference={short-label=STCWke_b_SeriesModeMaxWhlDmnOvr, constant=STCWke_b_SeriesModeMaxWhlDmnOvr}  # Override flag for min. total torque in the driver domain.
          STCWke_b_SignChgLockOnP1Min: category=BOOLEAN, type=T_BOOLEAN, init-value=constant-reference={short-label=STCWke_b_SignChgLockOnP1Min, constant=STCWke_b_SignChgLockOnP1Min}  # ###Description Decides if sign change lockout is active on minimum P1capabilities. ###Usage If TRUE, sign change lockout is active. If FALSE, sign change lockout is deactivated on STCWve_M_P1Min and STCWve_M_P1MinERS. ###Calibration Note ISG (idle control not handled by HCU): Value shall be TRUE. PHEV ((idle control handled by HCU)): Value shall be FALSE.
          STCWke_b_SubADSNegTrqInBrkRgn: category=BOOLEAN, type=T_BOOLEAN, init-value=constant-reference={short-label=STCWke_b_SubADSNegTrqInBrkRgn, constant=STCWke_b_SubADSNegTrqInBrkRgn}  # ###Description Enables/disables it actual coast regen demand is subtracted from Brake Regen Capability ###Usage If false, Actual Coast Regen has no effect on Brake Regen Capability If true, the Brake Regen Capability is reduced with how much torque is actually demanded by Coast Regen. ###Calibration Note
          STCWke_b_UseDITDForTransWHLCaps: category=BOOLEAN, type=T_BOOLEAN, init-value=constant-reference={short-label=STCWke_b_UseDITDForTransWHLCaps, constant=STCWke_b_UseDITDForTransWHLCaps}  # Calibration to choose to have driver direction dependancy or not
          STCWke_b_UseEMTotCapForBrkRegenCapCalc: category=BOOLEAN, type=T_BOOLEAN, init-value=constant-reference={short-label=STCWke_b_UseEMTotCapForBrkRegenCapCalc, constant=STCWke_b_UseEMTotCapForBrkRegenCapCalc}  # If true and STCWke_b_UseTotCapForBrkRegenCapCalc is false the brake regen capability is calculated based on the total torque from the electrical motors. P1+P3
          STCWke_b_UseMinRunLTForWhl: category=BOOLEAN, type=T_BOOLEAN, init-value=constant-reference={short-label=STCWke_b_UseMinRunLTForWhl, constant=STCWke_b_UseMinRunLTForWhl}  # True, MinRunLt is used a miniumum torque limit for wheel torque functions False MinRun is used
          STCWke_b_UseP1MotorERSCaps: category=BOOLEAN, type=T_BOOLEAN, init-value=constant-reference={short-label=STCWke_b_UseP1MotorERSCaps, constant=STCWke_b_UseP1MotorERSCaps}  # ###Description This enables the use of ERS capabilities of P1 motor to calculate wheel torque capabilities ###Usage True in vehicle were the engine is stopped in speed and there is a need to know what capability the we would have at whells if engine was commanded to be running
          STCWke_b_UseP3MotorForBrakeRegenCap: category=BOOLEAN, type=T_BOOLEAN, init-value=constant-reference={short-label=STCWke_b_UseP3MotorForBrakeRegenCap, constant=STCWke_b_UseP3MotorForBrakeRegenCap}  # If true, available P3 Motor torque for brake regen will be used
          STCWke_b_UseP4MotorForBrakeRegenCap: category=BOOLEAN, type=T_BOOLEAN, init-value=constant-reference={short-label=STCWke_b_UseP4MotorForBrakeRegenCap, constant=STCWke_b_UseP4MotorForBrakeRegenCap}  # If true, available P4 motor torque is used for brake regen capabilities
          STCWke_b_UsePredictedToDetectTransCntrl: category=BOOLEAN, type=T_BOOLEAN, init-value=constant-reference={short-label=STCWke_b_UsePredictedToDetectTransCntrl, constant=STCWke_b_UsePredictedToDetectTransCntrl}  # ###Description Use the transmission predicted torque control limit to say that the transmission is in control of the P1 system. ###Note This shall be calibrated together with calibrations in TIRC. This calibration shall be true if TIRC is calibrated to lower the P1 immediate command with the Predicted request
          STCWke_b_UsePrplsAllwd: category=BOOLEAN, type=T_BOOLEAN, init-value=constant-reference={short-label=STCWke_b_UsePrplsAllwd, constant=STCWke_b_UsePrplsAllwd}  # ###Description Decides whether Propulsion Allowed is used on (P1 + P3) wheel capabilities. ###Usage ###Calibration Note ISG: Value shall be FALSE. PHEV: Value shall be TRUE.
          STCWke_b_UseTotCapForBrkRegenCapCalc: category=BOOLEAN, type=T_BOOLEAN, init-value=constant-reference={short-label=STCWke_b_UseTotCapForBrkRegenCapCalc, constant=STCWke_b_UseTotCapForBrkRegenCapCalc}  # ###Description Defines which capaility that shall be used to calculate the brake regen capability ###Usage If true brake regen can be allowed to use the total driver torque capability. If false brake regen is calculated from the Electric torque capability at wheels.
          STCWke_b_WhlTqDmP3CpbySTMaxOvr: category=BOOLEAN, type=T_BOOLEAN, init-value=constant-reference={short-label=STCWke_b_WhlTqDmP3CpbySTMaxOvr, constant=STCWke_b_WhlTqDmP3CpbySTMaxOvr}
          STCWke_b_WhlTqDmP3CpbySTMinOvr: category=BOOLEAN, type=T_BOOLEAN, init-value=constant-reference={short-label=STCWke_b_WhlTqDmP3CpbySTMinOvr, constant=STCWke_b_WhlTqDmP3CpbySTMinOvr}
          STCWke_b_WhlTqDmTotCpbyMaxOvr: category=BOOLEAN, type=T_BOOLEAN, init-value=constant-reference={short-label=STCWke_b_WhlTqDmTotCpbyMaxOvr, constant=STCWke_b_WhlTqDmTotCpbyMaxOvr}
          STCWke_b_WhlTqDmTotCpbyMinOvr: category=BOOLEAN, type=T_BOOLEAN, init-value=constant-reference={short-label=STCWke_b_WhlTqDmTotCpbyMinOvr, constant=STCWke_b_WhlTqDmTotCpbyMinOvr}
package /STCW_pkg/STCW_if
  144 x sender receiver interface:
    ITCCve_M_EngMaxTrq
      data ITCCve_M_EngMaxTrq: category=VALUE, sw-calibration-access=READ-ONLY, type=T_M_Nm_32_1_s16
    ITCCve_M_EngMinOffTrq
      data ITCCve_M_EngMinOffTrq: category=VALUE, sw-calibration-access=READ-ONLY, type=T_M_Nm_32_1_s16
    ITCCve_M_EngMaxTrqERS
      data ITCCve_M_EngMaxTrqERS: category=VALUE, sw-calibration-access=READ-ONLY, type=T_M_Nm_32_1_s16
    ITCCve_M_EngMinOffTrqERS
      data ITCCve_M_EngMinOffTrqERS: category=VALUE, sw-calibration-access=READ-ONLY, type=T_M_Nm_32_1_s16
    MTCSve_M_P1MaxTrq
      data MTCSve_M_P1MaxTrq: category=VALUE, sw-calibration-access=READ-ONLY, type=T_M_Nm_Float32
    MTCSve_M_P1MinTrq
      data MTCSve_M_P1MinTrq: category=VALUE, sw-calibration-access=READ-ONLY, type=T_M_Nm_Float32
    MTCSve_M_P1MaxTrq_ERS
      data MTCSve_M_P1MaxTrq_ERS: category=VALUE, sw-calibration-access=READ-ONLY, type=T_M_Nm_Float32
    MTCSve_M_P1MinTrq_ERS
      data MTCSve_M_P1MinTrq_ERS: category=VALUE, sw-calibration-access=READ-ONLY, type=T_M_Nm_Float32
    MTCSve_M_P3TrqMAX_HVBattMax_HVBattMin
      data MTCSve_M_P3TrqMAX_HVBattMax_HVBattMin: category=VALUE, sw-calibration-access=READ-ONLY, type=T_M_Nm_Float32
    MTCSve_M_P3TrqPropMAX_HVBattMax_HVBattMin
      data MTCSve_M_P3TrqPropMAX_HVBattMax_HVBattMin: category=VALUE, sw-calibration-access=READ-ONLY, type=T_M_Nm_Float32
    MTCSve_M_P3TrqPropMAX_HVBattMaxGenMax_HVBattMin
      data MTCSve_M_P3TrqPropMAX_HVBattMaxGenMax_HVBattMin: category=VALUE, sw-calibration-access=READ-ONLY, type=T_M_Nm_Float32
    CCAPve_Pct_ClchCmdActvRng
      data CCAPve_Pct_ClchCmdActvRng: category=VALUE, sw-calibration-access=READ-ONLY, type=T_Pct_pct_10_1_s16
    CCAPve_Pct_ClchCmdAct
      data CCAPve_Pct_ClchCmdAct: category=VALUE, sw-calibration-access=READ-ONLY, type=T_Pct_pct_10_1_s16
    CCAPve_Pct_ClchDrgPtActvRng
      data CCAPve_Pct_ClchDrgPtActvRng: category=VALUE, sw-calibration-access=READ-ONLY, type=T_Pct_pct_10_1_s16
    CCAPve_Pct_ClchDrgPtAct
      data CCAPve_Pct_ClchDrgPtAct: category=VALUE, sw-calibration-access=READ-ONLY, type=T_Pct_pct_10_1_s16
    GERCve_r_TransP1TrqRatioERS
      data GERCve_r_TransP1TrqRatioERS: category=VALUE, sw-calibration-access=READ-ONLY, type=T_r_NA_1024_1_s16
    GERCve_r_TransP3TrqRatio
      data GERCve_r_TransP3TrqRatio: category=VALUE, sw-calibration-access=READ-ONLY, type=T_r_NA_1024_1_s16
    TCAPve_M_TransWhlMaxTrqCap
      data TCAPve_M_TransWhlMaxTrqCap: category=VALUE, sw-calibration-access=READ-ONLY, type=T_M_Nm_Float32
    TCAPve_M_TransWhlMinTrqCap
      data TCAPve_M_TransWhlMinTrqCap: category=VALUE, sw-calibration-access=READ-ONLY, type=T_M_Nm_Float32
    TCAPve_M_TransP1MaxTrqCap
      data TCAPve_M_TransP1MaxTrqCap: category=VALUE, sw-calibration-access=READ-ONLY, type=T_M_Nm_32_1_s16
    TCAPve_M_TransP1MinTrqCap
      data TCAPve_M_TransP1MinTrqCap: category=VALUE, sw-calibration-access=READ-ONLY, type=T_M_Nm_32_1_s16
    DITDve_e_DrvrIntTorqDirctn
      data DITDve_e_DrvrIntTorqDirctn: category=VALUE, sw-calibration-access=READ-ONLY, type=DITDte_e_DrvrIntTorqDirctn
    VSPEve_v_DrvnWhlsSpd
      data VSPEve_v_DrvnWhlsSpd: category=VALUE, sw-calibration-access=READ-ONLY, type=T_v_kph_64_1_s16
    ACCPve_M_ZeroPedalDrvDmn
      data ACCPve_M_ZeroPedalDrvDmn: category=VALUE, sw-calibration-access=READ-ONLY, type=T_M_Nm_Float32
    PORSve_n_P1RotationalSpeed
      data PORSve_n_P1RotationalSpeed: category=VALUE, sw-calibration-access=READ-ONLY, type=T_n_rpm_1_1_s16
    TISCve_M_MinP1Trq
      data TISCve_M_MinP1Trq: category=VALUE, sw-calibration-access=READ-ONLY, type=T_M_Nm_32_1_s16
    TCAPve_M_TransP1MaxTrqCapERS
      data TCAPve_M_TransP1MaxTrqCapERS: category=VALUE, sw-calibration-access=READ-ONLY, type=T_M_Nm_32_1_s16
    TCAPve_M_TransP1MinTrqCapERS
      data TCAPve_M_TransP1MinTrqCapERS: category=VALUE, sw-calibration-access=READ-ONLY, type=T_M_Nm_32_1_s16
    GERCve_r_TransP3SpdRatio
      data GERCve_r_TransP3SpdRatio: category=VALUE, sw-calibration-access=READ-ONLY, type=T_r_NA_1024_1_s16
    MTCSve_n_P3MtrMaxSpeed
      data MTCSve_n_P3MtrMaxSpeed: category=VALUE, sw-calibration-access=READ-ONLY, type=T_n_rpm_1_1_s16
    SPARve_l_WheelRadius
      data SPARve_l_WheelRadius: category=VALUE, sw-calibration-access=READ-ONLY, type=T_l_m_1024_1_s16
    POLCve_M_P1LoadImmidiateReq
      data POLCve_M_P1LoadImmidiateReq: category=VALUE, sw-calibration-access=READ-ONLY, type=T_M_Nm_32_1_s16
    TCAPve_e_DrivelineState
      data TCAPve_e_DrivelineState: category=VALUE, sw-calibration-access=READ-ONLY, type=TCAPte_e_DrivelineState
    TTSSve_e_SpdCntrlReqMod
      data TTSSve_e_SpdCntrlReqMod: category=VALUE, sw-calibration-access=READ-ONLY, type=TTSSte_e_SpdCntrlReqMode
    TTSSve_b_ImmediateTrqLimEnable
      data TTSSve_b_ImmediateTrqLimEnable: category=BOOLEAN, sw-calibration-access=READ-ONLY, type=T_BOOLEAN
    TTSSve_b_PredictedTrqLimEnable
      data TTSSve_b_PredictedTrqLimEnable: category=BOOLEAN, sw-calibration-access=READ-ONLY, type=T_BOOLEAN
    ITCCve_b_EngMaxExtAllowed
      data ITCCve_b_EngMaxExtAllowed: category=BOOLEAN, sw-calibration-access=READ-ONLY, type=T_BOOLEAN
    ITCCve_M_EngMaxTrqExt
      data ITCCve_M_EngMaxTrqExt: category=VALUE, sw-calibration-access=READ-ONLY, type=T_M_Nm_32_1_s16
    ITCCve_M_EngMinRunTrq
      data ITCCve_M_EngMinRunTrq: category=VALUE, sw-calibration-access=READ-ONLY, type=T_M_Nm_32_1_s16
    ECOMve_b_FuelCutAllowed
      data ECOMve_b_FuelCutAllowed: category=BOOLEAN, sw-calibration-access=READ-ONLY, type=T_BOOLEAN
    EITCve_M_EnginePredictedActNoFC
      data EITCve_M_EnginePredictedActNoFC: category=VALUE, sw-calibration-access=READ-ONLY, type=T_M_Nm_32_1_s16
    ITCCve_M_EngMinRunCurrImmdTrq
      data ITCCve_M_EngMinRunCurrImmdTrq: category=VALUE, sw-calibration-access=READ-ONLY, type=T_M_Nm_32_1_s16
    GSCHve_b_GearAvailable
      data GSCHve_b_GearAvailable: category=BOOLEAN, sw-calibration-access=READ-ONLY, type=T_BOOLEAN
    GERCve_e_ActualGear
      data GERCve_e_ActualGear: category=VALUE, sw-calibration-access=READ-ONLY, type=DGPSte_e_Gear
    ITCCve_M_EngMinRunTrq_LT
      data ITCCve_M_EngMinRunTrq_LT: category=VALUE, sw-calibration-access=READ-ONLY, type=T_M_Nm_32_1_s16
    DTOSve_M_CmdPrplsFiltWhlDmnImmediate
      data DTOSve_M_CmdPrplsFiltWhlDmnImmediate: category=VALUE, sw-calibration-access=READ-ONLY, type=T_M_Nm_Float32
    DOSRve_M_ForceChargeTorque
      data DOSRve_M_ForceChargeTorque: category=VALUE, sw-calibration-access=READ-ONLY, type=T_M_Nm_32_1_s16
    FDMAve_b_ForceBrakeRegenerationTorqueOff
      data FDMAve_b_ForceBrakeRegenerationTorqueOff: category=BOOLEAN, sw-calibration-access=READ-ONLY, type=T_BOOLEAN
    SWINve_b_GearShiftActive
      data SWINve_b_GearShiftActive: category=BOOLEAN, sw-calibration-access=READ-ONLY, type=T_BOOLEAN
    DPSCve_e_VehicleReqState
      data DPSCve_e_VehicleReqState: category=VALUE, sw-calibration-access=READ-ONLY, type=DPSCte_e_VehicleModes
    PWRMve_e_SysPwrMd
      data PWRMve_e_SysPwrMd: category=VALUE, sw-calibration-access=READ-ONLY, type=PWRMte_e_SysPwrMd
    PAFCve_e_ParkLockStatus
      data PAFCve_e_ParkLockStatus: category=VALUE, sw-calibration-access=READ-ONLY, type=SWINte_e_ParkLockStatus
    FDMAve_b_ForcePropulsionAllowedToNotAllowed
      data FDMAve_b_ForcePropulsionAllowedToNotAllowed: category=BOOLEAN, sw-calibration-access=READ-ONLY, type=T_BOOLEAN
    DPSCve_e_VehicleActState
      data DPSCve_e_VehicleActState: category=VALUE, sw-calibration-access=READ-ONLY, type=DPSCte_e_VehicleModes
    ECOMve_b_FuelCutGearShiftAllowed
      data ECOMve_b_FuelCutGearShiftAllowed: category=BOOLEAN, sw-calibration-access=READ-ONLY, type=T_BOOLEAN
    DTOSve_b_FastResponseRequest
      data DTOSve_b_FastResponseRequest: category=BOOLEAN, sw-calibration-access=READ-ONLY, type=T_BOOLEAN
    MTCSve_M_P3TrqPropMAX_GenMax_HVBattMin
      data MTCSve_M_P3TrqPropMAX_GenMax_HVBattMin: category=VALUE, sw-calibration-access=READ-ONLY, type=T_M_Nm_Float32
    MTCSve_M_P3TrqMAX_HVBattMaxGenMax_HVBattMin
      data MTCSve_M_P3TrqMAX_HVBattMaxGenMax_HVBattMin: category=VALUE, sw-calibration-access=READ-ONLY, type=T_M_Nm_Float32
    MTCSve_M_P4TrqMAX_HVBattMaxGenMax_HVBattMin
      data MTCSve_M_P4TrqMAX_HVBattMaxGenMax_HVBattMin: category=VALUE, sw-calibration-access=READ-ONLY, type=T_M_Nm_Float32
    BOREve_M_MaxBoostRequest
      data BOREve_M_MaxBoostRequest: category=VALUE, sw-calibration-access=READ-ONLY, type=T_M_Nm_Float32
    MTCSve_M_P4TrqPropMAX_GenMax_HVBattMin
      data MTCSve_M_P4TrqPropMAX_GenMax_HVBattMin: category=VALUE, sw-calibration-access=READ-ONLY, type=T_M_Nm_Float32
    MTCSve_M_P4TrqPropMAX_HVBattMax_HVBattMin
      data MTCSve_M_P4TrqPropMAX_HVBattMax_HVBattMin: category=VALUE, sw-calibration-access=READ-ONLY, type=T_M_Nm_Float32
    MTCSve_M_P4TrqPropMAX_HVBattMaxGenMax_HVBattMin
      data MTCSve_M_P4TrqPropMAX_HVBattMaxGenMax_HVBattMin: category=VALUE, sw-calibration-access=READ-ONLY, type=T_M_Nm_Float32
    VSPEve_v_RearAxleWheelSpeed
      data VSPEve_v_RearAxleWheelSpeed: category=VALUE, sw-calibration-access=READ-ONLY, type=T_v_kph_64_1_s16
    GERCve_r_TransP4TrqRatio
      data GERCve_r_TransP4TrqRatio: category=VALUE, sw-calibration-access=READ-ONLY, type=T_r_NA_1024_1_s16
    MTCSve_M_P4TrqMAX_HVBattMax_HVBattMin
      data MTCSve_M_P4TrqMAX_HVBattMax_HVBattMin: category=VALUE, sw-calibration-access=READ-ONLY, type=T_M_Nm_Float32
    MTCSve_M_P3TrqMIN_HVBattMax_HVBattMin
      data MTCSve_M_P3TrqMIN_HVBattMax_HVBattMin: category=VALUE, sw-calibration-access=READ-ONLY, type=T_M_Nm_Float32
    MTCSve_M_P3TrqMIN_HVBattMaxGenMax_HVBattMin
      data MTCSve_M_P3TrqMIN_HVBattMaxGenMax_HVBattMin: category=VALUE, sw-calibration-access=READ-ONLY, type=T_M_Nm_Float32
    MTCSve_M_P3TrqPropMIN_GenMax_HVBattMin
      data MTCSve_M_P3TrqPropMIN_GenMax_HVBattMin: category=VALUE, sw-calibration-access=READ-ONLY, type=T_M_Nm_Float32
    MTCSve_M_P3TrqPropMIN_HVBattMax_HVBattMin
      data MTCSve_M_P3TrqPropMIN_HVBattMax_HVBattMin: category=VALUE, sw-calibration-access=READ-ONLY, type=T_M_Nm_Float32
    MTCSve_M_P3TrqPropMIN_HVBattMaxGenMax_HVBattMin
      data MTCSve_M_P3TrqPropMIN_HVBattMaxGenMax_HVBattMin: category=VALUE, sw-calibration-access=READ-ONLY, type=T_M_Nm_Float32
    MTCSve_M_P4TrqMIN_HVBattMax_HVBattMin
      data MTCSve_M_P4TrqMIN_HVBattMax_HVBattMin: category=VALUE, sw-calibration-access=READ-ONLY, type=T_M_Nm_Float32
    MTCSve_M_P4TrqMIN_HVBattMaxGenMax_HVBattMin
      data MTCSve_M_P4TrqMIN_HVBattMaxGenMax_HVBattMin: category=VALUE, sw-calibration-access=READ-ONLY, type=T_M_Nm_Float32
    MTCSve_M_P4TrqPropMIN_GenMax_HVBattMin
      data MTCSve_M_P4TrqPropMIN_GenMax_HVBattMin: category=VALUE, sw-calibration-access=READ-ONLY, type=T_M_Nm_Float32
    MTCSve_M_P4TrqPropMIN_HVBattMax_HVBattMin
      data MTCSve_M_P4TrqPropMIN_HVBattMax_HVBattMin: category=VALUE, sw-calibration-access=READ-ONLY, type=T_M_Nm_Float32
    MTCSve_M_P4TrqPropMIN_HVBattMaxGenMax_HVBattMin
      data MTCSve_M_P4TrqPropMIN_HVBattMaxGenMax_HVBattMin: category=VALUE, sw-calibration-access=READ-ONLY, type=T_M_Nm_Float32
    MTCSve_M_P3BrakeRegenMAXCap
      data MTCSve_M_P3BrakeRegenMAXCap: category=VALUE, sw-calibration-access=READ-ONLY, type=T_M_Nm_Float32
    MTCSve_M_P3BrakeRegenMINCap
      data MTCSve_M_P3BrakeRegenMINCap: category=VALUE, sw-calibration-access=READ-ONLY, type=T_M_Nm_Float32
    MTCSve_M_P4BrakeRegenMAXCap
      data MTCSve_M_P4BrakeRegenMAXCap: category=VALUE, sw-calibration-access=READ-ONLY, type=T_M_Nm_Float32
    MTCSve_M_P4BrakeRegenMINCap
      data MTCSve_M_P4BrakeRegenMINCap: category=VALUE, sw-calibration-access=READ-ONLY, type=T_M_Nm_Float32
    GERCve_r_TransP4SpdRatio
      data GERCve_r_TransP4SpdRatio: category=VALUE, sw-calibration-access=READ-ONLY, type=T_r_NA_1024_1_s16
    MTCSve_n_P4MtrMaxSpeed
      data MTCSve_n_P4MtrMaxSpeed: category=VALUE, sw-calibration-access=READ-ONLY, type=T_n_rpm_1_1_s16
    MTCSve_M_P3LTrqPropMAX_HVBattMaxGenMax_HVBattMin
      data MTCSve_M_P3LTrqPropMAX_HVBattMaxGenMax_HVBattMin: category=VALUE, sw-calibration-access=READ-ONLY, type=T_M_Nm_Float32
    MTCSve_M_P3LTrqPropMIN_HVBattMaxGenMax_HVBattMin
      data MTCSve_M_P3LTrqPropMIN_HVBattMaxGenMax_HVBattMin: category=VALUE, sw-calibration-access=READ-ONLY, type=T_M_Nm_Float32
    MTCSve_M_P3RTrqPropMAX_HVBattMaxGenMax_HVBattMin
      data MTCSve_M_P3RTrqPropMAX_HVBattMaxGenMax_HVBattMin: category=VALUE, sw-calibration-access=READ-ONLY, type=T_M_Nm_Float32
    MTCSve_M_P3RTrqPropMIN_HVBattMaxGenMax_HVBattMin
      data MTCSve_M_P3RTrqPropMIN_HVBattMaxGenMax_HVBattMin: category=VALUE, sw-calibration-access=READ-ONLY, type=T_M_Nm_Float32
    MTCSve_M_P4LTrqPropMAX_HVBattMaxGenMax_HVBattMin
      data MTCSve_M_P4LTrqPropMAX_HVBattMaxGenMax_HVBattMin: category=VALUE, sw-calibration-access=READ-ONLY, type=T_M_Nm_Float32
    MTCSve_M_P4LTrqPropMIN_HVBattMaxGenMax_HVBattMin
      data MTCSve_M_P4LTrqPropMIN_HVBattMaxGenMax_HVBattMin: category=VALUE, sw-calibration-access=READ-ONLY, type=T_M_Nm_Float32
    MTCSve_M_P4RTrqPropMAX_HVBattMaxGenMax_HVBattMin
      data MTCSve_M_P4RTrqPropMAX_HVBattMaxGenMax_HVBattMin: category=VALUE, sw-calibration-access=READ-ONLY, type=T_M_Nm_Float32
    MTCSve_M_P4RTrqPropMIN_HVBattMaxGenMax_HVBattMin
      data MTCSve_M_P4RTrqPropMIN_HVBattMaxGenMax_HVBattMin: category=VALUE, sw-calibration-access=READ-ONLY, type=T_M_Nm_Float32
    TCAPve_M_TransP3MtrMaxTrqCap
      data TCAPve_M_TransP3MtrMaxTrqCap: category=VALUE, sw-calibration-access=READ-ONLY, type=T_M_Nm_Float32
    TCAPve_M_TransP3MtrMinTrqCap
      data TCAPve_M_TransP3MtrMinTrqCap: category=VALUE, sw-calibration-access=READ-ONLY, type=T_M_Nm_Float32
    TCAPve_M_TransP4MtrMaxTrqCap
      data TCAPve_M_TransP4MtrMaxTrqCap: category=VALUE, sw-calibration-access=READ-ONLY, type=T_M_Nm_Float32
    TCAPve_M_TransP4MtrMinTrqCap
      data TCAPve_M_TransP4MtrMinTrqCap: category=VALUE, sw-calibration-access=READ-ONLY, type=T_M_Nm_Float32
    SWINve_M_P3LMtrSTCpbyMax
      data SWINve_M_P3LMtrSTCpbyMax: category=VALUE, sw-calibration-access=READ-ONLY, type=T_M_Nm_32_1_s16
    SWINve_M_P3LMtrSTCpbyMin
      data SWINve_M_P3LMtrSTCpbyMin: category=VALUE, sw-calibration-access=READ-ONLY, type=T_M_Nm_32_1_s16
    SWINve_M_P3RMtrSTCpbyMax
      data SWINve_M_P3RMtrSTCpbyMax: category=VALUE, sw-calibration-access=READ-ONLY, type=T_M_Nm_32_1_s16
    SWINve_M_P3RMtrSTCpbyMin
      data SWINve_M_P3RMtrSTCpbyMin: category=VALUE, sw-calibration-access=READ-ONLY, type=T_M_Nm_32_1_s16
    SWINve_M_P4LMtrSTCpbyMax
      data SWINve_M_P4LMtrSTCpbyMax: category=VALUE, sw-calibration-access=READ-ONLY, type=T_M_Nm_32_1_s16
    SWINve_M_P4LMtrSTCpbyMin
      data SWINve_M_P4LMtrSTCpbyMin: category=VALUE, sw-calibration-access=READ-ONLY, type=T_M_Nm_32_1_s16
    SWINve_M_P4RMtrSTCpbyMax
      data SWINve_M_P4RMtrSTCpbyMax: category=VALUE, sw-calibration-access=READ-ONLY, type=T_M_Nm_32_1_s16
    SWINve_M_P4RMtrSTCpbyMin
      data SWINve_M_P4RMtrSTCpbyMin: category=VALUE, sw-calibration-access=READ-ONLY, type=T_M_Nm_32_1_s16
    TGSPve_b_GearShiftUpFlag
      data TGSPve_b_GearShiftUpFlag: category=BOOLEAN, sw-calibration-access=READ-ONLY, type=T_BOOLEAN
    ADCIve_M_AdptvCruiseTorqueReq
      data ADCIve_M_AdptvCruiseTorqueReq: category=VALUE, sw-calibration-access=READ-ONLY, type=T_M_Nm_Float32
    WDMMve_b_RearMotorAvailable
      data WDMMve_b_RearMotorAvailable: category=BOOLEAN, sw-calibration-access=READ-ONLY, type=T_BOOLEAN
    STCWve_M_WhlTqDmP3CpbySTMax
      data STCWve_M_WhlTqDmP3CpbySTMax: category=VALUE, sw-calibration-access=READ-ONLY, type=T_M_Nm_Float32
    STCWve_M_WhlTqDmP3CpbySTMin
      data STCWve_M_WhlTqDmP3CpbySTMin: category=VALUE, sw-calibration-access=READ-ONLY, type=T_M_Nm_Float32
    STCWve_M_DrvrTqDmEngCpbyMax
      data STCWve_M_DrvrTqDmEngCpbyMax: category=VALUE, sw-calibration-access=READ-ONLY, type=T_M_Nm_Float32
    STCWve_M_DrvrTqDmEngCpbyMinOff
      data STCWve_M_DrvrTqDmEngCpbyMinOff: category=VALUE, sw-calibration-access=READ-ONLY, type=T_M_Nm_Float32
    STCWve_M_WhlTqDmTotCpbyMax
      data STCWve_M_WhlTqDmTotCpbyMax: category=VALUE, sw-calibration-access=READ-ONLY, type=T_M_Nm_Float32
    STCWve_M_WhlTqDmTotCpbyMin
      data STCWve_M_WhlTqDmTotCpbyMin: category=VALUE, sw-calibration-access=READ-ONLY, type=T_M_Nm_Float32
    STCWve_M_DrvrTqDmTotCpbyMax
      data STCWve_M_DrvrTqDmTotCpbyMax: category=VALUE, sw-calibration-access=READ-ONLY, type=T_M_Nm_Float32
    STCWve_M_DrvrTqDmTotCpbyMin
      data STCWve_M_DrvrTqDmTotCpbyMin: category=VALUE, sw-calibration-access=READ-ONLY, type=T_M_Nm_Float32
    STCWve_M_BrkRgnCpby
      data STCWve_M_BrkRgnCpby: category=VALUE, sw-calibration-access=READ-ONLY, type=T_M_Nm_Float32
    STCWve_M_P1Max
      data STCWve_M_P1Max: category=VALUE, sw-calibration-access=READ-ONLY, type=T_M_Nm_32_1_s16
    STCWve_M_P1Min
      data STCWve_M_P1Min: category=VALUE, sw-calibration-access=READ-ONLY, type=T_M_Nm_32_1_s16
    STCWve_M_P1MaxERS
      data STCWve_M_P1MaxERS: category=VALUE, sw-calibration-access=READ-ONLY, type=T_M_Nm_32_1_s16
    STCWve_M_P1MinERS
      data STCWve_M_P1MinERS: category=VALUE, sw-calibration-access=READ-ONLY, type=T_M_Nm_32_1_s16
    STCWve_v_P3MaxVehicleSpeed
      data STCWve_v_P3MaxVehicleSpeed: category=VALUE, sw-calibration-access=READ-ONLY, type=T_v_kph_64_1_s16
    STCWve_M_P1ImmedCapMax
      data STCWve_M_P1ImmedCapMax: category=VALUE, sw-calibration-access=READ-ONLY, type=T_M_Nm_32_1_s16
    STCWve_M_P1ImmedCapMin
      data STCWve_M_P1ImmedCapMin: category=VALUE, sw-calibration-access=READ-ONLY, type=T_M_Nm_32_1_s16
    STCWve_b_P1SysTransControlled
      data STCWve_b_P1SysTransControlled: category=BOOLEAN, sw-calibration-access=READ-ONLY, type=T_BOOLEAN
    STCWve_e_PrplsAllowed
      data STCWve_e_PrplsAllowed: category=VALUE, sw-calibration-access=READ-ONLY, type=DPSCte_e_PrplsAllowed
    STCWve_b_FuelCutAllowedPropulsion
      data STCWve_b_FuelCutAllowedPropulsion: category=BOOLEAN, sw-calibration-access=READ-ONLY, type=T_BOOLEAN
    STCWve_M_EngMaxPM_DrvrDmn
      data STCWve_M_EngMaxPM_DrvrDmn: category=VALUE, sw-calibration-access=READ-ONLY, type=T_M_Nm_Float32
    STCWve_M_FrontAxleMaxESC
      data STCWve_M_FrontAxleMaxESC: category=VALUE, sw-calibration-access=READ-ONLY, type=T_M_Nm_Float32
    STCWve_M_FrontAxleMinESC
      data STCWve_M_FrontAxleMinESC: category=VALUE, sw-calibration-access=READ-ONLY, type=T_M_Nm_Float32
    STCWve_M_RearAxleMaxESC
      data STCWve_M_RearAxleMaxESC: category=VALUE, sw-calibration-access=READ-ONLY, type=T_M_Nm_Float32
    STCWve_M_RearAxleMinESC
      data STCWve_M_RearAxleMinESC: category=VALUE, sw-calibration-access=READ-ONLY, type=T_M_Nm_Float32
    STCWve_M_SeriesModeMinWhlDmn
      data STCWve_M_SeriesModeMinWhlDmn: category=VALUE, sw-calibration-access=READ-ONLY, type=T_M_Nm_Float32
    STCWve_M_SeriesModeMaxWhlDmn
      data STCWve_M_SeriesModeMaxWhlDmn: category=VALUE, sw-calibration-access=READ-ONLY, type=T_M_Nm_Float32
    STCWve_M_MaxRearDrvDmn
      data STCWve_M_MaxRearDrvDmn: category=VALUE, sw-calibration-access=READ-ONLY, type=T_M_Nm_Float32
    STCWve_M_MinFrontDrvDmn
      data STCWve_M_MinFrontDrvDmn: category=VALUE, sw-calibration-access=READ-ONLY, type=T_M_Nm_Float32
    STCWve_M_MaxFrontDrvDmn
      data STCWve_M_MaxFrontDrvDmn: category=VALUE, sw-calibration-access=READ-ONLY, type=T_M_Nm_Float32
    STCWve_M_MinRearDrvDmn
      data STCWve_M_MinRearDrvDmn: category=VALUE, sw-calibration-access=READ-ONLY, type=T_M_Nm_Float32
    STCWve_M_DrvrTqDmEMTotCpbyMax
      data STCWve_M_DrvrTqDmEMTotCpbyMax: category=VALUE, sw-calibration-access=READ-ONLY, type=T_M_Nm_Float32
    STCWve_M_DrvrTqDmEMTotCpbyMin
      data STCWve_M_DrvrTqDmEMTotCpbyMin: category=VALUE, sw-calibration-access=READ-ONLY, type=T_M_Nm_Float32
    STCWve_v_P4MaxVehicleSpeed
      data STCWve_v_P4MaxVehicleSpeed: category=VALUE, sw-calibration-access=READ-ONLY, type=T_v_kph_64_1_s16
    STCWve_e_TrqDirFoWhlCaps
      data STCWve_e_TrqDirFoWhlCaps: category=VALUE, sw-calibration-access=READ-ONLY, type=DITDte_e_DrvrIntTorqDirctn
    STCWve_M_MaxFrontAxleForUAES
      data STCWve_M_MaxFrontAxleForUAES: category=VALUE, sw-calibration-access=READ-ONLY, type=T_M_Nm_Float32
    STCWve_M_MinFrontAxleForUAES
      data STCWve_M_MinFrontAxleForUAES: category=VALUE, sw-calibration-access=READ-ONLY, type=T_M_Nm_Float32
    STCWve_M_MaxRearAxleForUAES
      data STCWve_M_MaxRearAxleForUAES: category=VALUE, sw-calibration-access=READ-ONLY, type=T_M_Nm_Float32
    STCWve_M_MinRearAxleForUAES
      data STCWve_M_MinRearAxleForUAES: category=VALUE, sw-calibration-access=READ-ONLY, type=T_M_Nm_Float32
    STCWve_M_BrkRgnCpbyReverse
      data STCWve_M_BrkRgnCpbyReverse: category=VALUE, sw-calibration-access=READ-ONLY, type=T_M_Nm_Float32
package /STCW_pkg/STCW_dt
  impl type T_M_Nm_32_1_s16: category=VALUE, base-type=sint16, range raw -32768..32767  # Nm (newton-meters (Nm))
  unit NoUnit: factor-si-to-unit=1, offset-si-to-unit=0
  impl type T_M_Nm_Float32: category=VALUE, base-type=float32, range raw -INF..INF  # Nm (newton-meters (Nm))
  impl type T_Pct_pct_10_1_s16: category=VALUE, base-type=sint16, range raw -32768..32767  # pct (percent (%))
  impl type T_r_NA_1024_1_s16: category=VALUE, base-type=sint16, range raw -32768..32767  # NA (none)
  impl type DITDte_e_DrvrIntTorqDirctn: category=VALUE, base-type=uint8, range raw 0..255
  impl type T_v_kph_64_1_s16: category=VALUE, base-type=sint16, range raw -32768..32767  # kph (kilometers / hour (kph))
  impl type T_n_rpm_1_1_s16: category=VALUE, base-type=sint16, range raw -32768..32767  # rpm (revolutions / minute (rpm))
  impl type T_l_m_1024_1_s16: category=VALUE, base-type=sint16, range raw -32768..32767  # m (meters (m))
  impl type TCAPte_e_DrivelineState: category=VALUE, base-type=uint8, range raw 0..255
  impl type TTSSte_e_SpdCntrlReqMode: category=VALUE, base-type=uint8, range raw 0..255
  impl type T_BOOLEAN: category=VALUE, base-type=boolean, compu {0=FALSE, 1=TRUE}, range raw 0..1  # Bool
  impl type DGPSte_e_Gear: category=VALUE, base-type=uint8, range raw 0..255
  impl type DPSCte_e_VehicleModes: category=VALUE, base-type=uint8, range raw 0..255
  impl type PWRMte_e_SysPwrMd: category=VALUE, base-type=uint8, range raw 0..255
  impl type SWINte_e_ParkLockStatus: category=VALUE, base-type=uint8, range raw 0..255
  impl type DPSCte_e_PrplsAllowed: category=VALUE, base-type=uint8, range raw 0..255
  impl type T_Cnt_Num_1_1_u16: category=VALUE, base-type=uint16, range raw 0..65535  # Num (counts)
  4 x impl type:
    T_K_NA_32768_1_u16: category=VALUE, base-type=uint16, range raw 0..65535  # NA (dependent upon the gain)
    rt_Array_T_K_NA_32768_1_u16_3: category=ARRAY
      element rt_Array_T_K_NA_32768_1_u16_3: array-size=3, array-size-semantics=FIXED-SIZE, implementation-data-type=T_K_NA_32768_1_u16
    rt_Array_T_v_kph_64_1_s16_3: category=ARRAY
      element rt_Array_T_v_kph_64_1_s16_3: array-size=3, array-size-semantics=FIXED-SIZE, implementation-data-type=T_v_kph_64_1_s16
    rt_Array_T_M_Nm_32_1_s16_4: category=ARRAY
      element rt_Array_T_M_Nm_32_1_s16_4: array-size=4, array-size-semantics=FIXED-SIZE, implementation-data-type=T_M_Nm_32_1_s16
  6 x impl type:
    T_r_NA_16384_1_s16: category=VALUE, base-type=sint16, range raw -32768..32767  # NA (none)
    rt_Array_T_r_NA_16384_1_s16_7: category=ARRAY
      element rt_Array_T_r_NA_16384_1_s16_7: array-size=7, array-size-semantics=FIXED-SIZE, implementation-data-type=T_r_NA_16384_1_s16
    rt_Array_T_Pct_pct_10_1_s16_7: category=ARRAY
      element rt_Array_T_Pct_pct_10_1_s16_7: array-size=7, array-size-semantics=FIXED-SIZE, implementation-data-type=T_Pct_pct_10_1_s16
    rt_Array_T_r_NA_16384_1_s16_5: category=ARRAY
      element rt_Array_T_r_NA_16384_1_s16_5: array-size=5, array-size-semantics=FIXED-SIZE, implementation-data-type=T_r_NA_16384_1_s16
    rt_Array_T_n_rpm_1_1_s16_5: category=ARRAY
      element rt_Array_T_n_rpm_1_1_s16_5: array-size=5, array-size-semantics=FIXED-SIZE, implementation-data-type=T_n_rpm_1_1_s16
    T_r_NA_1024_1_u16: category=VALUE, base-type=uint16, range raw 0..65535  # NA (none)
  impl type rt_Array_T_r_NA_16384_1_s16_6: category=ARRAY
    element rt_Array_T_r_NA_16384_1_s16_6: array-size=6, array-size-semantics=FIXED-SIZE, implementation-data-type=T_r_NA_16384_1_s16
  impl type rt_Array_T_v_kph_64_1_s16_7: category=ARRAY
    element rt_Array_T_v_kph_64_1_s16_7: array-size=7, array-size-semantics=FIXED-SIZE, implementation-data-type=T_v_kph_64_1_s16
  impl type T_t_s_100_1_s16: category=VALUE, base-type=sint16, range raw -32768..32767  # s (seconds (s))
  impl type STCWte_e_CluToEmType: category=VALUE, base-type=uint8, range raw 0..255
  impl type rt_Array_T_M_Nm_Float32_6: category=ARRAY
    element rt_Array_T_M_Nm_Float32_6: array-size=6, array-size-semantics=FIXED-SIZE, implementation-data-type=T_M_Nm_Float32
  impl type rt_Array_T_M_Nm_Float32_7: category=ARRAY
    element rt_Array_T_M_Nm_Float32_7: array-size=7, array-size-semantics=FIXED-SIZE, implementation-data-type=T_M_Nm_Float32
  impl type rt_Array_T_M_Nm_Float32_32: category=ARRAY
    element rt_Array_T_M_Nm_Float32_32: array-size=32, array-size-semantics=FIXED-SIZE, implementation-data-type=T_M_Nm_Float32
package /STCW_pkg/STCW_dt/SwAddrMethods
  4 x sw addr method:
    CODE: section-type=CODE
    CONST: section-type=CONST
    VAR: section-type=VAR
    Adaption: section-type=VAR
package /STCW_pkg/STCW_dt/Ground
  189 x constant specification:
    STCWie_M_DrvrTqDmEMTotCpbyMax_OV: value-spec=0
    STCWie_M_DrvrTqDmEMTotCpbyMin_OV: value-spec=0
    STCWie_M_EngMaxPM_DrvrDmn_OV: value-spec=0
    STCWie_M_MaxFrontTorqueWithoutBattLIimit_OV: value-spec=0
    STCWie_M_MaxRearDrvDmn_OV: value-spec=0
    STCWie_M_MaxRearTorqueWithoutBattLIimit_OV: value-spec=0
    STCWie_M_MinFrontTorqueWithoutBattLIimit_OV: value-spec=0
    STCWie_M_MinRearDrvDmn_OV: value-spec=0
    STCWie_M_MinRearTorqueWithoutBattLIimit_OV: value-spec=0
    STCWie_M_SeriesModeMinWhlDmn_OV: value-spec=0
    STCWke_M_BrakeRegenLowPedalDsbl: value-spec=4
    STCWke_M_BrakeRegenLowPedalEnbl: value-spec=1
    STCWke_M_BrakeRegenTrqThreshold: value-spec=-50
    STCWke_M_BrkRgnCpbyOvr: value-spec=50
    STCWke_M_CpbyGradientLimit: value-spec=60
    STCWke_M_DrvrTqDmEngCpbyMaxOvr: value-spec=0
    STCWke_M_DrvrTqDmEngCpbyMinOffOv: value-spec=0
    STCWke_M_DrvrTqDmTotCpbyMax: value-spec=0
    STCWke_M_DrvrTqDmTotCpbyMinOvr: value-spec=0
    STCWke_M_FrontAxleMaxOvr: value-spec=0
    STCWke_M_FrontAxleMinOvr: value-spec=0
    STCWke_M_MaxFrontDrvDmnOvr: value-spec=0
    STCWke_M_MaxLimitFilterCloseToZeroLimit: value-spec=300
    STCWke_M_MinFrontDrvDmnOvr: value-spec=0
    STCWke_M_MinLimitFilterCloseToZeroLimit: value-spec=-300
    STCWke_M_RearAxleMaxESCOvr: value-spec=0
    STCWke_M_RearAxleMinESCOvr: value-spec=0
    STCWke_M_SeriesModeMaxWhlDmnOvr: value-spec=0
    STCWke_M_WhlTqDmP3CpbySTMaxOvr: value-spec=0
    STCWke_M_WhlTqDmP3CpbySTMinOvr: value-spec=0
    STCWke_M_WhlTqDmTotCpbyMaxOvr: value-spec=0
    STCWke_M_WhlTqDmTotCpbyMinOvr: value-spec=0
    STCWke_dM_BrakeRegenLowPedalDsbl: value-spec=-26
    STCWke_dM_BrakeRegenLowPedalEnbl: value-spec=22
    STCWke_Cnt_HoldWheelCapsAllowed: value-spec=0
    STCWke_Cnt_HoldWheelCapsHighDrive: value-spec=0
    STCWke_Cnt_HoldWheelCapsHighDriveP4: value-spec=0
    STCWke_Cnt_HoldWheelCapsHighReverse: value-spec=0
    STCWke_Cnt_HoldWheelCapsHighReverseP4: value-spec=0
    STCWke_cnt_DelayBitFlipNonCloseDrvLn: value-spec=2
    STCWke_cnt_DelayNonCloseDriveline: value-spec=2
    STCWkt_K_BrkRgnRampOut: value-spec=[0 0 1]
    STCWke_M_ImmedMinOffSwitchFrom: value-spec=-5
    STCWke_M_ImmedMinOffSwitchTo: value-spec=-3
    STCWke_M_P1ImmedCapMin_OV: value-spec=0
    STCWke_M_P1ImmedMax_OV: value-spec=0
    STCWke_M_P1MaxERSOvr: value-spec=0
    STCWke_M_P1MaxOvr: value-spec=0
    STCWke_M_P1MinERSOvr: value-spec=0
    STCWke_M_P1MinOvr: value-spec=0
    STCWke_M_P1MtrToWheelMax: value-spec=500
    STCWke_M_P1MtrToWheelMin: value-spec=0
    STCWke_dM_P1NegTrqOnRate: value-spec=-2
    STCWke_dM_P1NegTrqShutOffRate: value-spec=10
    STCWkn_M_MaxLimitFilterTorqueCloseToZero: value-spec=[50 100 200 300]
    STCWkn_M_MinLimitFilterTorqueCloseToZero: value-spec=[-300 -200 -100 -50]
    STCWkt_M_MaxLimitFilterTorqueCloseToZero: value-spec=[10 15 20 30]
    STCWkt_M_MinLimitFilterTorqueCloseToZero: value-spec=[30 20 15 10]
    STCWkn_Pct_ClchCmdCapFactorAx: value-spec=[0 5 15 20 30 40 100]
    STCWke_n_FC_Gear1Disable: value-spec=1700
    STCWke_n_FC_Gear1Enable: value-spec=2000
    STCWke_n_FC_Gear2Disable: value-spec=1700
    STCWke_n_FC_Gear2Enable: value-spec=2000
    STCWke_n_FC_Gear3Disable: value-spec=1700
    STCWke_n_FC_Gear3Enable: value-spec=2000
    STCWke_n_FC_Gear4Disable: value-spec=1700
    STCWke_n_FC_Gear4Enable: value-spec=2000
    STCWke_n_FC_Gear5Disable: value-spec=1700
    STCWke_n_FC_Gear5Enable: value-spec=2000
    STCWke_n_FC_Gear6Disable: value-spec=1700
    STCWke_n_FC_Gear6Enable: value-spec=2000
    STCWke_n_FC_GearRvrsDisable: value-spec=1700
    STCWke_n_FC_GearRvrsEnable: value-spec=2000
    STCWkn_n_MtrAMinLimSclAxis: value-spec=[-200 -20 0 100 500]
    STCWke_r_MarginForFilteringCloseToZero: value-spec=0.7001953125
    STCWke_scl_CluToEMfactor: value-spec=1
    STCWke_dr_GearAvailDsblRate: value-spec=-0.0999755859375
    STCWke_dr_GearAvailEnbleRate: value-spec=0.04998779296875
    STCWke_dr_SwitchRateDisableExtended: value-spec=0.0999755859375
    STCWke_dr_SwitchRateDisableFC: value-spec=0.0999755859375
    STCWke_dr_SwitchRateEnableExtended: value-spec=0.0999755859375
    STCWke_dr_SwitchRateEnableFC: value-spec=0.0999755859375
    STCWkn_f_CapFactAtCluPedAxis: value-spec=[-1 -0.5 0 0.2 0.5 1]
    STCWkt_f_CapFactAtCluPed: value-spec=[0 0 0.1 0.5 1 1]
    STCWkt_f_ClchCmdCapFactor: value-spec=[0 0 0.1 0.2 0.5 1 1]
    STCWkt_r_MtrAMinLimScl: value-spec=[0 0 0.2 1 1]
    STCWkt_r_PartOfTotalCpbyD: value-spec=[0 0 0 0 0 1 1]
    STCWkt_r_PartOfTotalCpbyR: value-spec=[1 1 0 0 0 0 0]
    STCWkt_r_RearPartOfTotalCpbyD: value-spec=[0 0 0 0 0 1 1]
    STCWkt_r_RearPartOfTotalCpbyR: value-spec=[1 1 0 0 0 0 0]
    STCWke_t_ParkLockInhibitDuration: value-spec=5
    STCWke_t_SafetyTorqueRampTimeDown: value-spec=0.2
    STCWke_t_SampleTime: value-spec=0.01
    STCWke_v_VehicleSpeedLimitForMaxCapabilityReduction: value-spec=0
    STCWke_v_VehicleSpeedLimitForMinCapabilityReduction: value-spec=0
    STCWkn_v_BrkRgnSpeedAxis: value-spec=[0 1 3]
    STCWkn_v_RearVehSpdX: value-spec=[-10 -1 -0.5 0 0.5 1 10]
    STCWkn_v_VehSpdX: value-spec=[-10 -1 -0.5 0 0.5 1 10]
    STCWie_e_PrplsAllowed_OV: value-spec=DPSCce_e_PrplsNotAllowed
    STCWke_e_CluToEmFactMethod: value-spec=STCWce_e_CluToEmCluCmdMap
    STCWie_b_DisableExtTrqAndFCAbritation: value-spec=1
    STCWie_b_DisableP1ImmedCaps: value-spec=1
    STCWie_b_DrvrTqDmEMTotCpbyMax_OB: value-spec=0
    STCWie_b_DrvrTqDmEMTotCpbyMin_OB: value-spec=0
    STCWie_b_EngMaxPM_DrvrDmn_OB: value-spec=0
    STCWie_b_FuelCutAllowedPropulsion_OB: value-spec=0
    STCWie_b_FuelCutAllowedPropulsion_OV: value-spec=0
    STCWie_b_MaxFrontTorqueWithoutBattLIimit_OB: value-spec=0
    STCWie_b_MaxRearDrvDmn_OB: value-spec=0
    STCWie_b_MaxRearTorqueWithoutBattLIimit_OB: value-spec=0
    STCWie_b_MinFrontTorqueWithoutBattLIimit_OB: value-spec=0
    STCWie_b_MinRearDrvDmn_OB: value-spec=0
    STCWie_b_MinRearTorqueWithoutBattLIimit_OB: value-spec=0
    STCWie_b_P1SysTransControlled_OB: value-spec=0
    STCWie_b_P1SysTransControlled_OV: value-spec=0
    STCWie_b_PrplsAllowed_OB: value-spec=0
    STCWie_b_ReplaceEngERSCapsWthCurrSpd: value-spec=1
    STCWie_b_SeriesModeMinWhlDmn_OB: value-spec=0
    STCWke_b_AlwaysEnableFuelcut: value-spec=1
    STCWke_b_BrakeRegenLowPedalEnable: value-spec=1
    STCWke_b_BrakeRegenUseZeroPedal: value-spec=1
    STCWke_b_BrkRgnCpbyOvr: value-spec=0
    STCWke_b_CluScaleActive: value-spec=0
    STCWke_b_CluScaleUseCmd: value-spec=1
    STCWke_b_DisableP1ToWheelNoGear: value-spec=0
    STCWke_b_DrvrTqDmEngCpbyMaxOvr: value-spec=0
    STCWke_b_DrvrTqDmEngCpbyMinOffOv: value-spec=0
    STCWke_b_DrvrTqDmTotCpbyMax: value-spec=0
    STCWke_b_DrvrTqDmTotCpbyMinOvr: value-spec=0
    STCWke_b_EnableFilterCloseToZero: value-spec=1
    STCWke_b_EnableSmoothCapabilityReduction: value-spec=1
    STCWke_b_EnableSmoothCapabilityReductionForDirectionChange: value-spec=1
    STCWke_b_EnblP1NegTrqAtWheelSwitchOff: value-spec=0
    STCWke_b_EnblTransLossComp: value-spec=1
    STCWke_b_FC_Gear{1..6}Enable: value-spec=1
    STCWke_b_FC_GearRvrsEnable: value-spec=1
    STCWke_b_FC_GearUndefinedEnable: value-spec=1
    STCWke_b_FrontAxleMaxOvr: value-spec=0
    STCWke_b_FrontAxleMinOvr: value-spec=0
    STCWke_b_FuelCutUseGSF_ForDrvbltRsp: value-spec=0
    STCWke_b_HoldTrqDirectioEnable: value-spec=0
    STCWke_b_IdleLimOnlyOnIsg: value-spec=0
    STCWke_b_IncludeEMMtrImmedCap: value-spec=1
    STCWke_b_InhibitBRWhenUpshift: value-spec=1
    STCWke_b_LimitBoostInTotCapability: value-spec=1
    STCWke_b_LimitP1CapWithP1Cap: value-spec=0
    STCWke_b_LimitP1CapabilityWithIdleLimit: value-spec=0
    STCWke_b_LimitWheelCapabilityWithIdleLim: value-spec=0
    STCWke_b_M18Project: value-spec=0
    STCWke_b_MaxFrontDrvDmnOvr: value-spec=0
    STCWke_b_MinFrontDrvDmnOvr: value-spec=0
    STCWke_b_NoP1ToWhlTrqInRvrsEnbl: value-spec=1
    STCWke_b_NotLimitDrvrTqDmTotMinToEngMin: value-spec=1
    STCWke_b_OnlyAllowBrakeRegenInForward: value-spec=0
    STCWke_b_P1ImmedCapMin_OB: value-spec=0
    STCWke_b_P1ImmedMax_OB: value-spec=0
    STCWke_b_P1MaxERSOvr: value-spec=0
    STCWke_b_P1MaxOvr: value-spec=0
    STCWke_b_P1MinERSOvr: value-spec=0
    STCWke_b_P1MinOvr: value-spec=0
    STCWke_b_ParkLockInhibitTimeEnable: value-spec=1
    STCWke_b_PrplsAllowedDisableDirectionDep: value-spec=1
    STCWke_b_PrplsAllowedDisableFuncActDep: value-spec=0
    STCWke_b_PrplsAllowedDisableParkLockInhibit: value-spec=1
    STCWke_b_PrplsAllowedDisablePowerModeDep: value-spec=1
    STCWke_b_RdcBrkRgnWithActCstTq: value-spec=0
    STCWke_b_RearAxleMaxESCOvr: value-spec=0
    STCWke_b_RearAxleMinESCOvr: value-spec=0
    STCWke_b_SeriesModeMaxWhlDmnOvr: value-spec=0
    STCWke_b_SignChgLockOnP1Min: value-spec=0
    STCWke_b_SubADSNegTrqInBrkRgn: value-spec=0
    STCWke_b_UseDITDForTransWHLCaps: value-spec=1
    STCWke_b_UseEMTotCapForBrkRegenCapCalc: value-spec=0
    STCWke_b_UseMinRunLTForWhl: value-spec=0
    STCWke_b_UseP1MotorERSCaps: value-spec=1
    STCWke_b_UseP3MotorForBrakeRegenCap: value-spec=1
    STCWke_b_UseP4MotorForBrakeRegenCap: value-spec=0
    STCWke_b_UsePredictedToDetectTransCntrl: value-spec=0
    STCWke_b_UsePrplsAllwd: value-spec=1
    STCWke_b_UseTotCapForBrkRegenCapCalc: value-spec=1
    STCWke_b_WhlTqDmP3CpbySTMaxOvr: value-spec=0
    STCWke_b_WhlTqDmP3CpbySTMinOvr: value-spec=0
    STCWke_b_WhlTqDmTotCpbyMaxOvr: value-spec=0
    STCWke_b_WhlTqDmTotCpbyMinOvr: value-spec=0
package /STCW_pkg/STCW_dt/ApplDataTypes
  60 x app type, all with sw-calibration-access=READ-WRITE:
    T_M_Nm_32_1_s16: category=VALUE, compu {phys=raw/32}, range phys -1024..1023.96875  # Nm (newton-meters (Nm))
    T_M_Nm_Float32: category=VALUE, compu {identical}, range phys -INF..INF  # Nm (newton-meters (Nm))
    T_Pct_pct_10_1_s16: category=VALUE, compu {phys=raw*0.1}, range phys -3276.8..3276.7000000000003  # pct (percent (%))
    T_r_NA_1024_1_s16: category=VALUE, compu {phys=raw/1024}, range phys -32..31.9990234375  # NA (none)
    DITDte_e_DrvrIntTorqDirctn: category=VALUE, compu {0=DITDce_e_Undefined, 3=DITDce_e_Reverse, 5=DITDce_e_Forward}  # Single BitFlip Protection
    T_v_kph_64_1_s16: category=VALUE, compu {phys=raw/64}, range phys -512..511.984375  # kph (kilometers / hour (kph))
    T_n_rpm_1_1_s16: category=VALUE, compu {identical}, range phys -32768..32767  # rpm (revolutions / minute (rpm))
    T_l_m_1024_1_s16: category=VALUE, compu {phys=raw/1024}, range phys -32..31.9990234375  # m (meters (m))
    TCAPte_e_DrivelineState: category=VALUE, compu {0=TCAPce_e_Open, 1=TCAPce_e_Slipping, 2=TCAPce_e_Closed, 3=TCAPce_e_Undefined}  # No BitFlip Protection
    TTSSte_e_SpdCntrlReqMode: category=VALUE, compu {0=TTSSce_e_SpdCntrlInactive, 3=TTSSce_e_SpdCntrlMaxSpeed, 5=TTSSce_e_SpdCntrlOpenLoop, 6=TTSSce_e_SpdCntrlClosedLoop}  # Single BitFlip Protection
    T_BOOLEAN: category=BOOLEAN, compu {0=FALSE, 1=TRUE}  # Bool
    DGPSte_e_Gear: category=VALUE, compu {0=DGPSce_e_UndefinedGear, 1=DGPSce_e_ReverseGear, 2=DGPSce_e_NeutralGear, 3=DGPSce_e_FirstGear, 4=DGPSce_e_SecondGear, 5=DGPSce_e_ThirdGear, 6=DGPSce_e_FourthGear, 7=DGPSce_e_FifthGear, 8=DGPSce_e_SixthGear, 9=DGPSce_e_SeventhGear, 10=DGPSce_e_EighthGear, 11=DGPSce_e_NinthGear, 12=DGPSce_e_PureElectric, 13=DGPSce_e_SerialMode, 14=DGPSce_e_ECVTMode, 15=DGPSce_e_ECVT_SportInitPosn, 16=DGPSce_e_Park}  # No BitFlip Protection
    DPSCte_e_VehicleModes: category=VALUE, compu {0=DPSCce_e_VehMd_Off, 3=DPSCce_e_VehMd_Afterrun, 5=DPSCce_e_VehMd_Postrun, 6=DPSCce_e_VehMd_Standby, 9=DPSCce_e_VehMd_Charging, 10=DPSCce_e_VehMd_Propulsion, 12=DPSCce_e_VehMd_220AcOutput}  # Single BitFlip Protection
    PWRMte_e_SysPwrMd: category=VALUE, compu {0=PWRMce_e_Lock, 1=PWRMce_e_Accessory, 2=PWRMce_e_Run, 3=PWRMce_e_Crank}  # No BitFlip Protection
    SWINte_e_ParkLockStatus: category=VALUE, compu {0=SWINce_e_ParkLockUndefined, 3=SWINce_e_ParkLockOpen, 5=SWINce_e_ParkLockMoving, 6=SWINce_e_ParkLockParked, 9=SWINce_e_ParkLockError}  # Single BitFlip Protection
    DPSCte_e_PrplsAllowed: category=VALUE, compu {0=DPSCce_e_PrplsNotAllowed, 1=DPSCce_e_PrplsAllowed}  # No BitFlip Protection
    T_M_Nm_Float32_n10000to10000: category=VALUE, compu {identical}, range phys -10000..10000  # Nm (newton-meters (Nm))
    T_M_Nm_Float32_0to6: category=VALUE, compu {identical}, range phys 0..6  # Nm (newton-meters (Nm))
    T_M_Nm_Float32_n4000to0: category=VALUE, compu {identical}, range phys -4000..0  # Nm (newton-meters (Nm))
    T_M_Nm_Float32_n5000to5000: category=VALUE, compu {identical}, range phys -5000..5000  # Nm (newton-meters (Nm))
    T_M_Nm_Float32_0to8000: category=VALUE, compu {identical}, range phys 0..8000  # Nm (newton-meters (Nm))
    T_M_Nm_Float32_0to3000: category=VALUE, compu {identical}, range phys 0..3000  # Nm (newton-meters (Nm))
    T_M_Nm_Float32_n3000to0: category=VALUE, compu {identical}, range phys -3000..0  # Nm (newton-meters (Nm))
    T_M_Nm_Float32_n2000to0: category=VALUE, compu {identical}, range phys -2000..0  # Nm (newton-meters (Nm))
    T_M_Nm_Float32_0to1000: category=VALUE, compu {identical}, range phys 0..1000  # Nm (newton-meters (Nm))
    T_Cnt_Num_1_1_u16_0to20: category=VALUE, compu {identical}, range phys 0..20  # Num (counts)
    T_Cnt_Num_1_1_u16_0to10000: category=VALUE, compu {identical}, range phys 0..10000  # Num (counts)
    Appl_STCWkt_K_BrkRgnRampOut: category=CURVE, sw-calprm-axis-set={sw-axis-index=1, category=COM_AXIS, sw-axis-grouped=Appl_STCWkn_v_BrkRgnSpeedAxis}, compu {phys=raw/32768}, range phys 0..1, sw-record-layout=Cur_u16
    Appl_STCWkn_v_BrkRgnSpeedAxis: category=COM_AXIS, sw-calprm-axis-set={sw-axis-index=1, sw-axis-individual={compu {phys=raw/64}, sw-max-axis-points=3, sw-min-axis-points=3, range phys -150..150}}, sw-record-layout=Distr_s16_M
    T_M_Nm_32_1_s16_n50to50: category=VALUE, compu {phys=raw/32}, range phys -50..50  # Nm (newton-meters (Nm))
    T_M_Nm_32_1_s16_n500to500: category=VALUE, compu {phys=raw/32}, range phys -500..500  # Nm (newton-meters (Nm))
    T_M_Nm_32_1_s16_n1000to1000: category=VALUE, compu {phys=raw/32}, range phys -1000..1000  # Nm (newton-meters (Nm))
    T_M_Nm_32_1_s16_n500to0: category=VALUE, compu {phys=raw/32}, range phys -500..0  # Nm (newton-meters (Nm))
    T_M_Nm_32_1_s16_0to500: category=VALUE, compu {phys=raw/32}, range phys 0..500  # Nm (newton-meters (Nm))
    Appl_STCWkt_M_MaxLimitFilterTorqueCloseToZero: category=CURVE, sw-calprm-axis-set={sw-axis-index=1, category=COM_AXIS, sw-axis-grouped=Appl_STCWkn_M_MaxLimitFilterTorqueCloseToZero}, compu {phys=raw/32}, range phys -1024..1023.96875, sw-record-layout=Cur_s16
    Appl_STCWkn_M_MaxLimitFilterTorqueCloseToZero: category=COM_AXIS, sw-calprm-axis-set={sw-axis-index=1, sw-axis-individual={compu {phys=raw/32}, sw-max-axis-points=4, sw-min-axis-points=4, range phys -1024..1023.96875}}, sw-record-layout=Distr_s16_M
    Appl_STCWkt_M_MinLimitFilterTorqueCloseToZero: category=CURVE, sw-calprm-axis-set={sw-axis-index=1, category=COM_AXIS, sw-axis-grouped=Appl_STCWkn_M_MinLimitFilterTorqueCloseToZero}, compu {phys=raw/32}, range phys -1024..1023.96875, sw-record-layout=Cur_s16
    Appl_STCWkn_M_MinLimitFilterTorqueCloseToZero: category=COM_AXIS, sw-calprm-axis-set={sw-axis-index=1, sw-axis-individual={compu {phys=raw/32}, sw-max-axis-points=4, sw-min-axis-points=4, range phys -1024..1023.96875}}, sw-record-layout=Distr_s16_M
    Appl_STCWkt_f_ClchCmdCapFactor: category=CURVE, sw-calprm-axis-set={sw-axis-index=1, category=COM_AXIS, sw-axis-grouped=Appl_STCWkn_Pct_ClchCmdCapFactorAx}, compu {phys=raw/16384}, range phys 0..1, sw-record-layout=Cur_s16
    Appl_STCWkn_Pct_ClchCmdCapFactorAx: category=COM_AXIS, sw-calprm-axis-set={sw-axis-index=1, sw-axis-individual={input-variable-type=T_Pct_pct_10_1_s16, compu {phys=raw*0.1}, sw-max-axis-points=7, sw-min-axis-points=7, range phys 0..100}}, sw-record-layout=Distr_s16_M
    T_n_rpm_1_1_s16_0to8000: category=VALUE, compu {identical}, range phys 0..8000  # rpm (revolutions / minute (rpm))
    Appl_STCWkt_r_MtrAMinLimScl: category=CURVE, sw-calprm-axis-set={sw-axis-index=1, category=COM_AXIS, sw-axis-grouped=Appl_STCWkn_n_MtrAMinLimSclAxis}, compu {phys=raw/16384}, range phys 0..1, sw-record-layout=Cur_s16
    Appl_STCWkn_n_MtrAMinLimSclAxis: category=COM_AXIS, sw-calprm-axis-set={sw-axis-index=1, sw-axis-individual={compu {identical}, sw-max-axis-points=5, sw-min-axis-points=5, range phys -10000..10000}}, sw-record-layout=Distr_s16_M
    T_r_NA_1024_1_u16: category=VALUE, compu {phys=raw/1024}, range phys 0..63.9990234375  # NA (none)
    T_r_NA_1024_1_u16_1to3: category=VALUE, compu {phys=raw/1024}, range phys 1..3  # NA (none)
    T_r_NA_16384_1_s16_n1to0: category=VALUE, compu {phys=raw/16384}, range phys -1..0  # NA (none)
    T_r_NA_16384_1_s16_0to1: category=VALUE, compu {phys=raw/16384}, range phys 0..1  # NA (none)
    Appl_STCWkt_f_CapFactAtCluPed: category=CURVE, sw-calprm-axis-set={sw-axis-index=1, category=COM_AXIS, sw-axis-grouped=Appl_STCWkn_f_CapFactAtCluPedAxis}, compu {phys=raw/16384}, range phys 0..1, sw-record-layout=Cur_s16
    Appl_STCWkn_f_CapFactAtCluPedAxis: category=COM_AXIS, sw-calprm-axis-set={sw-axis-index=1, sw-axis-individual={input-variable-type=T_r_NA_16384_1_s16_n1to1, compu {phys=raw/16384}, sw-max-axis-points=6, sw-min-axis-points=6, range phys -1..1}}, sw-record-layout=Distr_s16_M
    Appl_STCWkt_r_PartOfTotalCpbyD: category=CURVE, sw-calprm-axis-set={sw-axis-index=1, category=COM_AXIS, sw-axis-grouped=Appl_STCWkn_v_VehSpdX}, compu {phys=raw/16384}, range phys 0..1, sw-record-layout=Cur_s16
    Appl_STCWkn_v_VehSpdX: category=COM_AXIS, sw-calprm-axis-set=sw-axis-individual={compu {phys=raw/64}, sw-max-axis-points=7, sw-min-axis-points=7, range phys -300..300}, sw-record-layout=Distr_s16_M
    Appl_STCWkt_r_PartOfTotalCpbyR: category=CURVE, sw-calprm-axis-set={sw-axis-index=1, category=COM_AXIS, sw-axis-grouped=Appl_STCWkn_v_VehSpdX}, compu {phys=raw/16384}, range phys 0..1, sw-record-layout=Cur_s16
    Appl_STCWkt_r_RearPartOfTotalCpbyD: category=CURVE, sw-calprm-axis-set={sw-axis-index=1, category=COM_AXIS, sw-axis-grouped=Appl_STCWkn_v_RearVehSpdX}, compu {phys=raw/16384}, range phys 0..1, sw-record-layout=Cur_s16
    Appl_STCWkn_v_RearVehSpdX: category=COM_AXIS, sw-calprm-axis-set=sw-axis-individual={compu {phys=raw/64}, sw-max-axis-points=7, sw-min-axis-points=7, range phys -300..300}, sw-record-layout=Distr_s16_M
    Appl_STCWkt_r_RearPartOfTotalCpbyR: category=CURVE, sw-calprm-axis-set={sw-axis-index=1, category=COM_AXIS, sw-axis-grouped=Appl_STCWkn_v_RearVehSpdX}, compu {phys=raw/16384}, range phys 0..1, sw-record-layout=Cur_s16
    T_t_s_100_1_s16_0to327: category=VALUE, compu {phys=raw*0.01}, range phys 0..327  # s (seconds (s))
    T_t_s_100_1_s16_0to1: category=VALUE, compu {phys=raw*0.01}, range phys 0..1  # s (seconds (s))
    T_t_s_100_1_s16_0to2: category=VALUE, compu {phys=raw*0.01}, range phys 0..2  # s (seconds (s))
    STCWte_e_CluToEmType: category=VALUE, compu {0=STCWce_e_CluToEmSimpleScale, 1=STCWce_e_CluToEmCluCmdMap, 2=STCWce_e_CluToEmDragPtDist}  # No BitFlip Protection
    T_M_Nm_Float32_n8000to8000: category=VALUE, compu {identical}, range phys -8000..8000  # Nm (newton-meters (Nm))
  application array data type rt_Array_T_M_Nm_Float32_6: category=ARRAY, sw-calibration-access=READ-WRITE
    element rt_Array_T_M_Nm_Float32_6: category=VALUE, type=T_M_Nm_Float32, array-size-semantics=FIXED-SIZE, max-number-of-elements=6
  application array data type rt_Array_T_M_Nm_Float32_7: category=ARRAY, sw-calibration-access=READ-WRITE
    element rt_Array_T_M_Nm_Float32_7: category=VALUE, type=T_M_Nm_Float32, array-size-semantics=FIXED-SIZE, max-number-of-elements=7
  application array data type rt_Array_T_M_Nm_Float32_32: category=ARRAY, sw-calibration-access=READ-WRITE
    element rt_Array_T_M_Nm_Float32_32: category=VALUE, type=T_M_Nm_Float32, array-size-semantics=FIXED-SIZE, max-number-of-elements=32
  app type T_r_NA_16384_1_s16: category=VALUE, sw-calibration-access=READ-WRITE, compu {phys=raw/16384}, range phys -2..1.99993896484375  # NA (none)
  app type T_r_NA_16384_1_s16_n1to1: category=VALUE, sw-calibration-access=READ-WRITE, compu {phys=raw/16384}, range phys -1..1  # NA (none)
package /STCW_pkg/STCW_dt/ApplDataTypes/RecordLayouts
  sw record layout Cur_u16: sw-record-layout-group={short-label=Cur_u16, category=COLUMN_DIR, sw-record-layout-group-axis=0, sw-record-layout-group-index=X, sw-record-layout-group-from=1, sw-record-layout-group-to=-1, sw-record-layout-v={short-label=Val, base-type=uint16, sw-record-layout-v-axis=0, sw-record-layout-v-prop=VALUE, sw-record-layout-v-index=X}}
  sw record layout Distr_s16_M: sw-record-layout-group={short-label=X, category=INDEX_INCR, sw-record-layout-group-axis=1, sw-record-layout-group-from=1, sw-record-layout-group-to=-1, sw-record-layout-v={short-label=VALUE, base-type=sint16, sw-record-layout-v-axis=1, sw-record-layout-v-prop=VALUE}}
  sw record layout Cur_s16: sw-record-layout-group={short-label=Cur_s16, category=COLUMN_DIR, sw-record-layout-group-axis=0, sw-record-layout-group-index=X, sw-record-layout-group-from=1, sw-record-layout-group-to=-1, sw-record-layout-v={short-label=Val, base-type=sint16, sw-record-layout-v-axis=0, sw-record-layout-v-prop=VALUE, sw-record-layout-v-index=X}}
package /STCW_pkg/STCW_dt/DataTypeMappings
  data type mapping set STCWDataTypeMappingsSet
    data-type-maps:
      application-data-type=T_M_Nm_32_1_s16, implementation-data-type=T_M_Nm_32_1_s16
      application-data-type=T_M_Nm_Float32, implementation-data-type=T_M_Nm_Float32
      application-data-type=T_Pct_pct_10_1_s16, implementation-data-type=T_Pct_pct_10_1_s16
      application-data-type=T_r_NA_1024_1_s16, implementation-data-type=T_r_NA_1024_1_s16
      application-data-type=DITDte_e_DrvrIntTorqDirctn, implementation-data-type=DITDte_e_DrvrIntTorqDirctn
      application-data-type=T_v_kph_64_1_s16, implementation-data-type=T_v_kph_64_1_s16
      application-data-type=T_n_rpm_1_1_s16, implementation-data-type=T_n_rpm_1_1_s16
      application-data-type=T_l_m_1024_1_s16, implementation-data-type=T_l_m_1024_1_s16
      application-data-type=TCAPte_e_DrivelineState, implementation-data-type=TCAPte_e_DrivelineState
      application-data-type=TTSSte_e_SpdCntrlReqMode, implementation-data-type=TTSSte_e_SpdCntrlReqMode
      application-data-type=T_BOOLEAN, implementation-data-type=T_BOOLEAN
      application-data-type=DGPSte_e_Gear, implementation-data-type=DGPSte_e_Gear
      application-data-type=DPSCte_e_VehicleModes, implementation-data-type=DPSCte_e_VehicleModes
      application-data-type=PWRMte_e_SysPwrMd, implementation-data-type=PWRMte_e_SysPwrMd
      application-data-type=SWINte_e_ParkLockStatus, implementation-data-type=SWINte_e_ParkLockStatus
      application-data-type=DPSCte_e_PrplsAllowed, implementation-data-type=DPSCte_e_PrplsAllowed
      application-data-type=T_M_Nm_Float32_n10000to10000, implementation-data-type=T_M_Nm_Float32
      application-data-type=T_M_Nm_Float32_0to6, implementation-data-type=T_M_Nm_Float32
      application-data-type=T_M_Nm_Float32_n4000to0, implementation-data-type=T_M_Nm_Float32
      application-data-type=T_M_Nm_Float32_n5000to5000, implementation-data-type=T_M_Nm_Float32
      application-data-type=T_M_Nm_Float32_0to8000, implementation-data-type=T_M_Nm_Float32
      application-data-type=T_M_Nm_Float32_0to3000, implementation-data-type=T_M_Nm_Float32
      application-data-type=T_M_Nm_Float32_n3000to0, implementation-data-type=T_M_Nm_Float32
      application-data-type=T_M_Nm_Float32_n2000to0, implementation-data-type=T_M_Nm_Float32
      application-data-type=T_M_Nm_Float32_0to1000, implementation-data-type=T_M_Nm_Float32
      application-data-type=T_Cnt_Num_1_1_u16_0to20, implementation-data-type=T_Cnt_Num_1_1_u16
      application-data-type=T_Cnt_Num_1_1_u16_0to10000, implementation-data-type=T_Cnt_Num_1_1_u16
      application-data-type=Appl_STCWkt_K_BrkRgnRampOut, implementation-data-type=rt_Array_T_K_NA_32768_1_u16_3
      application-data-type=Appl_STCWkn_v_BrkRgnSpeedAxis, implementation-data-type=rt_Array_T_v_kph_64_1_s16_3
      application-data-type=T_M_Nm_32_1_s16_n50to50, implementation-data-type=T_M_Nm_32_1_s16
      application-data-type=T_M_Nm_32_1_s16_n500to500, implementation-data-type=T_M_Nm_32_1_s16
      application-data-type=T_M_Nm_32_1_s16_n1000to1000, implementation-data-type=T_M_Nm_32_1_s16
      application-data-type=T_M_Nm_32_1_s16_n500to0, implementation-data-type=T_M_Nm_32_1_s16
      application-data-type=T_M_Nm_32_1_s16_0to500, implementation-data-type=T_M_Nm_32_1_s16
      application-data-type=Appl_STCWkt_M_MaxLimitFilterTorqueCloseToZero, implementation-data-type=rt_Array_T_M_Nm_32_1_s16_4
      application-data-type=Appl_STCWkn_M_MaxLimitFilterTorqueCloseToZero, implementation-data-type=rt_Array_T_M_Nm_32_1_s16_4
      application-data-type=Appl_STCWkt_M_MinLimitFilterTorqueCloseToZero, implementation-data-type=rt_Array_T_M_Nm_32_1_s16_4
      application-data-type=Appl_STCWkn_M_MinLimitFilterTorqueCloseToZero, implementation-data-type=rt_Array_T_M_Nm_32_1_s16_4
      application-data-type=Appl_STCWkt_f_ClchCmdCapFactor, implementation-data-type=rt_Array_T_r_NA_16384_1_s16_7
      application-data-type=Appl_STCWkn_Pct_ClchCmdCapFactorAx, implementation-data-type=rt_Array_T_Pct_pct_10_1_s16_7
      application-data-type=T_n_rpm_1_1_s16_0to8000, implementation-data-type=T_n_rpm_1_1_s16
      application-data-type=Appl_STCWkt_r_MtrAMinLimScl, implementation-data-type=rt_Array_T_r_NA_16384_1_s16_5
      application-data-type=Appl_STCWkn_n_MtrAMinLimSclAxis, implementation-data-type=rt_Array_T_n_rpm_1_1_s16_5
      application-data-type=T_r_NA_1024_1_u16, implementation-data-type=T_r_NA_1024_1_u16
      application-data-type=T_r_NA_1024_1_u16_1to3, implementation-data-type=T_r_NA_1024_1_u16
      application-data-type=T_r_NA_16384_1_s16_n1to0, implementation-data-type=T_r_NA_16384_1_s16
      application-data-type=T_r_NA_16384_1_s16_0to1, implementation-data-type=T_r_NA_16384_1_s16
      application-data-type=Appl_STCWkt_f_CapFactAtCluPed, implementation-data-type=rt_Array_T_r_NA_16384_1_s16_6
      application-data-type=Appl_STCWkn_f_CapFactAtCluPedAxis, implementation-data-type=rt_Array_T_r_NA_16384_1_s16_6
      application-data-type=Appl_STCWkt_r_PartOfTotalCpbyD, implementation-data-type=rt_Array_T_r_NA_16384_1_s16_7
      application-data-type=Appl_STCWkn_v_VehSpdX, implementation-data-type=rt_Array_T_v_kph_64_1_s16_7
      application-data-type=Appl_STCWkt_r_PartOfTotalCpbyR, implementation-data-type=rt_Array_T_r_NA_16384_1_s16_7
      application-data-type=Appl_STCWkt_r_RearPartOfTotalCpbyD, implementation-data-type=rt_Array_T_r_NA_16384_1_s16_7
      application-data-type=Appl_STCWkn_v_RearVehSpdX, implementation-data-type=rt_Array_T_v_kph_64_1_s16_7
      application-data-type=Appl_STCWkt_r_RearPartOfTotalCpbyR, implementation-data-type=rt_Array_T_r_NA_16384_1_s16_7
      application-data-type=T_t_s_100_1_s16_0to327, implementation-data-type=T_t_s_100_1_s16
      application-data-type=T_t_s_100_1_s16_0to1, implementation-data-type=T_t_s_100_1_s16
      application-data-type=T_t_s_100_1_s16_0to2, implementation-data-type=T_t_s_100_1_s16
      application-data-type=STCWte_e_CluToEmType, implementation-data-type=STCWte_e_CluToEmType
      application-data-type=T_M_Nm_Float32_n8000to8000, implementation-data-type=T_M_Nm_Float32
      application-data-type=rt_Array_T_M_Nm_Float32_6, implementation-data-type=rt_Array_T_M_Nm_Float32_6
      application-data-type=rt_Array_T_M_Nm_Float32_7, implementation-data-type=rt_Array_T_M_Nm_Float32_7
      application-data-type=rt_Array_T_M_Nm_Float32_32, implementation-data-type=rt_Array_T_M_Nm_Float32_32
      application-data-type=T_r_NA_16384_1_s16, implementation-data-type=T_r_NA_16384_1_s16
      application-data-type=T_r_NA_16384_1_s16_n1to1, implementation-data-type=T_r_NA_16384_1_s16
package /STCW_pkg/STCW_imp
  swc implementation STCW: programming-language=C, sw-version=1.247.1, used-code-generator=Embedded Coder 7.3 (R2019b) 18-Jul-2019, vendor-id=0, behavior=STCW
    code-descriptors:
      code Code
        artifact-descriptors:
          short-label=STCW_c, category=SWSRC
          short-label=look1_is16lu32n16Ds32_binlcs_c, category=SWSRC
          short-label=look1_is16lu32n16ts16Ds32_binlcs_c, category=SWSRC
          short-label=look1_is16lu32n16tu16_binlcse_c, category=SWSRC
          short-label=STCW_h, category=SWHDR
          short-label=look1_is16lu32n16Ds32_binlcs_h, category=SWHDR
          short-label=look1_is16lu32n16ts16Ds32_binlcs_h, category=SWHDR
          short-label=look1_is16lu32n16tu16_binlcse_h, category=SWHDR
          short-label=rtwtypes_h, category=SWHDR
    resource consumption RsrcCons_STCW
